VERSION "created by canmatrix"

NS_ :

BS_:

BU_: TCM iBooster HCU CIM SCM Right_Hand_Control Left_Hand_Control GPS VCM IC_2 XM GMRS Radio_CANtool Diagnostic_Tool_Digital_Wrench Information_System_Controller_1 STEERING_CONTROLLER VEHICLE_SECURITY RADIO_Hub ABS Battery_Management_Cntrl_2 Battery_Management_Cntrl_1 Auxiliary_Power_Unit_2 Auxiliary_Power_Unit_1 Electric_Propulsion_Cntrl_Unit_4 Electric_Propulsion_Cntrl_Unit_3 Electric_Propulsion_Cntrl_Unit_2 Electric_Propulsion_Cntrl_Unit_1 ECM IC

BO_ 2432656774 pOperatorSwitchStatus_134: 8 Right_Hand_Control
 SG_ pOperatorButton29 : 58|2@1+ (1,0) [0.0|3.0] "" Vector__XXX
 SG_ pOperatorButton1 : 0|2@1+ (1,0) [0.0|3.0] "" Vector__XXX
 SG_ pOperatorButton2 : 2|2@1+ (1,0) [0.0|3.0] "" Vector__XXX
 SG_ pOperatorButton3 : 4|2@1+ (1,0) [0.0|3.0] "" Vector__XXX
 SG_ pOperatorButton4 : 6|2@1+ (1,0) [0.0|3.0] "" Vector__XXX
 SG_ pOperatorButton5 : 8|2@1+ (1,0) [0.0|3.0] "" Vector__XXX
 SG_ pOperatorButton6 : 10|2@1+ (1,0) [0.0|3.0] "" Vector__XXX
 SG_ pOperatorButton7 : 12|2@1+ (1,0) [0.0|3.0] "" Vector__XXX
 SG_ pOperatorButton8 : 14|2@1+ (1,0) [0.0|3.0] "" Vector__XXX
 SG_ pOperatorButton9 : 16|2@1+ (1,0) [0.0|3.0] "" Vector__XXX
 SG_ pOperatorButton10 : 18|2@1+ (1,0) [0.0|3.0] "" Vector__XXX
 SG_ pOperatorButton11 : 20|2@1+ (1,0) [0.0|3.0] "" Vector__XXX
 SG_ pOperatorButton12 : 22|2@1+ (1,0) [0.0|3.0] "" Vector__XXX
 SG_ pOperatorButton13 : 24|2@1+ (1,0) [0.0|3.0] "" Vector__XXX
 SG_ pOperatorButton14 : 26|2@1+ (1,0) [0.0|3.0] "" Vector__XXX
 SG_ pOperatorButton15 : 28|2@1+ (1,0) [0.0|3.0] "" Vector__XXX
 SG_ pOperatorButton16 : 30|2@1+ (1,0) [0.0|3.0] "" Vector__XXX
 SG_ pOperatorButton17 : 32|2@1+ (1,0) [0.0|3.0] "" Vector__XXX
 SG_ pOperatorButton18 : 34|2@1+ (1,0) [0.0|3.0] "" Vector__XXX
 SG_ pOperatorButton19 : 36|2@1+ (1,0) [0.0|3.0] "" Vector__XXX
 SG_ pOperatorButton20 : 38|2@1+ (1,0) [0.0|3.0] "" Vector__XXX
 SG_ pOperatorButton21 : 40|2@1+ (1,0) [0.0|3.0] "" Vector__XXX
 SG_ pOperatorButton22 : 42|2@1+ (1,0) [0.0|3.0] "" Vector__XXX
 SG_ pOperatorButton23 : 44|2@1+ (1,0) [0.0|3.0] "" Vector__XXX
 SG_ pOperatorButton24 : 46|2@1+ (1,0) [0.0|3.0] "" Vector__XXX
 SG_ pOperatorButton25 : 48|2@1+ (1,0) [0.0|3.0] "" Vector__XXX
 SG_ pOperatorButton26 : 50|2@1+ (1,0) [0.0|3.0] "" Vector__XXX
 SG_ pOperatorButton27 : 52|2@1+ (1,0) [0.0|3.0] "" Vector__XXX
 SG_ pOperatorButton28 : 54|2@1+ (1,0) [0.0|3.0] "" Vector__XXX
 SG_ pSideStandStatus : 56|2@1+ (1,0) [0.0|3.0] "" Vector__XXX

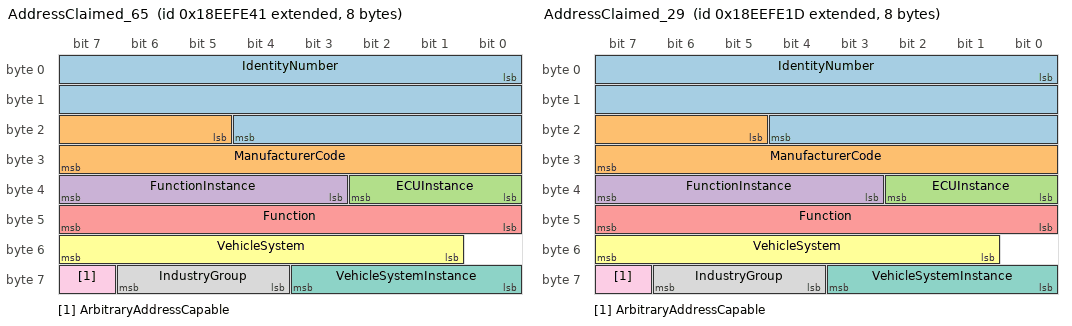
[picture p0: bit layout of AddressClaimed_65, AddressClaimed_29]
BO_ 2565799489 AddressClaimed_65: 8 Information_System_Controller_1
 SG_ IdentityNumber : 0|21@1+ (1,0) [0.0|2097151.0] "" Vector__XXX
 SG_ ManufacturerCode : 21|11@1+ (1,0) [0.0|2047.0] "" Vector__XXX
 SG_ ECUInstance : 32|3@1+ (1,0) [0.0|7.0] "" Vector__XXX
 SG_ FunctionInstance : 35|5@1+ (1,0) [0.0|31.0] "" Vector__XXX
 SG_ Function : 40|8@1+ (1,0) [0.0|255.0] "" Vector__XXX
 SG_ VehicleSystem : 49|7@1+ (1,0) [0.0|127.0] "" Vector__XXX
 SG_ VehicleSystemInstance : 56|4@1+ (1,0) [0.0|15.0] "" Vector__XXX
 SG_ IndustryGroup : 60|3@1+ (1,0) [0.0|7.0] "" Vector__XXX
 SG_ ArbitraryAddressCapable : 63|1@1+ (1,0) [0.0|0.0] "" Vector__XXX

BO_ 2565799453 AddressClaimed_29: 8 VEHICLE_SECURITY
 SG_ IdentityNumber : 0|21@1+ (1,0) [0.0|2097151.0] "" Vector__XXX
 SG_ ManufacturerCode : 21|11@1+ (1,0) [0.0|2047.0] "" Vector__XXX
 SG_ ECUInstance : 32|3@1+ (1,0) [0.0|7.0] "" Vector__XXX
 SG_ FunctionInstance : 35|5@1+ (1,0) [0.0|31.0] "" Vector__XXX
 SG_ Function : 40|8@1+ (1,0) [0.0|255.0] "" Vector__XXX
 SG_ VehicleSystem : 49|7@1+ (1,0) [0.0|127.0] "" Vector__XXX
 SG_ VehicleSystemInstance : 56|4@1+ (1,0) [0.0|15.0] "" Vector__XXX
 SG_ IndustryGroup : 60|3@1+ (1,0) [0.0|7.0] "" Vector__XXX
 SG_ ArbitraryAddressCapable : 63|1@1+ (1,0) [0.0|0.0] "" Vector__XXX

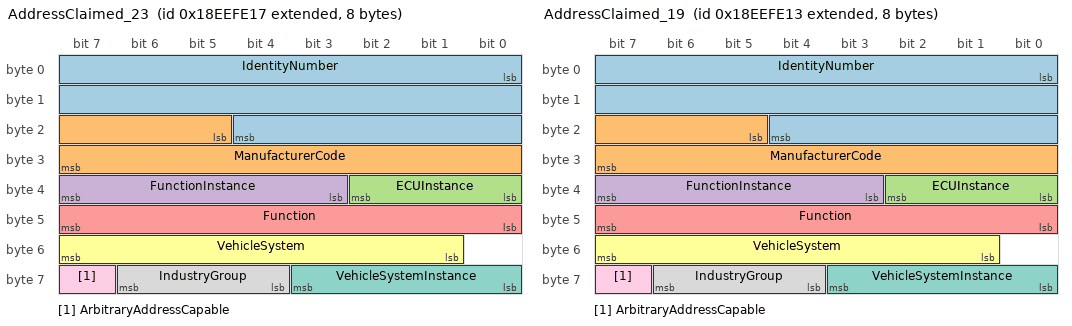
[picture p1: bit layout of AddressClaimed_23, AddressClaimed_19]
BO_ 2565799447 AddressClaimed_23: 8 IC
 SG_ IdentityNumber : 0|21@1+ (1,0) [0.0|2097151.0] "" Vector__XXX
 SG_ ManufacturerCode : 21|11@1+ (1,0) [0.0|2047.0] "" Vector__XXX
 SG_ ECUInstance : 32|3@1+ (1,0) [0.0|7.0] "" Vector__XXX
 SG_ FunctionInstance : 35|5@1+ (1,0) [0.0|31.0] "" Vector__XXX
 SG_ Function : 40|8@1+ (1,0) [0.0|255.0] "" Vector__XXX
 SG_ VehicleSystem : 49|7@1+ (1,0) [0.0|127.0] "" Vector__XXX
 SG_ VehicleSystemInstance : 56|4@1+ (1,0) [0.0|15.0] "" Vector__XXX
 SG_ IndustryGroup : 60|3@1+ (1,0) [0.0|7.0] "" Vector__XXX
 SG_ ArbitraryAddressCapable : 63|1@1+ (1,0) [0.0|0.0] "" Vector__XXX

BO_ 2565799443 AddressClaimed_19: 8 STEERING_CONTROLLER
 SG_ IdentityNumber : 0|21@1+ (1,0) [0.0|2097151.0] "" Vector__XXX
 SG_ ManufacturerCode : 21|11@1+ (1,0) [0.0|2047.0] "" Vector__XXX
 SG_ ECUInstance : 32|3@1+ (1,0) [0.0|7.0] "" Vector__XXX
 SG_ FunctionInstance : 35|5@1+ (1,0) [0.0|31.0] "" Vector__XXX
 SG_ Function : 40|8@1+ (1,0) [0.0|255.0] "" Vector__XXX
 SG_ VehicleSystem : 49|7@1+ (1,0) [0.0|127.0] "" Vector__XXX
 SG_ VehicleSystemInstance : 56|4@1+ (1,0) [0.0|15.0] "" Vector__XXX
 SG_ IndustryGroup : 60|3@1+ (1,0) [0.0|7.0] "" Vector__XXX
 SG_ ArbitraryAddressCapable : 63|1@1+ (1,0) [0.0|0.0] "" Vector__XXX

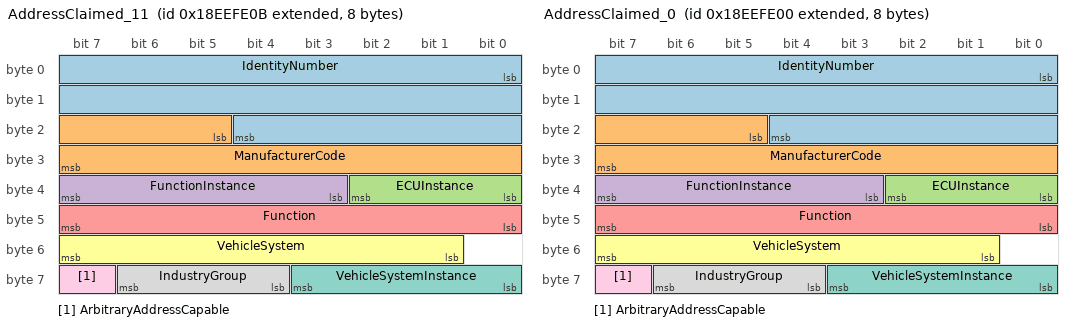
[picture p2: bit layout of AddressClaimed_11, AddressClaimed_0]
BO_ 2565799435 AddressClaimed_11: 8 ABS
 SG_ IdentityNumber : 0|21@1+ (1,0) [0.0|2097151.0] "" Auxiliary_Power_Unit_1
 SG_ ManufacturerCode : 21|11@1+ (1,0) [0.0|2047.0] "" Auxiliary_Power_Unit_1
 SG_ ECUInstance : 32|3@1+ (1,0) [0.0|7.0] "" Auxiliary_Power_Unit_1
 SG_ FunctionInstance : 35|5@1+ (1,0) [0.0|31.0] "" Auxiliary_Power_Unit_1
 SG_ Function : 40|8@1+ (1,0) [0.0|255.0] "" Auxiliary_Power_Unit_1
 SG_ VehicleSystem : 49|7@1+ (1,0) [0.0|127.0] "" Auxiliary_Power_Unit_1
 SG_ VehicleSystemInstance : 56|4@1+ (1,0) [0.0|15.0] "" Auxiliary_Power_Unit_1
 SG_ IndustryGroup : 60|3@1+ (1,0) [0.0|7.0] "" Auxiliary_Power_Unit_1
 SG_ ArbitraryAddressCapable : 63|1@1+ (1,0) [0.0|0.0] "" Auxiliary_Power_Unit_1

BO_ 2565799424 AddressClaimed_0: 8 ECM
 SG_ IdentityNumber : 0|21@1+ (1,0) [0.0|2097151.0] "" Vector__XXX
 SG_ ManufacturerCode : 21|11@1+ (1,0) [0.0|2047.0] "" Vector__XXX
 SG_ ECUInstance : 32|3@1+ (1,0) [0.0|7.0] "" Vector__XXX
 SG_ FunctionInstance : 35|5@1+ (1,0) [0.0|31.0] "" Vector__XXX
 SG_ Function : 40|8@1+ (1,0) [0.0|255.0] "" Vector__XXX
 SG_ VehicleSystem : 49|7@1+ (1,0) [0.0|127.0] "" Vector__XXX
 SG_ VehicleSystemInstance : 56|4@1+ (1,0) [0.0|15.0] "" Vector__XXX
 SG_ IndustryGroup : 60|3@1+ (1,0) [0.0|7.0] "" Vector__XXX
 SG_ ArbitraryAddressCapable : 63|1@1+ (1,0) [0.0|0.0] "" Vector__XXX

BO_ 2631794205 AntiTheftRequest_29: 8 VEHICLE_SECURITY
 SG_ EncryptionIndicatorStates : 1|2@1+ (1,0) [0.0|3.0] "" Vector__XXX
 SG_ AntiTheftDesiredExitModeStates : 3|2@1+ (1,0) [0.0|3.0] "" Vector__XXX
 SG_ AntiTheftCommandStates : 5|3@1+ (1,0) [0.0|7.0] "" Vector__XXX
 SG_ AntiTheftPasswordRepresentation : 8|56@1+ (1,0) [0.0|0.0] "" Vector__XXX

BO_ 2631794199 AntiTheftRequest_23: 8 IC
 SG_ EncryptionIndicatorStates : 1|2@1+ (1,0) [0.0|3.0] "" Vector__XXX
 SG_ AntiTheftDesiredExitModeStates : 3|2@1+ (1,0) [0.0|3.0] "" Vector__XXX
 SG_ AntiTheftCommandStates : 5|3@1+ (1,0) [0.0|7.0] "" Vector__XXX
 SG_ AntiTheftPasswordRepresentation : 8|56@1+ (1,0) [0.0|0.0] "" Vector__XXX

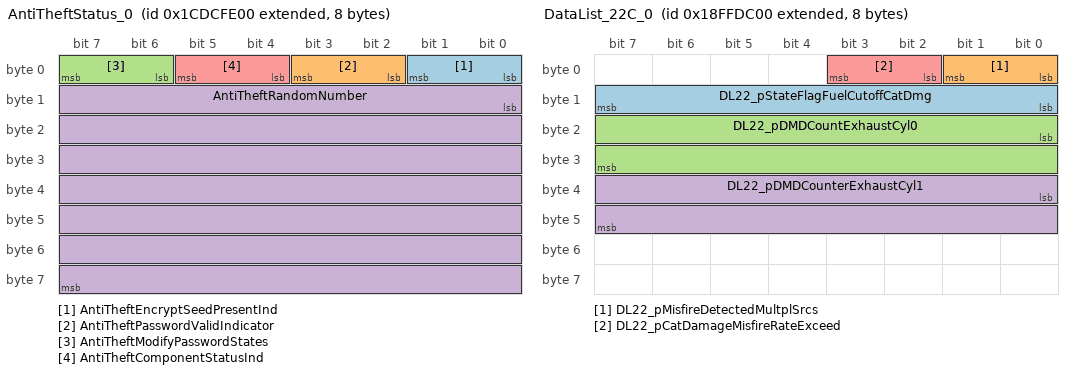
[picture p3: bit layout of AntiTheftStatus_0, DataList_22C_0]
BO_ 2631728640 AntiTheftStatus_0: 8 ECM
 SG_ AntiTheftEncryptSeedPresentInd : 0|2@1+ (1,0) [0.0|3.0] "" Vector__XXX
 SG_ AntiTheftPasswordValidIndicator : 2|2@1+ (1,0) [0.0|3.0] "" Vector__XXX
 SG_ AntiTheftModifyPasswordStates : 6|2@1+ (1,0) [0.0|3.0] "" Vector__XXX
 SG_ AntiTheftRandomNumber : 8|56@1+ (1,0) [0.0|0.0] "" Vector__XXX
 SG_ AntiTheftComponentStatusInd : 4|2@1+ (1,0) [0.0|3.0] "" Vector__XXX

BO_ 2561212031 TextDisplay_127: 8 RADIO_Hub
 SG_ TextDisplayInstructions : 0|4@1+ (1,0) [0.0|15.0] "" Vector__XXX
 SG_ TextDisplayCharacter : 24|40@1+ (1,0) [0.0|1099511627800.0] "ASCII" Vector__XXX
 SG_ TextDisplayIndex : 16|8@1+ (1,0) [0.0|250.0] "Count" Vector__XXX

BO_ 2566905088 DataList_21_00: 8 ECM
 SG_ DL21_pCyl1WeightedCatMisfireDmg : 16|16@1+ (1,0) [0.0|65535.0] "" Vector__XXX
 SG_ DL21_pCyl0WeightedCatMisfireDmg : 0|16@1+ (1,0) [0.0|65535.0] "" Vector__XXX

BO_ 2566904832 DataList_22C_0: 8 ECM
 SG_ DL22_pStateFlagFuelCutoffCatDmg : 8|8@1+ (1,0) [0.0|255.0] "Count" Vector__XXX
 SG_ DL22_pMisfireDetectedMultplSrcs : 0|2@1+ (1,0) [0.0|3.0] "" Vector__XXX
 SG_ DL22_pDMDCountExhaustCyl0 : 16|16@1+ (1,0) [0.0|65535.0] "" Vector__XXX
 SG_ DL22_pDMDCounterExhaustCyl1 : 32|16@1+ (1,0) [0.0|65535.0] "" Vector__XXX
 SG_ DL22_pCatDamageMisfireRateExceed : 2|2@1+ (1,0) [0.0|3.0] "" Vector__XXX

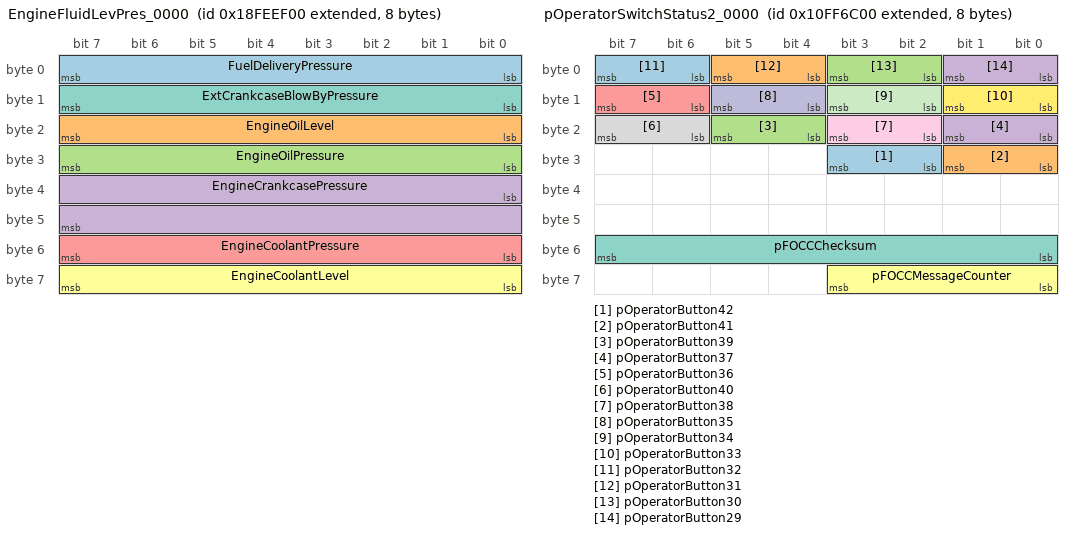
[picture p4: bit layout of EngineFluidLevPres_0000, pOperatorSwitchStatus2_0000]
BO_ 2566844160 EngineFluidLevPres_0000: 8 ECM
 SG_ FuelDeliveryPressure : 0|8@1+ (4,0) [0.0|1000.0] "kPa" Vector__XXX
 SG_ EngineOilLevel : 16|8@1+ (0.4,0) [0.0|100.0] "%" Vector__XXX
 SG_ EngineOilPressure : 24|8@1+ (4,0) [0.0|1000.0] "kPa" Vector__XXX
 SG_ EngineCrankcasePressure : 32|16@1+ (0.0078125,-250) [-250.0|251.99] "kPa" Vector__XXX
 SG_ EngineCoolantPressure : 48|8@1+ (2,0) [0.0|500.0] "kPa" Vector__XXX
 SG_ EngineCoolantLevel : 56|8@1+ (0.4,0) [0.0|100.0] "%" Vector__XXX
 SG_ ExtCrankcaseBlowByPressure : 8|8@1+ (0.05,0) [0.0|12.5] "kPa" Vector__XXX

BO_ 2432658432 pOperatorSwitchStatus2_0000: 8 ECM
 SG_ pOperatorButton42 : 26|2@1+ (1,0) [0.0|3.0] "" Vector__XXX
 SG_ pOperatorButton41 : 24|2@1+ (1,0) [0.0|3.0] "" Vector__XXX
 SG_ pOperatorButton39 : 20|2@1+ (1,0) [0.0|3.0] "" Vector__XXX
 SG_ pOperatorButton37 : 16|2@1+ (1,0) [0.0|3.0] "" Vector__XXX
 SG_ pOperatorButton36 : 14|2@1+ (1,0) [0.0|3.0] "" Vector__XXX
 SG_ pFOCCMessageCounter : 56|4@1+ (1,0) [0.0|15.0] "" Vector__XXX
 SG_ pFOCCChecksum : 48|8@1+ (1,0) [0.0|255.0] "" Vector__XXX
 SG_ pOperatorButton40 : 22|2@1+ (1,0) [0.0|3.0] "" Vector__XXX
 SG_ pOperatorButton38 : 18|2@1+ (1,0) [0.0|3.0] "" Vector__XXX
 SG_ pOperatorButton35 : 12|2@1+ (1,0) [0.0|3.0] "" Vector__XXX
 SG_ pOperatorButton34 : 10|2@1+ (1,0) [0.0|3.0] "" Vector__XXX
 SG_ pOperatorButton33 : 8|2@1+ (1,0) [0.0|3.0] "" Vector__XXX
 SG_ pOperatorButton32 : 6|2@1+ (1,0) [0.0|3.0] "" Vector__XXX
 SG_ pOperatorButton31 : 4|2@1+ (1,0) [0.0|3.0] "" Vector__XXX
 SG_ pOperatorButton30 : 2|2@1+ (1,0) [0.0|3.0] "" Vector__XXX
 SG_ pOperatorButton29 : 0|2@1+ (1,0) [0.0|3.0] "" Vector__XXX

BO_ 2633984512 pDriveSystemStatus_0: 8 ECM
 SG_ pHeatedGripEnable : 48|2@1+ (1,0) [0.0|3.0] "" Vector__XXX
 SG_ pSideStandStatus : 36|2@1+ (1,0) [0.0|3.0] "" Vector__XXX
 SG_ pTetherSwitchStatus : 46|2@1+ (1,0) [0.0|3.0] "" Vector__XXX
 SG_ pLowFuelIndicatorStatus : 10|2@1+ (1,0) [0.0|3.0] "" Vector__XXX
 SG_ pOperatorNotInOperatingStation : 38|2@1+ (1,0) [0.0|3.0] "" Vector__XXX
 SG_ pParkBrakeIndicatorStatus : 40|3@1+ (1,0) [0.0|7.0] "" Vector__XXX
 SG_ pADCRequested : 34|2@1+ (1,0) [0.0|3.0] "" Vector__XXX
 SG_ pAWDModeRequested : 32|2@1+ (1,0) [0.0|3.0] "" Vector__XXX
 SG_ pRWDModeRequested : 30|2@1+ (1,0) [0.0|3.0] "" Vector__XXX
 SG_ pTurfModeRequested : 28|2@1+ (1,0) [0.0|3.0] "" Vector__XXX
 SG_ pADCStatus : 0|2@1+ (1,0) [0.0|3.0] "" Vector__XXX
 SG_ pTreadleNeutralStatus : 2|2@1+ (1,0) [0.0|3.0] "" Vector__XXX
 SG_ pTreadleReverseStatus : 4|2@1+ (1,0) [0.0|3.0] "" Vector__XXX
 SG_ pSecurityLightStatus : 6|2@1+ (1,0) [0.0|3.0] "" Vector__XXX
 SG_ pHighBeamIndicatorStatus : 8|2@1+ (1,0) [0.0|3.0] "" Vector__XXX
 SG_ pHeatedGripsPercentage : 16|8@1+ (0.4,0) [0.0|100.0] "%" Vector__XXX
 SG_ pCruiseControlSetStatus : 24|2@1+ (1,0) [0.0|3.0] "" Vector__XXX
 SG_ pSeatBeltIndicatorStatus : 12|3@1+ (1,0) [0.0|7.0] "" Vector__XXX

BO_ 2566847511 DashDisplay_23: 8 IC
 SG_ WasherFluidLevel : 0|8@1+ (0.4,0) [0.0|100.0] "%" Vector__XXX
 SG_ FuelLevel : 8|8@1+ (0.4,0) [0.0|100.0] "%" Vector__XXX
 SG_ FuelFilterDiffPressure : 16|8@1+ (2,0) [0.0|500.0] "kPa" Vector__XXX
 SG_ EngineOilFilterDiffPressure : 24|8@1+ (0.5,0) [0.0|125.0] "kPa" Vector__XXX
 SG_ CargoAmbientTemperature : 32|16@1+ (0.03125,-273) [-273.0|1735.0] "°C" Vector__XXX

BO_ 2566845719 AmbientConditions_23: 8 IC
 SG_ DL_BarometricPressure : 0|16@1+ (0.007813,0) [0.0|511.99] "kPa" Vector__XXX
 SG_ CabInteriorTemperature : 8|16@1+ (0.03125,-273) [-273.0|1735.0] "°C" Vector__XXX
 SG_ AmbientAirTemperature : 24|16@1+ (0.03125,-273) [-273.0|1735.0] "°C" Vector__XXX
 SG_ EngineAirInletTemperature : 40|8@1+ (1,-40) [-40.0|210.0] "°C" Vector__XXX
 SG_ RoadSurfaceTemperature : 48|16@1+ (0.03125,-273) [-273.0|1734.96875] "°C" Vector__XXX

BO_ 2566847488 DashDisplay_0: 8 ECM
 SG_ WasherFluidLevel : 0|8@1+ (0.4,0) [0.0|100.0] "%" Vector__XXX
 SG_ FuelLevel : 8|8@1+ (0.4,0) [0.0|100.0] "%" Vector__XXX
 SG_ FuelFilterDiffPressure : 16|8@1+ (2,0) [0.0|500.0] "kPa" Vector__XXX
 SG_ EngineOilFilterDiffPressure : 24|8@1+ (0.5,0) [0.0|125.0] "kPa" Vector__XXX
 SG_ CargoAmbientTemperature : 32|16@1+ (0.03125,-273) [-273.0|1735.0] "°C" Vector__XXX

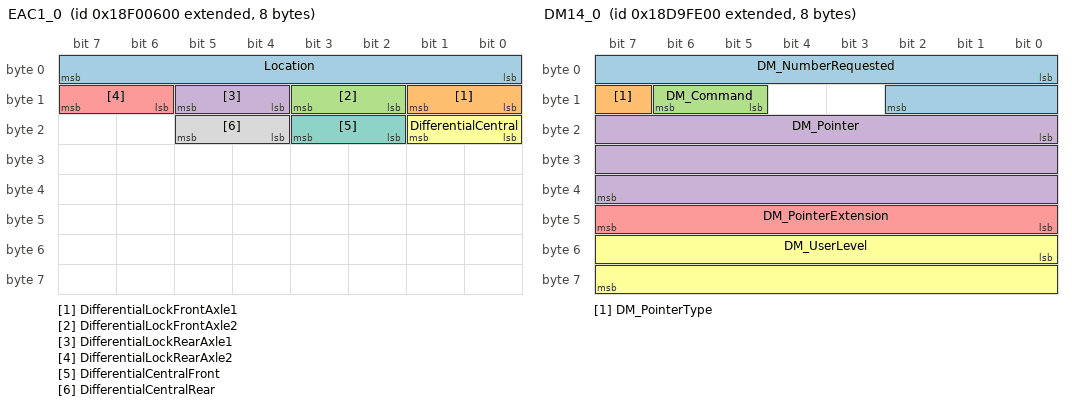
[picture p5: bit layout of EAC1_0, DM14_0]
BO_ 2565867008 EAC1_0: 8 ECM
 SG_ Location : 0|8@1+ (1,0) [0.0|255.0] "" Vector__XXX
 SG_ DifferentialLockFrontAxle1 : 8|2@1+ (1,0) [0.0|3.0] "" Vector__XXX
 SG_ DifferentialLockFrontAxle2 : 10|2@1+ (1,0) [0.0|3.0] "" Vector__XXX
 SG_ DifferentialLockRearAxle1 : 12|2@1+ (1,0) [0.0|3.0] "" Vector__XXX
 SG_ DifferentialLockRearAxle2 : 14|2@1+ (1,0) [0.0|3.0] "" Vector__XXX
 SG_ DifferentialCentral : 16|2@1+ (1,0) [0.0|3.0] "" Vector__XXX
 SG_ DifferentialCentralFront : 18|2@1+ (1,0) [0.0|3.0] "" Vector__XXX
 SG_ DifferentialCentralRear : 20|2@1+ (1,0) [0.0|3.0] "" Vector__XXX

BO_ 2566841600 EngineHoursRevolutions_0: 8 ECM
 SG_ EngTotalHoursOfOper : 0|32@1+ (0.05,0) [0.0|210554060.75] "h" Vector__XXX
 SG_ TotalEngineRevolutions : 32|32@1+ (1000,0) [0.0|4211081215000.0] "r" Vector__XXX

BO_ 2566832407 HiResVehicleDist_23: 8 IC
 SG_ HighResolTotalVehicleDistance : 0|32@1+ (0.005,0) [0.0|21055406.0] "km" Vector__XXX
 SG_ HighResolTripDistance : 32|32@1+ (0.005,0) [0.0|21055406.0] "km" Vector__XXX

BO_ 2566834688 DM1_0: 22 ECM
 SG_ DM_ProtectLampStatus : 0|2@1+ (1,0) [0.0|3.0] "" Vector__XXX
 SG_ DM_RedStopLampState : 4|2@1+ (1,0) [0.0|3.0] "" Vector__XXX
 SG_ DM_AmberWrningLmpStatus : 2|2@1+ (1,0) [0.0|3.0] "" Vector__XXX
 SG_ DM_MalfuncnIndicatorLampStatus : 6|2@1+ (1,0) [0.0|3.0] "" Vector__XXX
 SG_ DM_FlashRedStopLamp : 12|2@1+ (1,0) [0.0|3.0] "" Vector__XXX
 SG_ DM_FlashMalfuncIndicatorLamp : 14|2@1+ (1,0) [0.0|3.0] "" Vector__XXX
 SG_ DTC5 : 144|32@1+ (1,0) [0.0|4294967295.0] "" Vector__XXX
 SG_ DTC4 : 112|32@1+ (1,0) [0.0|4294967295.0] "" Vector__XXX
 SG_ DTC3 : 80|32@1+ (1,0) [0.0|4294967295.0] "" Vector__XXX
 SG_ DTC2 : 48|32@1+ (1,0) [0.0|4294967295.0] "" Vector__XXX
 SG_ DTC1 : 16|32@1+ (1,0) [0.0|4294967295.0] "" Vector__XXX
 SG_ DM_FlashProtectLamp : 8|2@1+ (1,0) [0.0|3.0] "" Vector__XXX
 SG_ DM_FlashAmberWarningLamp : 10|2@1+ (1,0) [0.0|3.0] "" Vector__XXX

BO_ 2564423168 DM14_0: 8 ECM
 SG_ DM_NumberRequested : 0|11@1+ (1,0) [0.0|2047.0] "" Vector__XXX
 SG_ DM_PointerType : 15|1@1+ (1,0) [0.0|1.0] "" Vector__XXX
 SG_ DM_Command : 13|2@1+ (1,0) [0.0|3.0] "" Vector__XXX
 SG_ DM_Pointer : 16|24@1+ (1,0) [0.0|16777215.0] "" Vector__XXX
 SG_ DM_PointerExtension : 40|8@1+ (1,0) [0.0|255.0] "" Vector__XXX
 SG_ DM_UserLevel : 48|16@1+ (1,0) [0.0|65535.0] "" Vector__XXX

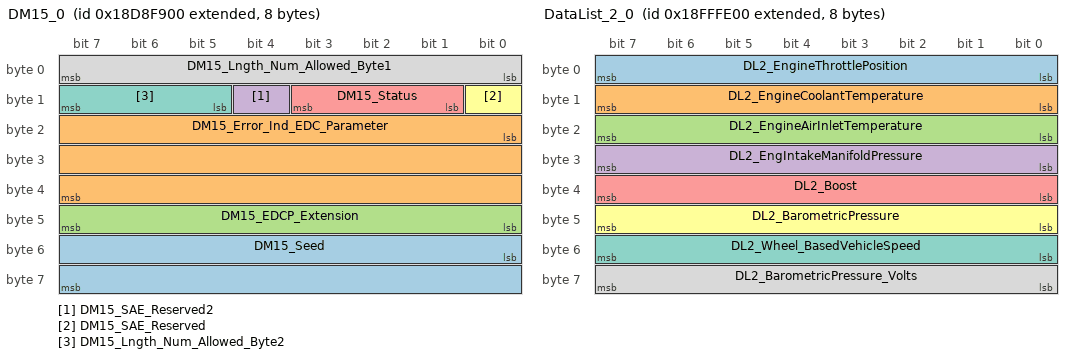
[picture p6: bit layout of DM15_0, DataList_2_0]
BO_ 2564356352 DM15_0: 8 ECM
 SG_ DM15_Seed : 48|16@1+ (1,0) [0.0|65535.0] "" Vector__XXX
 SG_ DM15_Error_Ind_EDC_Parameter : 16|24@1+ (1,0) [0.0|16777215.0] "" Vector__XXX
 SG_ DM15_EDCP_Extension : 40|8@1+ (1,0) [0.0|255.0] "" Vector__XXX
 SG_ DM15_SAE_Reserved2 : 12|1@1+ (1,0) [1.0|1.0] "" Vector__XXX
 SG_ DM15_Status : 9|3@1+ (1,0) [0.0|7.0] "" Vector__XXX
 SG_ DM15_SAE_Reserved : 8|1@1+ (1,0) [1.0|1.0] "" Vector__XXX
 SG_ DM15_Lngth_Num_Allowed_Byte2 : 13|3@1+ (1,0) [0.0|7.0] "" Vector__XXX
 SG_ DM15_Lngth_Num_Allowed_Byte1 : 0|8@1+ (1,0) [0.0|255.0] "" Vector__XXX

BO_ 2633883392 FrontWheelDriveStatus_0: 8 ECM
 SG_ FrtWheelDriveActuatorStatus : 0|2@1+ (1,0) [0.0|3.0] "" Vector__XXX

BO_ 2432656640 pOperatorSwitchStatus_0: 8 ECM
 SG_ pOperatorButton29 : 58|2@1+ (1,0) [0.0|3.0] "" Vector__XXX
 SG_ pOperatorButton1 : 0|2@1+ (1,0) [0.0|3.0] "" Vector__XXX
 SG_ pOperatorButton2 : 2|2@1+ (1,0) [0.0|3.0] "" Vector__XXX
 SG_ pOperatorButton3 : 4|2@1+ (1,0) [0.0|3.0] "" Vector__XXX
 SG_ pOperatorButton4 : 6|2@1+ (1,0) [0.0|3.0] "" Vector__XXX
 SG_ pOperatorButton5 : 8|2@1+ (1,0) [0.0|3.0] "" Vector__XXX
 SG_ pOperatorButton6 : 10|2@1+ (1,0) [0.0|3.0] "" Vector__XXX
 SG_ pOperatorButton7 : 12|2@1+ (1,0) [0.0|3.0] "" Vector__XXX
 SG_ pOperatorButton8 : 14|2@1+ (1,0) [0.0|3.0] "" Vector__XXX
 SG_ pOperatorButton9 : 16|2@1+ (1,0) [0.0|3.0] "" Vector__XXX
 SG_ pOperatorButton10 : 18|2@1+ (1,0) [0.0|3.0] "" Vector__XXX
 SG_ pOperatorButton11 : 20|2@1+ (1,0) [0.0|3.0] "" Vector__XXX
 SG_ pOperatorButton12 : 22|2@1+ (1,0) [0.0|3.0] "" Vector__XXX
 SG_ pOperatorButton13 : 24|2@1+ (1,0) [0.0|3.0] "" Vector__XXX
 SG_ pOperatorButton14 : 26|2@1+ (1,0) [0.0|3.0] "" Vector__XXX
 SG_ pOperatorButton15 : 28|2@1+ (1,0) [0.0|3.0] "" Vector__XXX
 SG_ pOperatorButton16 : 30|2@1+ (1,0) [0.0|3.0] "" Vector__XXX
 SG_ pOperatorButton17 : 32|2@1+ (1,0) [0.0|3.0] "" Vector__XXX
 SG_ pOperatorButton18 : 34|2@1+ (1,0) [0.0|3.0] "" Vector__XXX
 SG_ pOperatorButton19 : 36|2@1+ (1,0) [0.0|3.0] "" Vector__XXX
 SG_ pOperatorButton20 : 38|2@1+ (1,0) [0.0|3.0] "" Vector__XXX
 SG_ pOperatorButton21 : 40|2@1+ (1,0) [0.0|3.0] "" Vector__XXX
 SG_ pOperatorButton22 : 42|2@1+ (1,0) [0.0|3.0] "" Vector__XXX
 SG_ pOperatorButton23 : 44|2@1+ (1,0) [0.0|3.0] "" Vector__XXX
 SG_ pOperatorButton24 : 46|2@1+ (1,0) [0.0|3.0] "" Vector__XXX
 SG_ pOperatorButton25 : 48|2@1+ (1,0) [0.0|3.0] "" Vector__XXX
 SG_ pOperatorButton26 : 50|2@1+ (1,0) [0.0|3.0] "" Vector__XXX
 SG_ pOperatorButton27 : 52|2@1+ (1,0) [0.0|3.0] "" Vector__XXX
 SG_ pOperatorButton28 : 54|2@1+ (1,0) [0.0|3.0] "" Vector__XXX
 SG_ pSideStandStatus : 56|2@1+ (1,0) [0.0|3.0] "" Vector__XXX

BO_ 2365548032 pEngICS_0: 8 ECM
 SG_ pHighIdleState : 18|2@1+ (1,0) [0.0|3.0] "" Vector__XXX
 SG_ pEngineSpeed : 0|16@1+ (1,0) [0.0|64255.0] "rpm" Vector__XXX
 SG_ pStuckThrottle : 16|2@1+ (1,0) [0.0|3.0] "" Vector__XXX
 SG_ pFuelRange : 24|16@1+ (1,0) [0.0|64255.0] "km" Vector__XXX

BO_ 2566913792 DataList_1_0: 8 ECM
 SG_ DL1_EngineThrottlePosition : 0|16@1+ (0.01,0) [0.0|655.35] "V" Vector__XXX
 SG_ DL1_EngineSpeed : 16|16@1+ (1,0) [0.0|65535.0] "rpm" Vector__XXX
 SG_ DL1_EngineCoolantTemperature : 32|8@1+ (0.025,0) [0.0|6.375] "V" Vector__XXX
 SG_ DL1_EngIntakeManifoldPressure : 40|8@1+ (0.025,0) [0.0|6.375] "V" Vector__XXX
 SG_ DL1_EngineAirInletTemperature : 48|8@1+ (0.025,0) [0.0|6.375] "V" Vector__XXX
 SG_ DL1_BatteryPotential : 56|8@1+ (0.1,0) [0.0|25.5] "V" Vector__XXX

BO_ 2566913536 DataList_2_0: 8 ECM
 SG_ DL2_EngineThrottlePosition : 0|8@1+ (0.4,0) [0.0|100.0] "%" Vector__XXX
 SG_ DL2_EngineCoolantTemperature : 8|8@1+ (1,-40) [-40.0|210.0] "°C" Vector__XXX
 SG_ DL2_EngineAirInletTemperature : 16|8@1+ (1,-40) [-40.0|210.0] "°C" Vector__XXX
 SG_ DL2_EngIntakeManifoldPressure : 24|8@1+ (2,0) [0.0|500.0] "kPa" Vector__XXX
 SG_ DL2_Boost : 32|8@1+ (2,0) [0.0|500.0] "kPa" Vector__XXX
 SG_ DL2_BarometricPressure : 40|8@1+ (0.5,0) [0.0|125.0] "kPa" Vector__XXX
 SG_ DL2_Wheel_BasedVehicleSpeed : 48|8@1+ (1,0) [0.0|255.0] "km/h" Vector__XXX
 SG_ DL2_BarometricPressure_Volts : 56|8@1+ (0.025,0) [0.0|6.375] "V" Vector__XXX

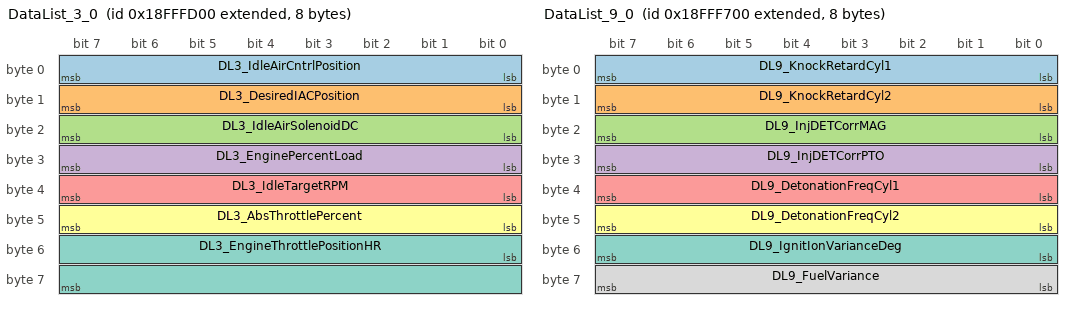
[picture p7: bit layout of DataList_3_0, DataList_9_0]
BO_ 2566913280 DataList_3_0: 8 ECM
 SG_ DL3_IdleAirCntrlPosition : 0|8@1+ (1,0) [0.0|255.0] "Step" Vector__XXX
 SG_ DL3_DesiredIACPosition : 8|8@1+ (1,0) [0.0|255.0] "Step" Vector__XXX
 SG_ DL3_IdleAirSolenoidDC : 16|8@1+ (0.4,0) [0.0|102.0] "%" Vector__XXX
 SG_ DL3_EnginePercentLoad : 24|8@1+ (0.4,0) [0.0|102.0] "%" Vector__XXX
 SG_ DL3_IdleTargetRPM : 32|8@1+ (10,0) [0.0|2550.0] "RPM" Vector__XXX
 SG_ DL3_AbsThrottlePercent : 40|8@1+ (0.4,0) [0.0|102.0] "%" Vector__XXX
 SG_ DL3_EngineThrottlePositionHR : 48|16@1+ (0.001,0) [0.0|65.535] "V" Vector__XXX

BO_ 2566911744 DataList_9_0: 8 ECM
 SG_ DL9_KnockRetardCyl1 : 0|8@1+ (1,0) [0.0|255.0] "Deg" Vector__XXX
 SG_ DL9_KnockRetardCyl2 : 8|8@1+ (1,0) [0.0|255.0] "Deg" Vector__XXX
 SG_ DL9_InjDETCorrMAG : 16|8@1+ (0.1,100) [100.0|125.5] "%" Vector__XXX
 SG_ DL9_InjDETCorrPTO : 24|8@1+ (0.1,100) [100.0|125.5] "%" Vector__XXX
 SG_ DL9_DetonationFreqCyl1 : 32|8@1+ (0.4,0) [0.0|102.0] "%" Vector__XXX
 SG_ DL9_DetonationFreqCyl2 : 40|8@1+ (0.4,0) [0.0|102.0] "%" Vector__XXX
 SG_ DL9_IgnitIonVarianceDeg : 48|8@1+ (0.2,-10) [-10.0|41.0] "Deg" Vector__XXX
 SG_ DL9_FuelVariance : 56|8@1+ (1,0) [0.0|255.0] "%" Vector__XXX

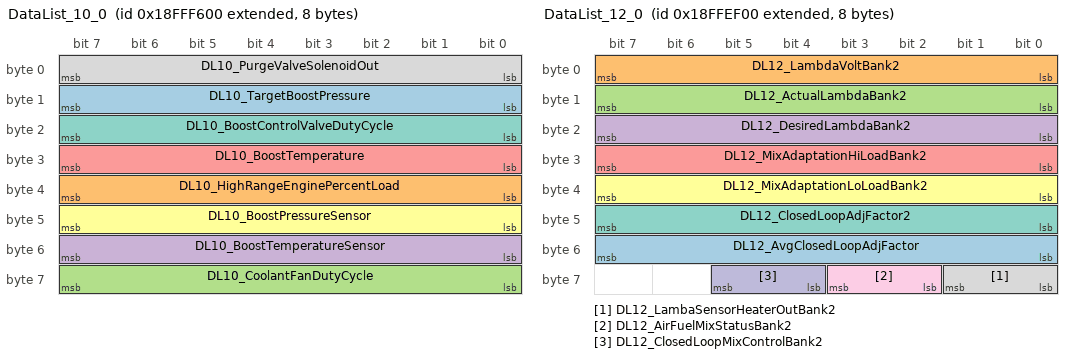
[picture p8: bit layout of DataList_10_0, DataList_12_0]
BO_ 2566911488 DataList_10_0: 8 ECM
 SG_ DL10_TargetBoostPressure : 8|8@1+ (2,0) [0.0|510.0] "kPa" Vector__XXX
 SG_ DL10_HighRangeEnginePercentLoad : 32|8@1+ (2,0) [0.0|510.0] "%" Vector__XXX
 SG_ DL10_CoolantFanDutyCycle : 56|8@1+ (0.4,0) [0.0|102.0] "%" Vector__XXX
 SG_ DL10_BoostTemperatureSensor : 48|8@1+ (0.025,0) [0.0|6.375] "Volts" Vector__XXX
 SG_ DL10_BoostTemperature : 24|8@1+ (1,-40) [-40.0|215.0] "degC" Vector__XXX
 SG_ DL10_BoostPressureSensor : 40|8@1+ (0.025,0) [0.0|6.375] "Volts" Vector__XXX
 SG_ DL10_BoostControlValveDutyCycle : 16|8@1+ (0.4,0) [0.0|102.0] "%" Vector__XXX
 SG_ DL10_PurgeValveSolenoidOut : 0|8@1+ (0.4,0) [0.0|102.0] "%" Vector__XXX

BO_ 2566909952 DataList_11_0: 8 ECM
 SG_ DL11_InterFanDriver1DutyCycle : 48|8@1+ (0.4,0) [0.0|102.0] "%" Vector__XXX
 SG_ DL11_EngineOilPressureSensor : 40|8@1+ (0.025,0) [0.0|6.375] "Volts" Vector__XXX
 SG_ DL11_EngineOilPressure : 32|8@1+ (4,0) [0.0|1020.0] "kPa" Vector__XXX
 SG_ DL11_EngRunTime : 0|16@1+ (2,0) [0.0|131070.0] "Min" Vector__XXX
 SG_ DL11_EngRunTimeKeyOn : 16|16@1+ (2,0) [0.0|131070.0] "Min" Vector__XXX

BO_ 2566909696 DataList_12_0: 8 ECM
 SG_ DL12_AvgClosedLoopAdjFactor : 48|8@1+ (0.0078125,0) [0.0|1.9921875] "" Vector__XXX
 SG_ DL12_LambdaVoltBank2 : 0|8@1+ (0.02,0) [0.0|5.0] "V" Vector__XXX
 SG_ DL12_ActualLambdaBank2 : 8|8@1+ (0.0078125,0) [0.0|1.95] "Ratio" Vector__XXX
 SG_ DL12_DesiredLambdaBank2 : 16|8@1+ (0.0078125,0) [0.0|1.9921875] "Ratio" Vector__XXX
 SG_ DL12_MixAdaptationHiLoadBank2 : 24|8@1+ (0.0078125,0) [0.0|1.9921875] "" Vector__XXX
 SG_ DL12_MixAdaptationLoLoadBank2 : 32|8@1+ (1,0) [0.0|0.0] "" Vector__XXX
 SG_ DL12_ClosedLoopAdjFactor2 : 40|8@1+ (0.0078125,0) [0.0|1.9921875] "Ratio" Vector__XXX
 SG_ DL12_LambaSensorHeaterOutBank2 : 56|2@1+ (1,0) [0.0|3.0] "" Vector__XXX
 SG_ DL12_AirFuelMixStatusBank2 : 58|2@1+ (1,0) [0.0|3.0] "" Vector__XXX
 SG_ DL12_ClosedLoopMixControlBank2 : 60|2@1+ (1,0) [0.0|3.0] "" Vector__XXX

BO_ 2566909440 DataList_13_0: 8 ECM
 SG_ DL13_PortInjector1Time : 0|16@1+ (1,0) [0.0|65535.0] "us" Vector__XXX
 SG_ DL13_CaseInjector1Time : 16|16@1+ (1,0) [0.0|65535.0] "us" Vector__XXX
 SG_ DL13_Cyl1IgnTiming : 32|8@1+ (1,-125) [-125.0|130.0] "Deg-BTDC" Vector__XXX
 SG_ DL13_Cyl1BaseIgnTiming : 40|8@1+ (1,-125) [-125.0|130.0] "Deg-BTDC" Vector__XXX
 SG_ DL13_Cyl1IgnCoilDwell : 48|16@1+ (1,0) [0.0|65535.0] "us" Vector__XXX

BO_ 2566909184 DataList_14_0: 8 ECM
 SG_ DL14_PortInjector2Time : 0|16@1+ (1,0) [0.0|65535.0] "us" Vector__XXX
 SG_ DL14_CaseInjector2Time : 16|16@1+ (1,0) [0.0|65535.0] "us" Vector__XXX
 SG_ DL14_Cyl2IgnTiming : 32|8@1+ (1,-125) [-125.0|130.0] "Deg-BTDC" Vector__XXX
 SG_ DL14_Cyl2BaseIgnTiming : 40|8@1+ (1,-125) [-125.0|130.0] "Deg-BTDC" Vector__XXX
 SG_ DL14_Cyl2IgnCoilDwell : 48|16@1+ (1,0) [0.0|65535.0] "us" Vector__XXX

BO_ 2566908928 DataList_15_0: 8 ECM
 SG_ DL15_ExhaustValveSetPWM : 32|8@1+ (0.4,0) [0.0|102.0] "%" Vector__XXX
 SG_ DL15_ExhaustTemperature : 0|16@1+ (1,0) [0.0|65535.0] "°C" Vector__XXX
 SG_ DL15_InjectorIgnitionSupplyVolt : 16|8@1+ (0.1,0) [0.0|25.5] "V" Vector__XXX
 SG_ DL15_ElecStartOptBattVolt : 24|8@1+ (0.1,0) [0.0|25.5] "V" Vector__XXX

BO_ 2566908672 DataList_16_0: 8 ECM
 SG_ DL16_PedalPosSensor1 : 0|16@1+ (0.01,0) [0.0|655.35] "V" Vector__XXX
 SG_ DL16_PedalPosSensor2 : 16|16@1+ (0.01,0) [0.0|655.35] "V" Vector__XXX

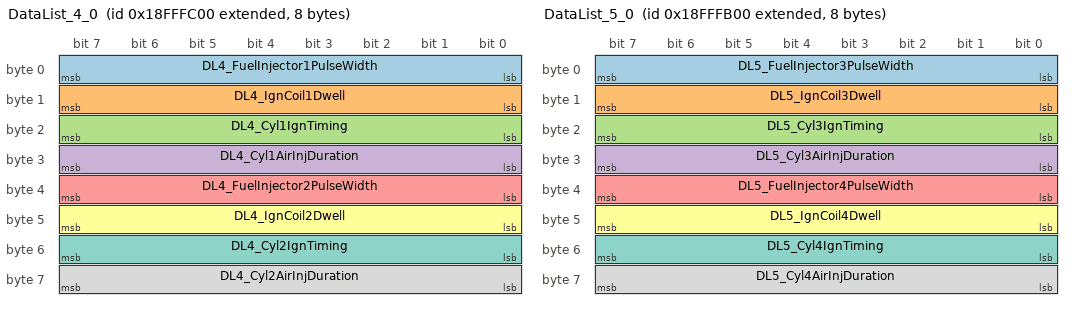
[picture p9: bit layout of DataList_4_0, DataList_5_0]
BO_ 2566913024 DataList_4_0: 8 ECM
 SG_ DL4_FuelInjector1PulseWidth : 0|8@1+ (1,0) [0.0|255.0] "ms" Vector__XXX
 SG_ DL4_IgnCoil1Dwell : 8|8@1+ (0.1,0) [0.0|25.5] "ms" Vector__XXX
 SG_ DL4_Cyl1IgnTiming : 16|8@1+ (1,-128) [-128.0|127.0] "Deg" Vector__XXX
 SG_ DL4_Cyl1AirInjDuration : 24|8@1+ (1,0) [0.0|255.0] "ms" Vector__XXX
 SG_ DL4_FuelInjector2PulseWidth : 32|8@1+ (1,0) [0.0|255.0] "ms" Vector__XXX
 SG_ DL4_IgnCoil2Dwell : 40|8@1+ (0.1,0) [0.0|25.5] "ms" Vector__XXX
 SG_ DL4_Cyl2IgnTiming : 48|8@1+ (1,-128) [-128.0|127.0] "Deg" Vector__XXX
 SG_ DL4_Cyl2AirInjDuration : 56|8@1+ (1,0) [0.0|255.0] "ms" Vector__XXX

BO_ 2566912768 DataList_5_0: 8 ECM
 SG_ DL5_FuelInjector3PulseWidth : 0|8@1+ (1,0) [0.0|255.0] "ms" Vector__XXX
 SG_ DL5_IgnCoil3Dwell : 8|8@1+ (0.1,0) [0.0|25.5] "ms" Vector__XXX
 SG_ DL5_Cyl3IgnTiming : 16|8@1+ (1,-128) [-128.0|127.0] "Deg" Vector__XXX
 SG_ DL5_Cyl3AirInjDuration : 24|8@1+ (1,0) [0.0|255.0] "ms" Vector__XXX
 SG_ DL5_FuelInjector4PulseWidth : 32|8@1+ (1,0) [0.0|255.0] "ms" Vector__XXX
 SG_ DL5_IgnCoil4Dwell : 40|8@1+ (0.1,0) [0.0|25.5] "ms" Vector__XXX
 SG_ DL5_Cyl4IgnTiming : 48|8@1+ (1,-128) [-128.0|127.0] "Deg" Vector__XXX
 SG_ DL5_Cyl4AirInjDuration : 56|8@1+ (1,0) [0.0|255.0] "ms" Vector__XXX

BO_ 2566912512 DataList_6_0: 8 ECM
 SG_ DL6_TwoSpdShftCoilDutyCycle : 48|8@1+ (0.4,0) [0.0|100.0] "%" Vector__XXX
 SG_ DL6_PTOSpeed : 32|16@1+ (1,0) [0.0|65535.0] "RPM" Vector__XXX
 SG_ DL6_GearVolts : 0|8@1+ (0.1,0) [0.0|25.5] "V" Vector__XXX
 SG_ DL6_RolloverVolts : 8|8@1+ (0.025,0) [0.0|6.375] "V" Vector__XXX
 SG_ DL6_ThrottleReleaseInputVolts : 16|8@1+ (0.1,0) [0.0|25.5] "V" Vector__XXX
 SG_ DL6_FuelTypeSensorVolts : 24|8@1+ (0.1,0) [0.0|25.5] "V" Vector__XXX

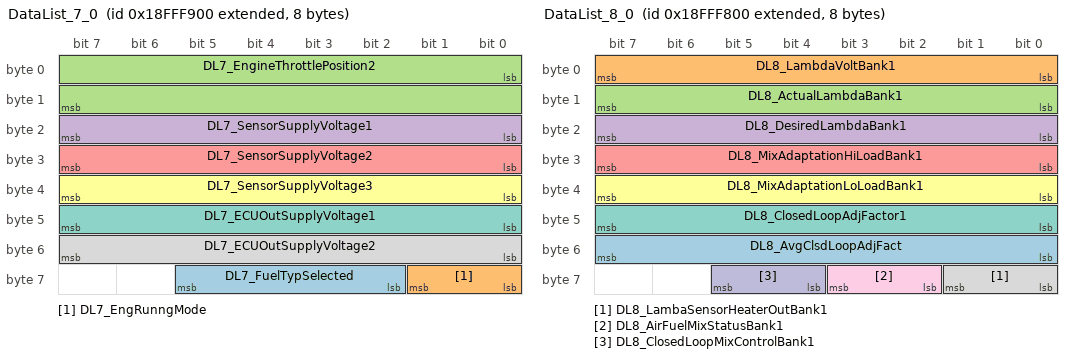
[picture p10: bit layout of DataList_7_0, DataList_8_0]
BO_ 2566912256 DataList_7_0: 8 ECM
 SG_ DL7_FuelTypSelected : 58|4@1+ (1,0) [0.0|15.0] "" Vector__XXX
 SG_ DL7_EngRunngMode : 56|2@1- (1,0) [0.0|3.0] "" Vector__XXX
 SG_ DL7_EngineThrottlePosition2 : 0|16@1+ (0.01,0) [0.0|655.35] "V" Vector__XXX
 SG_ DL7_SensorSupplyVoltage1 : 16|8@1+ (0.05,0) [0.0|12.75] "V" Vector__XXX
 SG_ DL7_SensorSupplyVoltage2 : 24|8@1+ (0.05,0) [0.0|12.75] "V" Vector__XXX
 SG_ DL7_SensorSupplyVoltage3 : 32|8@1+ (0.05,0) [0.0|12.75] "V" Vector__XXX
 SG_ DL7_ECUOutSupplyVoltage1 : 40|8@1+ (0.05,0) [0.0|12.75] "V" Vector__XXX
 SG_ DL7_ECUOutSupplyVoltage2 : 48|8@1+ (0.05,0) [0.0|12.75] "V" Vector__XXX

BO_ 2566912000 DataList_8_0: 8 ECM
 SG_ DL8_AvgClsdLoopAdjFact : 48|8@1+ (0.0078125,0) [0.0|1.9921875] "Ratio" Vector__XXX
 SG_ DL8_LambdaVoltBank1 : 0|8@1+ (0.02,0) [0.0|5.1] "" Vector__XXX
 SG_ DL8_ActualLambdaBank1 : 8|8@1+ (0.0078125,0) [0.0|1.9921875] "Ratio" Vector__XXX
 SG_ DL8_DesiredLambdaBank1 : 16|8@1+ (0.0078125,0) [0.0|1.9921875] "Ratio" Vector__XXX
 SG_ DL8_MixAdaptationHiLoadBank1 : 24|8@1+ (0.0078125,0) [0.0|1.9921875] "" Vector__XXX
 SG_ DL8_MixAdaptationLoLoadBank1 : 32|8@1+ (0.0078125,0) [0.0|1.9921875] "" Vector__XXX
 SG_ DL8_ClosedLoopAdjFactor1 : 40|8@1+ (0.0078125,0) [0.0|1.9921875] "Ratio" Vector__XXX
 SG_ DL8_LambaSensorHeaterOutBank1 : 56|2@1+ (1,0) [0.0|3.0] "" Vector__XXX
 SG_ DL8_AirFuelMixStatusBank1 : 58|2@1+ (1,0) [0.0|3.0] "" Vector__XXX
 SG_ DL8_ClosedLoopMixControlBank1 : 60|2@1+ (1,0) [0.0|3.0] "" Vector__XXX

BO_ 2566911232 FlagItems_1_0: 8 ECM
 SG_ FI1_IntercoolerPumpDriverCircuit : 46|2@1+ (1,0) [0.0|3.0] "" Vector__XXX
 SG_ FI1_FuelPullSolenoidStatus : 60|2@1+ (1,0) [0.0|3.0] "" Vector__XXX
 SG_ FI1_ClutchSwitchInput2 : 62|2@1+ (1,0) [0.0|3.0] "" Vector__XXX
 SG_ FI1_FuelPumpDriverCkt : 0|2@1+ (1,0) [0.0|3.0] "" Vector__XXX
 SG_ FI1_RolloverSwitch : 2|2@1+ (1,0) [0.0|3.0] "" Vector__XXX
 SG_ FI1_CrankSensorSignal : 4|2@1+ (1,0) [0.0|3.0] "" Vector__XXX
 SG_ FI1_CamSensorSignal : 6|2@1+ (1,0) [0.0|3.0] "" Vector__XXX
 SG_ FI1_RPMLimitActive : 8|2@1+ (1,0) [0.0|3.0] "" Vector__XXX
 SG_ FI1_IdleSwitch : 10|2@1+ (1,0) [0.0|3.0] "" Vector__XXX
 SG_ FI1_CycleSynchro : 12|2@1+ (1,0) [0.0|3.0] "" Vector__XXX
 SG_ FI1_IdleSpeedControlStatus : 14|2@1+ (1,0) [0.0|3.0] "" Vector__XXX
 SG_ FI1_IgnitionSwitchInput : 16|2@1+ (1,0) [0.0|3.0] "" Vector__XXX
 SG_ FI1_RunStopSwitchInput : 18|2@1+ (1,0) [0.0|3.0] "" Vector__XXX
 SG_ FI1_StartSwitchInput : 20|2@1+ (1,0) [0.0|3.0] "" Vector__XXX
 SG_ FI1_ThrottleSafetySwInput : 22|2@1+ (1,0) [0.0|3.0] "" Vector__XXX
 SG_ FI1_FanRelayOutput : 24|2@1+ (1,0) [0.0|3.0] "" Vector__XXX
 SG_ FI1_IntercoolerFanOutput : 26|2@1+ (1,0) [0.0|3.0] "" Vector__XXX
 SG_ FI1_ReverseAlarmOutput : 28|2@1+ (1,0) [0.0|3.0] "" Vector__XXX
 SG_ FI1_MainRelayOutput : 30|2@1+ (1,0) [0.0|3.0] "" Vector__XXX
 SG_ FI1_StartSolenoidOutput : 32|2@1+ (1,0) [0.0|3.0] "" Vector__XXX
 SG_ FI1_IgnitionRelayOutput : 34|2@1+ (1,0) [0.0|3.0] "" Vector__XXX
 SG_ FI1_ChassisRelayOutput : 36|2@1+ (1,0) [0.0|3.0] "" Vector__XXX
 SG_ FI1_StarterEnableOutput : 38|2@1+ (1,0) [0.0|3.0] "" Vector__XXX
 SG_ FI1_ExhaustValveOutput : 40|2@1+ (1,0) [0.0|3.0] "" Vector__XXX
 SG_ FI1_BatteryChargeRelayOutput : 42|2@1+ (1,0) [0.0|3.0] "" Vector__XXX
 SG_ FI1_HeaterAccRelay : 44|2@1+ (1,0) [0.0|3.0] "" Vector__XXX
 SG_ FI1_ClutchSwitchInput : 56|2@1+ (1,0) [0.0|3.0] "" Vector__XXX
 SG_ FI1_MILLampOutput : 48|2@1+ (1,0) [0.0|3.0] "" Vector__XXX
 SG_ FI1_OverTempLampOutput : 50|2@1+ (1,0) [0.0|3.0] "" Vector__XXX
 SG_ FI1_KnockDetLampOutput : 52|2@1+ (1,0) [0.0|3.0] "" Vector__XXX
 SG_ FI1_ElecOilPumpDrvrCirc : 58|2@1+ (1,0) [0.0|3.0] "" Vector__XXX

BO_ 2566910976 FlagItems_2_0: 8 ECM
 SG_ FI2_ThrttlBdyInitLrnValSave : 52|2@1+ (1,0) [0.0|3.0] "" Vector__XXX
 SG_ FI2_ThrttlBdyInitLearnSuccess : 54|2@1+ (1,0) [0.0|3.0] "" Vector__XXX
 SG_ FI2_ThrottleLimpHomeOpCondition : 46|2@1+ (1,0) [0.0|3.0] "" Vector__XXX
 SG_ FI2_SystemOnInput : 42|2@1+ (1,0) [0.0|3.0] "" Vector__XXX
 SG_ FI2_SftyFuelCutoffCndn : 56|2@1+ (1,0) [0.0|3.0] "" Vector__XXX
 SG_ FI2_RvrsblInjCutoffCndn : 58|2@1+ (1,0) [0.0|3.0] "" Vector__XXX
 SG_ FI2_PTOEngagementStatus : 38|2@1+ (1,0) [0.0|3.0] "" Vector__XXX
 SG_ FI2_ParkBrakeSwitchIn : 36|2@1+ (1,0) [0.0|3.0] "" Vector__XXX
 SG_ FI2_NeutralSwitchIn : 44|2@1+ (1,0) [0.0|3.0] "" Vector__XXX
 SG_ FI2_IrrvrsblInjCutoffCndn : 60|2@1+ (1,0) [0.0|3.0] "" Vector__XXX
 SG_ FI2_ETCFncnMonitor : 62|2@1+ (1,0) [0.0|3.0] "" Vector__XXX
 SG_ FI2_ADCOutput : 0|2@1+ (1,0) [0.0|3.0] "" Vector__XXX
 SG_ FI2_RearDiffLockOutput : 2|2@1+ (1,0) [0.0|3.0] "" Vector__XXX
 SG_ FI2_AWDOutput : 4|2@1+ (1,0) [0.0|3.0] "" Vector__XXX
 SG_ FI2_BrakeSwitchInput : 8|2@1+ (1,0) [0.0|3.0] "" Vector__XXX
 SG_ FI2_ADCSwitchInput : 10|2@1+ (1,0) [0.0|3.0] "" Vector__XXX
 SG_ FI2_TurfModeInput : 12|2@1+ (1,0) [0.0|3.0] "" Vector__XXX
 SG_ FI2_AWDSwitchInput : 14|2@1+ (1,0) [0.0|3.0] "" Vector__XXX
 SG_ FI2_ReverseSwitchInput : 16|2@1+ (1,0) [0.0|3.0] "" Vector__XXX
 SG_ FI2_ReverseLimitSwitchInput : 18|2@1+ (1,0) [0.0|3.0] "" Vector__XXX
 SG_ FI2_ForwardLimitSwitchInput : 20|2@1+ (1,0) [0.0|3.0] "" Vector__XXX
 SG_ FI2_EngineDirection : 22|2@1+ (1,0) [0.0|3.0] "" Vector__XXX
 SG_ FI2_RevSpeedLimitOverrideInput : 24|2@1+ (1,0) [0.0|3.0] "" Vector__XXX
 SG_ FI2_ReverseOverspeedSignal : 26|2@1+ (1,0) [0.0|3.0] "" Vector__XXX
 SG_ FI2_RightTurnSignalInput : 32|2@1+ (1,0) [0.0|3.0] "" Vector__XXX
 SG_ FI2_LeftTurnSignalInput : 34|2@1+ (1,0) [0.0|3.0] "" Vector__XXX
 SG_ FI2_KickstandSwitchInput : 40|2@1+ (1,0) [0.0|3.0] "" Vector__XXX
 SG_ FI2_ReflashEnableInputSignal : 48|2@1+ (1,0) [0.0|3.0] "" Vector__XXX
 SG_ FI2_TPSLearnInputSignal : 50|2@1+ (1,0) [0.0|3.0] "" Vector__XXX
 SG_ FI2_LowRangeSwitchInput : 30|2@1+ (1,0) [0.0|3.0] "" Vector__XXX
 SG_ FI2_ReverseMotorDriveInput : 28|2@1+ (1,0) [0.0|3.0] "" Vector__XXX

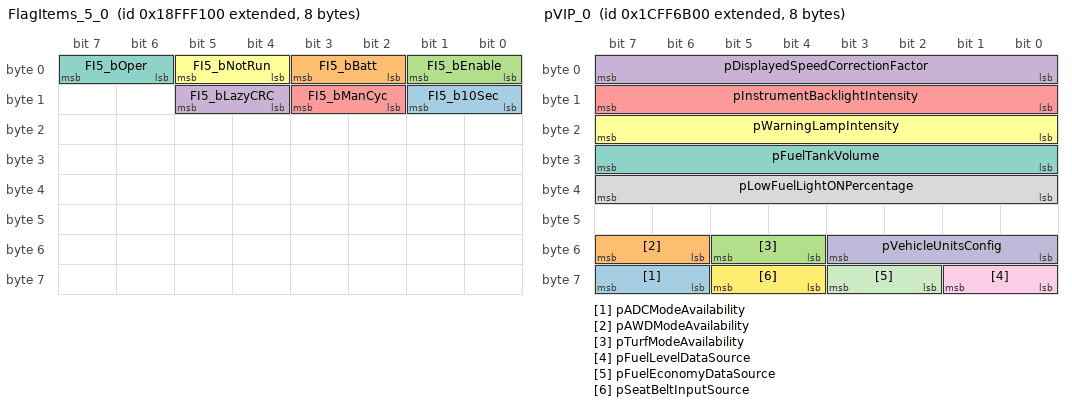
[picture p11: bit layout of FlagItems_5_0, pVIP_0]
BO_ 2566910208 FlagItems_5_0: 8 ECM
 SG_ FI5_b10Sec : 8|2@1+ (1,0) [0.0|3.0] "Binary" Vector__XXX
 SG_ FI5_bBatt : 2|2@1+ (1,0) [0.0|3.0] "Binary" Vector__XXX
 SG_ FI5_bEnable : 0|2@1+ (1,0) [0.0|3.0] "Binary" Vector__XXX
 SG_ FI5_bLazyCRC : 12|2@1+ (1,0) [0.0|3.0] "Binary" Vector__XXX
 SG_ FI5_bManCyc : 10|2@1+ (1,0) [0.0|3.0] "Binary" Vector__XXX
 SG_ FI5_bNotRun : 4|2@1+ (1,0) [0.0|3.0] "Binary" Vector__XXX
 SG_ FI5_bOper : 6|2@1+ (1,0) [0.0|3.0] "Binary" Vector__XXX

BO_ 2566908160 DataList_18_0: 8 ECM
 SG_ DL18_ThrottleBodyLearningStep : 48|8@1+ (1,0) [0.0|11.0] "Steps" Vector__XXX
 SG_ DL18_DesiredTorqueChg : 0|16@1+ (0.0030518,-100) [-100.0|99.999713] "%" Vector__XXX
 SG_ DL18_ThrottleAngleCorrFactor : 16|16@1+ (6.1036e-05,0) [0.0|3.99999426] "" Vector__XXX
 SG_ DL18_DragTorqueAdapt : 32|16@1+ (0.0030518,-100) [-100.0|99.999713] "%" Vector__XXX

BO_ 2633984768 pVIP_0: 8 ECM
 SG_ pADCModeAvailability : 62|2@1+ (1,0) [0.0|3.0] "" Vector__XXX
 SG_ pAWDModeAvailability : 54|2@1+ (1,0) [0.0|3.0] "" Vector__XXX
 SG_ pTurfModeAvailability : 52|2@1+ (1,0) [0.0|3.0] "" Vector__XXX
 SG_ pDisplayedSpeedCorrectionFactor : 0|8@1+ (0.8,-100) [-100.0|100.0] "%" Vector__XXX
 SG_ pInstrumentBacklightIntensity : 8|8@1+ (0.4,0) [0.0|100.0] "%" Vector__XXX
 SG_ pWarningLampIntensity : 16|8@1+ (0.4,0) [0.0|100.0] "%" Vector__XXX
 SG_ pFuelTankVolume : 24|8@1+ (0.5,0) [0.0|125.0] "Liters" Vector__XXX
 SG_ pLowFuelLightONPercentage : 32|8@1+ (0.4,0) [0.0|100.0] "Percent" Vector__XXX
 SG_ pFuelLevelDataSource : 56|2@1+ (1,0) [0.0|3.0] "" Vector__XXX
 SG_ pVehicleUnitsConfig : 48|4@1+ (1,0) [0.0|15.0] "" Vector__XXX
 SG_ pFuelEconomyDataSource : 58|2@1+ (1,0) [0.0|3.0] "" Vector__XXX
 SG_ pSeatBeltInputSource : 60|2@1+ (1,0) [0.0|3.0] "" Vector__XXX

BO_ 2566902272 DL_FuelData_0: 8 ECM
 SG_ DL_InjectorBankAPulseWidth : 0|16@1+ (0.007813,0) [0.0|511.99] "ms" Vector__XXX
 SG_ DL_InjectorBankBPulseWidth : 16|16@1+ (0.007813,0) [0.0|511.99] "ms" Vector__XXX
 SG_ DL_FuelConsumptionRate : 32|16@1+ (0.0039,0) [0.0|255.5865] "GPH" Vector__XXX
 SG_ DL_FuelSelectInput : 48|8@1+ (0.01953,0) [0.0|4.98015] "V" Vector__XXX

BO_ 2566910720 FlagItems_3_0: 8 ECM
 SG_ FI3_OilPressSwIn : 62|2@1+ (1,0) [0.0|3.0] "" Vector__XXX
 SG_ FI3_BrkSw2In : 60|2@1+ (1,0) [0.0|3.0] "" Vector__XXX
 SG_ FI3_CruiseCtrlResumeOut : 54|2@1+ (1,0) [0.0|3.0] "" Vector__XXX
 SG_ FI3_CruiseCtrlResumeIn : 56|2@1+ (1,0) [0.0|3.0] "" Vector__XXX
 SG_ FI3_CruiseCtrlCancelIn : 58|2@1+ (1,0) [0.0|3.0] "" Vector__XXX
 SG_ FI3_TetherSwStatus : 38|2@1+ (1,0) [0.0|3.0] "" Vector__XXX
 SG_ FI3_DriveMode1Input : 0|2@1+ (1,0) [0.0|3.0] "" Vector__XXX
 SG_ FI3_DriveMode2Input : 2|2@1+ (1,0) [0.0|3.0] "" Vector__XXX
 SG_ FI3_DriveMode3Input : 4|2@1+ (1,0) [0.0|3.0] "" Vector__XXX
 SG_ FI3_DriverMode4Input : 6|2@1+ (1,0) [0.0|3.0] "" Vector__XXX
 SG_ FI3_DriverMode1Output : 8|2@1+ (1,0) [0.0|3.0] "" Vector__XXX
 SG_ FI3_DriverMode2Output : 10|2@1+ (1,0) [0.0|3.0] "" Vector__XXX
 SG_ FI3_DriverMode3Output : 12|2@1+ (1,0) [0.0|3.0] "" Vector__XXX
 SG_ FI3_DriverMode4Ouput : 14|2@1+ (1,0) [0.0|3.0] "" Vector__XXX
 SG_ FI3_PTOModeInput : 16|2@1+ (1,0) [0.0|3.0] "" Vector__XXX
 SG_ FI3_PTOModeOutput : 18|2@1+ (1,0) [0.0|3.0] "" Vector__XXX
 SG_ FI3_DriversNetEngagement : 20|2@1+ (1,0) [0.0|3.0] "" Vector__XXX
 SG_ FI3_DriversSeatbeltEngagement : 22|2@1+ (1,0) [0.0|3.0] "" Vector__XXX
 SG_ FI3_TiltLockInput : 24|2@1+ (1,0) [0.0|3.0] "" Vector__XXX
 SG_ FI3_WorkGroupLockInput : 26|2@1+ (1,0) [0.0|3.0] "" Vector__XXX
 SG_ FI3_OperatorPresenceInput : 28|2@1+ (1,0) [0.0|3.0] "" Vector__XXX
 SG_ FI3_WorkGroupLockOutput : 34|2@1+ (1,0) [0.0|3.0] "" Vector__XXX
 SG_ FI3_OperatorPresenceOutput : 36|2@1+ (1,0) [0.0|3.0] "" Vector__XXX
 SG_ FI3_FootOnCruiseInput : 40|2@1+ (1,0) [0.0|3.0] "" Vector__XXX
 SG_ FI3_CruiseInput : 42|2@1+ (1,0) [0.0|3.0] "" Vector__XXX
 SG_ FI3_TredalInput : 44|2@1+ (1,0) [0.0|3.0] "" Vector__XXX
 SG_ FI3_CruiseSpeedInput : 46|2@1+ (1,0) [0.0|3.0] "" Vector__XXX
 SG_ FI3_FootOnCruiseOutput : 48|2@1+ (1,0) [0.0|3.0] "" Vector__XXX
 SG_ FI3_CruiseOutput : 50|2@1+ (1,0) [0.0|3.0] "" Vector__XXX
 SG_ FI3_CruiseControltoSetSpeed : 52|2@1+ (1,0) [0.0|0.0] "" Vector__XXX
 SG_ FI3_WorkModeInput : 30|2@1+ (1,0) [0.0|3.0] "" Vector__XXX
 SG_ FI3_TiltLockOutput : 32|2@1+ (1,0) [0.0|3.0] "" Vector__XXX

BO_ 2566910464 FlagItems_4_0: 8 ECM
 SG_ FI4_SeatbeltSw : 60|2@1+ (1,0) [0.0|3.0] "" Vector__XXX
 SG_ FI4_pSideStandSw : 52|2@1+ (1,0) [0.0|3.0] "" Vector__XXX
 SG_ FI4_DrvlnMomentaryRight : 58|2@1+ (1,0) [0.0|3.0] "" Vector__XXX
 SG_ FI4_DrvlnMomentaryLeft : 56|2@1+ (1,0) [0.0|3.0] "" Vector__XXX
 SG_ FI4_BrakeLightOutput : 30|2@1+ (1,0) [0.0|3.0] "" Vector__XXX
 SG_ FI4_FogLightInput : 4|2@1+ (1,0) [0.0|3.0] "" Vector__XXX
 SG_ FI4_HazardLightOutput : 26|2@1+ (1,0) [0.0|3.0] "" Vector__XXX
 SG_ FI4_HazardSWInput : 0|2@1+ (1,0) [0.0|3.0] "" Vector__XXX
 SG_ FI4_HeatGripDecSW : 46|2@1+ (1,0) [0.0|3.0] "" Vector__XXX
 SG_ FI4_HeatGripIncSW : 44|2@1+ (1,0) [0.0|3.0] "" Vector__XXX
 SG_ FI4_HighBeamOutput : 8|2@1+ (1,0) [0.0|3.0] "" Vector__XXX
 SG_ FI4_HornInput : 6|2@1+ (1,0) [0.0|3.0] "" Vector__XXX
 SG_ FI4_HornOutput : 24|2@1+ (1,0) [0.0|3.0] "" Vector__XXX
 SG_ FI4_LeftFogLightOutput : 12|2@1+ (1,0) [0.0|3.0] "" Vector__XXX
 SG_ FI4_LFTurnSignalOutput : 32|2@1+ (1,0) [0.0|3.0] "" Vector__XXX
 SG_ FI4_LockInput : 18|2@1+ (1,0) [0.0|3.0] "" Vector__XXX
 SG_ FI4_LowBeamOutput : 10|2@1+ (1,0) [0.0|3.0] "" Vector__XXX
 SG_ FI4_LowHighBeamInput : 2|2@1+ (1,0) [0.0|3.0] "" Vector__XXX
 SG_ FI4_LRTurnSignalOutput : 36|2@1+ (1,0) [0.0|3.0] "" Vector__XXX
 SG_ FI4_pOperatorButton1 : 48|2@1+ (1,0) [0.0|3.0] "" Vector__XXX
 SG_ FI4_RFTurnSignalOutput : 34|2@1+ (1,0) [0.0|3.0] "" Vector__XXX
 SG_ FI4_RightFogLightOutput : 14|2@1+ (1,0) [0.0|3.0] "" Vector__XXX
 SG_ FI4_RRTurnSignalOutput : 38|2@1+ (1,0) [0.0|3.0] "" Vector__XXX
 SG_ FI4_SecondaryAirValveCmd : 42|2@1+ (1,0) [0.0|3.0] "" Vector__XXX
 SG_ FI4_SecondaryAirValveOut : 40|2@1+ (1,0) [0.0|3.0] "" Vector__XXX
 SG_ FI4_TailLightOutput : 28|2@1+ (1,0) [0.0|3.0] "" Vector__XXX
 SG_ FI4_UnlockInput : 16|2@1+ (1,0) [0.0|3.0] "" Vector__XXX
 SG_ FI4_WindshieldSWDownInput : 22|2@1+ (1,0) [0.0|3.0] "" Vector__XXX
 SG_ FI4_WindshieldSWUpInput : 20|2@1+ (1,0) [0.0|3.0] "" Vector__XXX
 SG_ FI4_pOperatorButton2 : 50|2@1+ (1,0) [0.0|3.0] "" Vector__XXX

BO_ 2566907904 DataList_19_0: 8 ECM
 SG_ DL19_TirePressure_Rear_Left_Only : 16|8@1+ (4,0) [0.0|1020.0] "kPa" Vector__XXX
 SG_ DL19_TirePressureFront_Left_Only : 0|8@1+ (4,0) [0.0|1020.0] "kPa" Vector__XXX
 SG_ DL19_TirePressureFrontRight : 8|8@1+ (4,0) [0.0|1020.0] "kPa" Vector__XXX
 SG_ DL19_TirePressureRearRight : 24|8@1+ (4,0) [0.0|1020.0] "kPa" Vector__XXX

BO_ 2566907648 DataList_20_0: 8 ECM
 SG_ DL20_KeyFobBatteryVoltage : 0|8@1+ (0.1,0) [0.0|25.5] "Volts" Vector__XXX
 SG_ DL20_LeanAngle : 8|8@1+ (1,-125) [-125.0|130.0] "Degrees" Vector__XXX

BO_ 2566847578 DashDisplay_90: 8 HCU
 SG_ WasherFluidLevel : 0|8@1+ (0.4,0) [0.0|100.0] "%" Vector__XXX
 SG_ FuelLevel : 8|8@1+ (0.4,0) [0.0|100.0] "%" Vector__XXX
 SG_ FuelFilterDiffPressure : 16|8@1+ (2,0) [0.0|500.0] "kPa" Vector__XXX
 SG_ EngineOilFilterDiffPressure : 24|8@1+ (0.5,0) [0.0|125.0] "kPa" Vector__XXX
 SG_ CargoAmbientTemperature : 32|16@1+ (0.03125,-273) [-273.0|1735.0] "°C" Vector__XXX

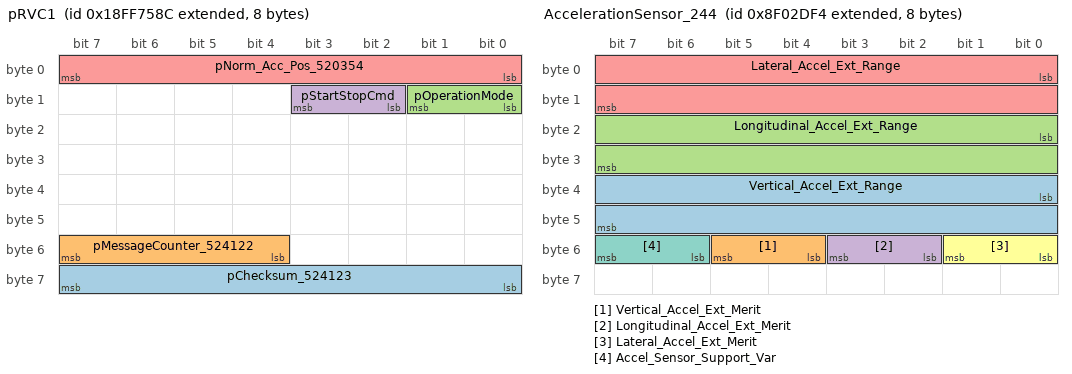
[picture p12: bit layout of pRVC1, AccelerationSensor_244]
BO_ 2566878604 pRVC1: 8 CIM
 SG_ pChecksum_524123 : 56|8@1+ (1,0) [0.0|255.0] "" Vector__XXX
 SG_ pMessageCounter_524122 : 52|4@1+ (1,0) [0.0|15.0] "" Vector__XXX
 SG_ pOperationMode : 8|2@1+ (1,0) [0.0|0.0] "" Vector__XXX
 SG_ pStartStopCmd : 10|2@1+ (1,0) [0.0|3.0] "" Vector__XXX
 SG_ pNorm_Acc_Pos_520354 : 0|8@1+ (0.4,0) [0.0|102.0] "Percent" Vector__XXX

BO_ 2566878464 pEngineControlRequests: 8 ECM
 SG_ pStartStopCmd : 10|2@1+ (1,0) [0.0|3.0] "" Vector__XXX
 SG_ pPedalPositionCommand : 0|8@1+ (0.4,0) [0.0|102.0] "%" Vector__XXX
 SG_ pOperationMode : 8|2@1+ (1,0) [0.0|0.0] "" Vector__XXX

BO_ 2566876928 pEngineRequests1: 8 ECM
 SG_ pSecondaryAirValveControl : 0|2@1+ (1,0) [0.0|3.0] "" Vector__XXX

BO_ 2566853886 pWattMessage: 8 HCU
 SG_ pRangeToEmptyEV : 16|16@1+ (0.1,0) [0.0|6425.5] "km" Vector__XXX
 SG_ pEfficiencyEV : 0|16@1+ (0.1,0) [0.0|6425.5] "Wh/km" Vector__XXX

BO_ 2566876416 pDriveModeETC: 8 ECM
 SG_ pDriveModeCommanded : 16|8@1+ (1,0) [0.0|255.0] "" Vector__XXX
 SG_ pFootOnCruiseControlEnabled : 8|2@1+ (1,0) [0.0|3.0] "" Vector__XXX
 SG_ pDriveModeRequested : 0|8@1+ (1,0) [0.0|255.0] "" Vector__XXX

BO_ 2566825472 IntakeManifoldInformation1: 8 ECM
 SG_ EngineTurbo1BoostPressure : 0|16@1+ (0.125,0) [0.0|8031.875] "kPa" Vector__XXX

BO_ 2566804212 VehicleElectricalPower3_244: 8 Battery_Management_Cntrl_2
 SG_ NetBattCurrentHiRange : 16|16@1+ (0.05,0) [0.0|3276.75] "A" Vector__XXX

BO_ 2566804211 VehicleElectricalPower3_243: 8 Battery_Management_Cntrl_1
 SG_ NetBattCurrentHiRange : 16|16@1+ (0.05,0) [0.0|3276.75] "A" Vector__XXX

BO_ 2297441780 AccelerationSensor_244: 8 Battery_Management_Cntrl_2
 SG_ Vertical_Accel_Ext_Range : 32|16@1+ (0.01,-320) [-320.0|322.55] "m/s2" Vector__XXX
 SG_ Vertical_Accel_Ext_Merit : 52|2@1+ (1,0) [0.0|3.0] "" Vector__XXX
 SG_ Longitudinal_Accel_Ext_Range : 16|16@1+ (0.01,-320) [-320.0|322.55] "m/s2" Vector__XXX
 SG_ Longitudinal_Accel_Ext_Merit : 50|2@1+ (1,0) [0.0|3.0] "" Vector__XXX
 SG_ Lateral_Accel_Ext_Range : 0|16@1+ (0.01,-320) [-320.0|322.55] "m/s2" Vector__XXX
 SG_ Lateral_Accel_Ext_Merit : 48|2@1+ (1,0) [0.0|3.0] "" Vector__XXX
 SG_ Accel_Sensor_Support_Var : 54|2@1+ (1,0) [0.0|3.0] "" Vector__XXX

BO_ 2566846452 WATT_Veh_Electrical_Pwr_244: 8 Battery_Management_Cntrl_2
 SG_ Net_Battery_Current : 0|8@1+ (1,-125) [-125.0|125.0] "A" Vector__XXX
 SG_ BatteryPotential : 16|16@1+ (0.05,0) [0.0|3212.75] "V" Vector__XXX

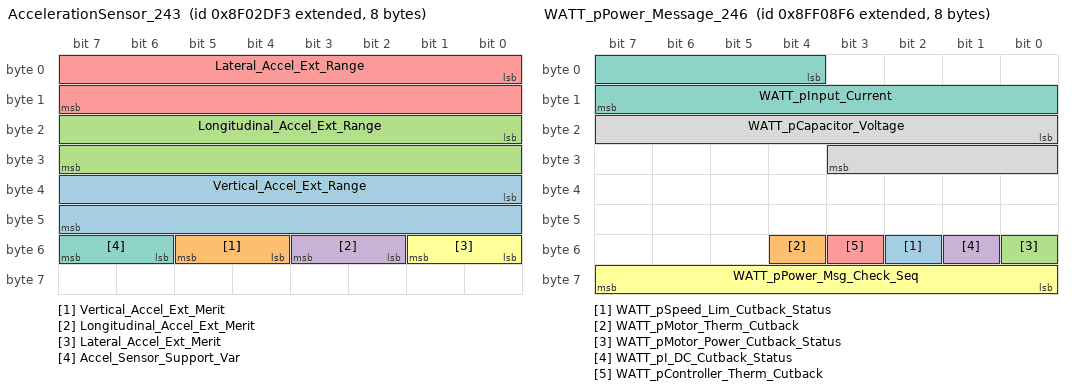
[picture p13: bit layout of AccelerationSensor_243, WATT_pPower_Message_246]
BO_ 2297441779 AccelerationSensor_243: 8 Battery_Management_Cntrl_1
 SG_ Vertical_Accel_Ext_Range : 32|16@1+ (0.01,-320) [-320.0|322.55] "m/s2" Vector__XXX
 SG_ Vertical_Accel_Ext_Merit : 52|2@1+ (1,0) [0.0|3.0] "" Vector__XXX
 SG_ Longitudinal_Accel_Ext_Range : 16|16@1+ (0.01,-320) [-320.0|322.55] "m/s2" Vector__XXX
 SG_ Longitudinal_Accel_Ext_Merit : 50|2@1+ (1,0) [0.0|3.0] "" Vector__XXX
 SG_ Lateral_Accel_Ext_Range : 0|16@1+ (0.01,-320) [-320.0|322.55] "m/s2" Vector__XXX
 SG_ Lateral_Accel_Ext_Merit : 48|2@1+ (1,0) [0.0|3.0] "" Vector__XXX
 SG_ Accel_Sensor_Support_Var : 54|2@1+ (1,0) [0.0|3.0] "" Vector__XXX

BO_ 2566846451 WATT_Veh_Electrical_Pwr_243: 8 Battery_Management_Cntrl_1
 SG_ Net_Battery_Current : 0|8@1+ (1,-125) [-125.0|125.0] "A" Vector__XXX
 SG_ BatteryPotential : 16|16@1+ (0.05,0) [0.0|3212.75] "V" Vector__XXX

BO_ 2365525748 WATT_pBMC_Power_Message_244: 8 Battery_Management_Cntrl_2
 SG_ WATT_pPack_Voltage : 16|16@1+ (0.05,0) [0.0|3212.75] "V" Vector__XXX
 SG_ WATT_pPack_Current : 0|16@1+ (0.05,-1600) [-1600.0|1612.75] "A" Vector__XXX
 SG_ WATT_pDischarge_Limit : 32|12@1+ (0.5,0) [0.0|2007.5] "A" Vector__XXX
 SG_ WATT_pCharge_Limit : 44|12@1+ (0.5,0) [0.0|2007.5] "A" Vector__XXX
 SG_ WATT_pBMC_Pwr_Msg_Check_Seq : 56|8@1+ (1,0) [0.0|255.0] "" Vector__XXX

BO_ 2365525747 WATT_pBMC_Power_Message_243: 8 Battery_Management_Cntrl_1
 SG_ WATT_pPack_Voltage : 16|16@1+ (0.05,0) [0.0|3212.75] "V" Vector__XXX
 SG_ WATT_pPack_Current : 0|16@1+ (0.05,-1600) [-1600.0|1612.75] "A" Vector__XXX
 SG_ WATT_pDischarge_Limit : 32|12@1+ (0.5,0) [0.0|2007.5] "A" Vector__XXX
 SG_ WATT_pCharge_Limit : 44|12@1+ (0.5,0) [0.0|2007.5] "A" Vector__XXX
 SG_ WATT_pBMC_Pwr_Msg_Check_Seq : 56|8@1+ (1,0) [0.0|255.0] "" Vector__XXX

BO_ 2298415350 WATT_pPower_Message_246: 8 Auxiliary_Power_Unit_2
 SG_ WATT_pSpeed_Lim_Cutback_Status : 50|1@1+ (1,0) [0.0|1.0] "" Vector__XXX
 SG_ WATT_pMotor_Therm_Cutback : 52|1@1+ (1,0) [0.0|1.0] "" Vector__XXX
 SG_ WATT_pMotor_Power_Cutback_Status : 48|1@1+ (1,0) [0.0|1.0] "" Vector__XXX
 SG_ WATT_pI_DC_Cutback_Status : 49|1@1+ (1,0) [0.0|1.0] "" Vector__XXX
 SG_ WATT_pController_Therm_Cutback : 51|1@1+ (1,0) [0.0|1.0] "" Vector__XXX
 SG_ WATT_pPower_Msg_Check_Seq : 56|8@1+ (1,0) [0.0|255.0] "" Vector__XXX
 SG_ WATT_pInput_Current : 4|12@1+ (1,0) [0.0|4095.0] "" Vector__XXX
 SG_ WATT_pCapacitor_Voltage : 16|12@1+ (1,0) [0.0|4095.0] "" Vector__XXX

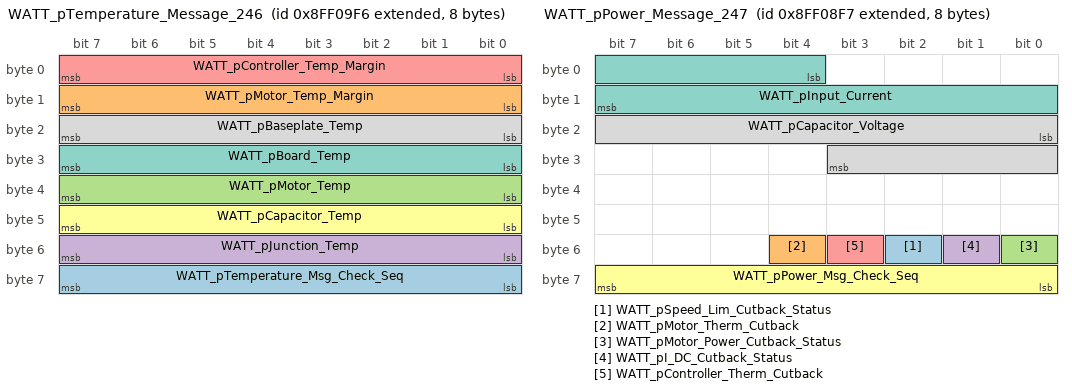
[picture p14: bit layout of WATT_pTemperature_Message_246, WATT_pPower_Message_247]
BO_ 2298415606 WATT_pTemperature_Message_246: 8 Auxiliary_Power_Unit_2
 SG_ WATT_pTemperature_Msg_Check_Seq : 56|8@1+ (1,0) [0.0|255.0] "" Vector__XXX
 SG_ WATT_pMotor_Temp_Margin : 8|8@1+ (1,0) [0.0|250.0] "C" Vector__XXX
 SG_ WATT_pMotor_Temp : 32|8@1+ (1,-40) [-40.0|210.0] "C" Vector__XXX
 SG_ WATT_pJunction_Temp : 48|8@1+ (1,-40) [-40.0|210.0] "C" Vector__XXX
 SG_ WATT_pController_Temp_Margin : 0|8@1+ (1,0) [0.0|250.0] "C" Vector__XXX
 SG_ WATT_pCapacitor_Temp : 40|8@1+ (1,-40) [-40.0|210.0] "C" Vector__XXX
 SG_ WATT_pBoard_Temp : 24|8@1+ (1,-40) [-40.0|210.0] "C" Vector__XXX
 SG_ WATT_pBaseplate_Temp : 16|8@1+ (1,-40) [-40.0|210.0] "C" Vector__XXX

BO_ 2298415351 WATT_pPower_Message_247: 8 Auxiliary_Power_Unit_1
 SG_ WATT_pSpeed_Lim_Cutback_Status : 50|1@1+ (1,0) [0.0|1.0] "" Vector__XXX
 SG_ WATT_pMotor_Therm_Cutback : 52|1@1+ (1,0) [0.0|1.0] "" Vector__XXX
 SG_ WATT_pMotor_Power_Cutback_Status : 48|1@1+ (1,0) [0.0|1.0] "" Vector__XXX
 SG_ WATT_pI_DC_Cutback_Status : 49|1@1+ (1,0) [0.0|1.0] "" Vector__XXX
 SG_ WATT_pController_Therm_Cutback : 51|1@1+ (1,0) [0.0|1.0] "" Vector__XXX
 SG_ WATT_pPower_Msg_Check_Seq : 56|8@1+ (1,0) [0.0|255.0] "" Vector__XXX
 SG_ WATT_pInput_Current : 4|12@1+ (1,0) [0.0|4095.0] "" Vector__XXX
 SG_ WATT_pCapacitor_Voltage : 16|12@1+ (1,0) [0.0|4095.0] "" Vector__XXX

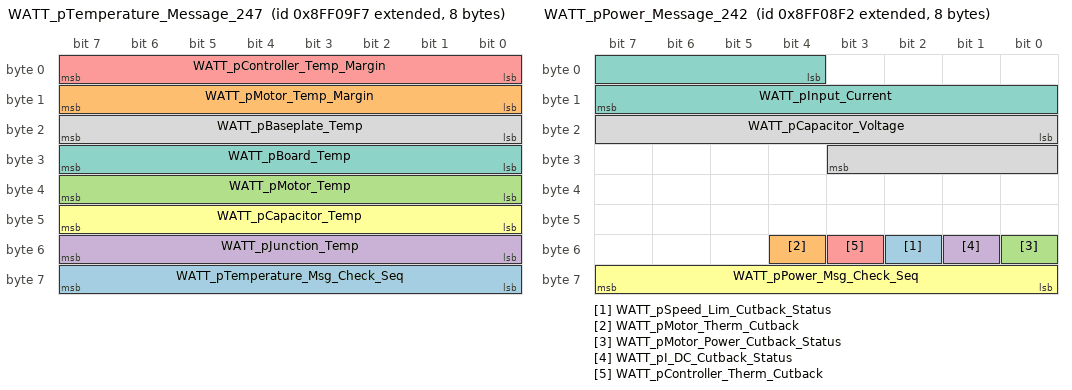
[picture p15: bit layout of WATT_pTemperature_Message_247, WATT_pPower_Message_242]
BO_ 2298415607 WATT_pTemperature_Message_247: 8 Auxiliary_Power_Unit_1
 SG_ WATT_pTemperature_Msg_Check_Seq : 56|8@1+ (1,0) [0.0|255.0] "" Vector__XXX
 SG_ WATT_pMotor_Temp_Margin : 8|8@1+ (1,0) [0.0|250.0] "C" Vector__XXX
 SG_ WATT_pMotor_Temp : 32|8@1+ (1,-40) [-40.0|210.0] "C" Vector__XXX
 SG_ WATT_pJunction_Temp : 48|8@1+ (1,-40) [-40.0|210.0] "C" Vector__XXX
 SG_ WATT_pController_Temp_Margin : 0|8@1+ (1,0) [0.0|250.0] "C" Vector__XXX
 SG_ WATT_pCapacitor_Temp : 40|8@1+ (1,-40) [-40.0|210.0] "C" Vector__XXX
 SG_ WATT_pBoard_Temp : 24|8@1+ (1,-40) [-40.0|210.0] "C" Vector__XXX
 SG_ WATT_pBaseplate_Temp : 16|8@1+ (1,-40) [-40.0|210.0] "C" Vector__XXX

BO_ 2365523456 pModCtlMsg: 8 ECM
 SG_ pModCtlMsg_Checksum : 60|4@1+ (1,0) [0.0|0.0] "" Vector__XXX
 SG_ pModCtlAppliedState : 24|4@1+ (1,0) [0.0|0.0] "" Vector__XXX
 SG_ pModCtlCmdDestAdd : 8|16@1+ (1,0) [0.0|65535.0] "Address" Vector__XXX
 SG_ pModCtlCmdState : 0|4@1+ (1,0) [0.0|15.0] "" Vector__XXX

BO_ 2298415346 WATT_pPower_Message_242: 8 Electric_Propulsion_Cntrl_Unit_4
 SG_ WATT_pSpeed_Lim_Cutback_Status : 50|1@1+ (1,0) [0.0|1.0] "" Vector__XXX
 SG_ WATT_pMotor_Therm_Cutback : 52|1@1+ (1,0) [0.0|1.0] "" Vector__XXX
 SG_ WATT_pMotor_Power_Cutback_Status : 48|1@1+ (1,0) [0.0|1.0] "" Vector__XXX
 SG_ WATT_pI_DC_Cutback_Status : 49|1@1+ (1,0) [0.0|1.0] "" Vector__XXX
 SG_ WATT_pController_Therm_Cutback : 51|1@1+ (1,0) [0.0|1.0] "" Vector__XXX
 SG_ WATT_pPower_Msg_Check_Seq : 56|8@1+ (1,0) [0.0|255.0] "" Vector__XXX
 SG_ WATT_pInput_Current : 4|12@1+ (1,0) [0.0|4095.0] "" Vector__XXX
 SG_ WATT_pCapacitor_Voltage : 16|12@1+ (1,0) [0.0|4095.0] "" Vector__XXX

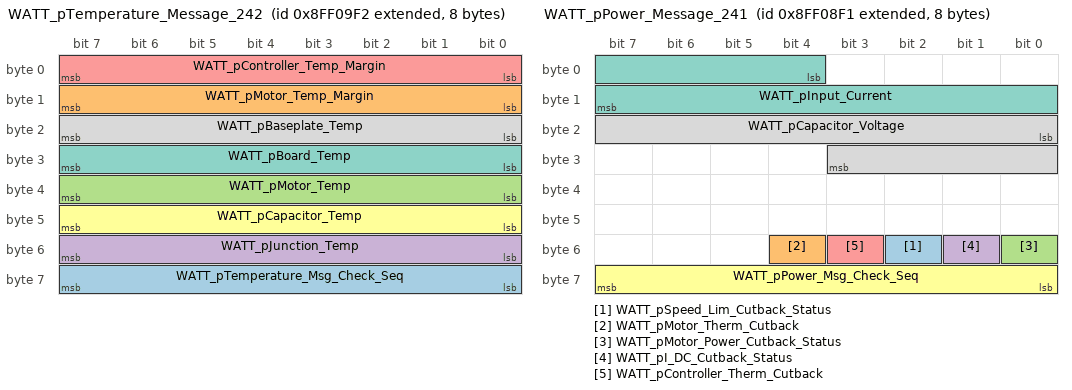
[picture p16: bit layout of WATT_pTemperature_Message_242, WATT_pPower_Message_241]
BO_ 2298415602 WATT_pTemperature_Message_242: 8 Electric_Propulsion_Cntrl_Unit_4
 SG_ WATT_pTemperature_Msg_Check_Seq : 56|8@1+ (1,0) [0.0|255.0] "" Vector__XXX
 SG_ WATT_pMotor_Temp_Margin : 8|8@1+ (1,0) [0.0|250.0] "C" Vector__XXX
 SG_ WATT_pMotor_Temp : 32|8@1+ (1,-40) [-40.0|210.0] "C" Vector__XXX
 SG_ WATT_pJunction_Temp : 48|8@1+ (1,-40) [-40.0|210.0] "C" Vector__XXX
 SG_ WATT_pController_Temp_Margin : 0|8@1+ (1,0) [0.0|250.0] "C" Vector__XXX
 SG_ WATT_pCapacitor_Temp : 40|8@1+ (1,-40) [-40.0|210.0] "C" Vector__XXX
 SG_ WATT_pBoard_Temp : 24|8@1+ (1,-40) [-40.0|210.0] "C" Vector__XXX
 SG_ WATT_pBaseplate_Temp : 16|8@1+ (1,-40) [-40.0|210.0] "C" Vector__XXX

BO_ 2298415345 WATT_pPower_Message_241: 8 Electric_Propulsion_Cntrl_Unit_3
 SG_ WATT_pSpeed_Lim_Cutback_Status : 50|1@1+ (1,0) [0.0|1.0] "" Vector__XXX
 SG_ WATT_pMotor_Therm_Cutback : 52|1@1+ (1,0) [0.0|1.0] "" Vector__XXX
 SG_ WATT_pMotor_Power_Cutback_Status : 48|1@1+ (1,0) [0.0|1.0] "" Vector__XXX
 SG_ WATT_pI_DC_Cutback_Status : 49|1@1+ (1,0) [0.0|1.0] "" Vector__XXX
 SG_ WATT_pController_Therm_Cutback : 51|1@1+ (1,0) [0.0|1.0] "" Vector__XXX
 SG_ WATT_pPower_Msg_Check_Seq : 56|8@1+ (1,0) [0.0|255.0] "" Vector__XXX
 SG_ WATT_pInput_Current : 4|12@1+ (1,0) [0.0|4095.0] "" Vector__XXX
 SG_ WATT_pCapacitor_Voltage : 16|12@1+ (1,0) [0.0|4095.0] "" Vector__XXX

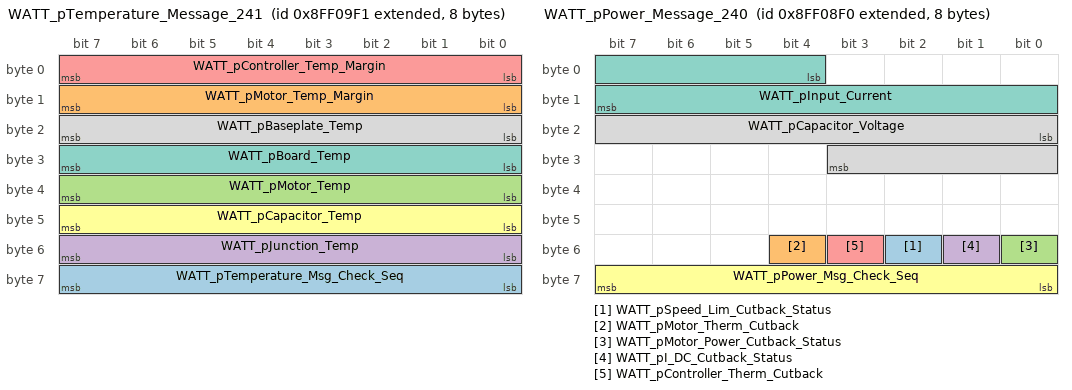
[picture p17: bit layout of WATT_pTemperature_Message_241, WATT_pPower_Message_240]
BO_ 2298415601 WATT_pTemperature_Message_241: 8 Electric_Propulsion_Cntrl_Unit_3
 SG_ WATT_pTemperature_Msg_Check_Seq : 56|8@1+ (1,0) [0.0|255.0] "" Vector__XXX
 SG_ WATT_pMotor_Temp_Margin : 8|8@1+ (1,0) [0.0|250.0] "C" Vector__XXX
 SG_ WATT_pMotor_Temp : 32|8@1+ (1,-40) [-40.0|210.0] "C" Vector__XXX
 SG_ WATT_pJunction_Temp : 48|8@1+ (1,-40) [-40.0|210.0] "C" Vector__XXX
 SG_ WATT_pController_Temp_Margin : 0|8@1+ (1,0) [0.0|250.0] "C" Vector__XXX
 SG_ WATT_pCapacitor_Temp : 40|8@1+ (1,-40) [-40.0|210.0] "C" Vector__XXX
 SG_ WATT_pBoard_Temp : 24|8@1+ (1,-40) [-40.0|210.0] "C" Vector__XXX
 SG_ WATT_pBaseplate_Temp : 16|8@1+ (1,-40) [-40.0|210.0] "C" Vector__XXX

BO_ 2298415344 WATT_pPower_Message_240: 8 Electric_Propulsion_Cntrl_Unit_2
 SG_ WATT_pSpeed_Lim_Cutback_Status : 50|1@1+ (1,0) [0.0|1.0] "" Vector__XXX
 SG_ WATT_pMotor_Therm_Cutback : 52|1@1+ (1,0) [0.0|1.0] "" Vector__XXX
 SG_ WATT_pMotor_Power_Cutback_Status : 48|1@1+ (1,0) [0.0|1.0] "" Vector__XXX
 SG_ WATT_pI_DC_Cutback_Status : 49|1@1+ (1,0) [0.0|1.0] "" Vector__XXX
 SG_ WATT_pController_Therm_Cutback : 51|1@1+ (1,0) [0.0|1.0] "" Vector__XXX
 SG_ WATT_pPower_Msg_Check_Seq : 56|8@1+ (1,0) [0.0|255.0] "" Vector__XXX
 SG_ WATT_pInput_Current : 4|12@1+ (1,0) [0.0|4095.0] "" Vector__XXX
 SG_ WATT_pCapacitor_Voltage : 16|12@1+ (1,0) [0.0|4095.0] "" Vector__XXX

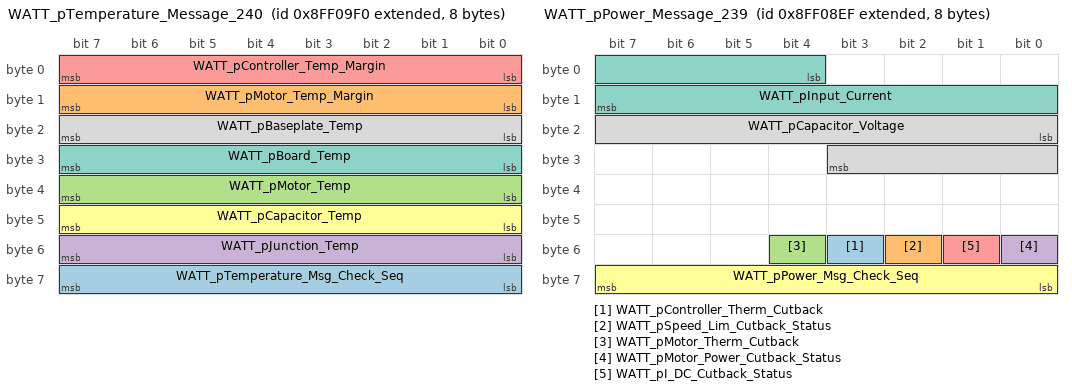
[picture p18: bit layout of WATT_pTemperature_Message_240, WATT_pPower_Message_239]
BO_ 2298415600 WATT_pTemperature_Message_240: 8 Electric_Propulsion_Cntrl_Unit_2
 SG_ WATT_pTemperature_Msg_Check_Seq : 56|8@1+ (1,0) [0.0|255.0] "" Vector__XXX
 SG_ WATT_pMotor_Temp_Margin : 8|8@1+ (1,0) [0.0|250.0] "C" Vector__XXX
 SG_ WATT_pMotor_Temp : 32|8@1+ (1,-40) [-40.0|210.0] "C" Vector__XXX
 SG_ WATT_pJunction_Temp : 48|8@1+ (1,-40) [-40.0|210.0] "C" Vector__XXX
 SG_ WATT_pController_Temp_Margin : 0|8@1+ (1,0) [0.0|250.0] "C" Vector__XXX
 SG_ WATT_pCapacitor_Temp : 40|8@1+ (1,-40) [-40.0|210.0] "C" Vector__XXX
 SG_ WATT_pBoard_Temp : 24|8@1+ (1,-40) [-40.0|210.0] "C" Vector__XXX
 SG_ WATT_pBaseplate_Temp : 16|8@1+ (1,-40) [-40.0|210.0] "C" Vector__XXX

BO_ 2298415343 WATT_pPower_Message_239: 8 Electric_Propulsion_Cntrl_Unit_1
 SG_ WATT_pController_Therm_Cutback : 51|1@1+ (1,0) [0.0|1.0] "" Vector__XXX
 SG_ WATT_pSpeed_Lim_Cutback_Status : 50|1@1+ (1,0) [0.0|1.0] "" Vector__XXX
 SG_ WATT_pMotor_Therm_Cutback : 52|1@1+ (1,0) [0.0|1.0] "" Vector__XXX
 SG_ WATT_pMotor_Power_Cutback_Status : 48|1@1+ (1,0) [0.0|1.0] "" Vector__XXX
 SG_ WATT_pI_DC_Cutback_Status : 49|1@1+ (1,0) [0.0|1.0] "" Vector__XXX
 SG_ WATT_pPower_Msg_Check_Seq : 56|8@1+ (1,0) [0.0|255.0] "" Vector__XXX
 SG_ WATT_pInput_Current : 4|12@1+ (1,0) [0.0|4095.0] "" Vector__XXX
 SG_ WATT_pCapacitor_Voltage : 16|12@1+ (1,0) [0.0|4095.0] "" Vector__XXX

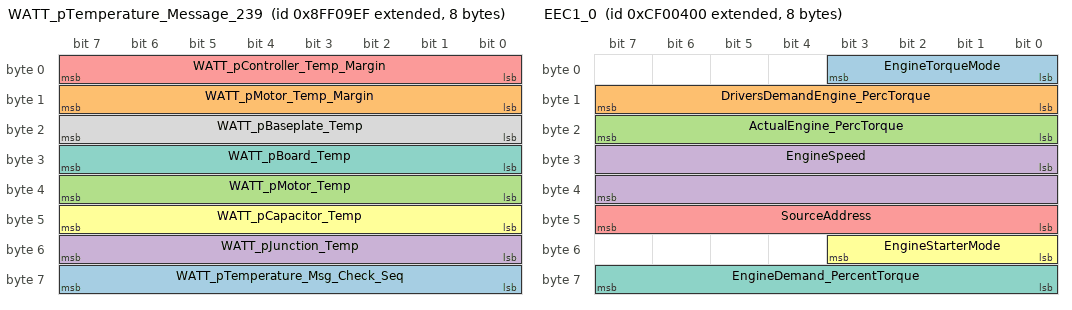
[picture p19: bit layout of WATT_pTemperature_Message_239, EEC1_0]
BO_ 2298415599 WATT_pTemperature_Message_239: 8 Electric_Propulsion_Cntrl_Unit_1
 SG_ WATT_pTemperature_Msg_Check_Seq : 56|8@1+ (1,0) [0.0|255.0] "" Vector__XXX
 SG_ WATT_pMotor_Temp_Margin : 8|8@1+ (1,0) [0.0|250.0] "C" Vector__XXX
 SG_ WATT_pMotor_Temp : 32|8@1+ (1,-40) [-40.0|210.0] "C" Vector__XXX
 SG_ WATT_pJunction_Temp : 48|8@1+ (1,-40) [-40.0|210.0] "C" Vector__XXX
 SG_ WATT_pController_Temp_Margin : 0|8@1+ (1,0) [0.0|250.0] "C" Vector__XXX
 SG_ WATT_pCapacitor_Temp : 40|8@1+ (1,-40) [-40.0|210.0] "C" Vector__XXX
 SG_ WATT_pBoard_Temp : 24|8@1+ (1,-40) [-40.0|210.0] "C" Vector__XXX
 SG_ WATT_pBaseplate_Temp : 16|8@1+ (1,-40) [-40.0|210.0] "C" Vector__XXX

BO_ 2566845696 AmbientConditions_0: 8 ECM
 SG_ DL_BarometricPressure : 0|16@1+ (0.007813,0) [0.0|511.99] "kPa" IC
 SG_ CabInteriorTemperature : 8|16@1+ (0.03125,-273) [-273.0|1735.0] "°C" IC
 SG_ AmbientAirTemperature : 24|16@1+ (0.03125,-273) [-273.0|1735.0] "°C" IC
 SG_ EngineAirInletTemperature : 40|8@1+ (1,-40) [-40.0|210.0] "°C" IC
 SG_ RoadSurfaceTemperature : 48|16@1+ (0.03125,-273) [-273.0|1734.96875] "°C" IC

BO_ 2566844672 CruiseControlVehSpeed_0: 8 ECM
 SG_ TwoSpeedAxleSwitch : 0|2@1+ (1,0) [0.0|3.0] "" IC
 SG_ ParkingBrakeSwitch : 2|2@1+ (1,0) [0.0|3.0] "" IC
 SG_ Wheel_BasedVehicleSpeed : 8|16@1+ (0.00390625,0) [0.0|251.0] "km/h" IC
 SG_ CruiseCtrlActive : 24|2@1+ (1,0) [0.0|3.0] "" IC
 SG_ CruiseCtrlEnableSwitch : 26|2@1+ (1,0) [0.0|3.0] "" IC
 SG_ BrakeSwitch : 28|2@1+ (1,0) [0.0|3.0] "" IC
 SG_ ClutchSwitch : 30|2@1+ (1,0) [0.0|3.0] "" IC
 SG_ CruiseCtrlSetSwitch : 32|2@1+ (1,0) [0.0|3.0] "" IC
 SG_ CruiseCtrlCoastSwitch : 34|2@1+ (1,0) [0.0|3.0] "" IC
 SG_ CruiseCtrlResumeSwitch : 36|2@1+ (1,0) [0.0|3.0] "" IC
 SG_ CruiseCtrlAccelerateSwitch : 38|2@1+ (1,0) [0.0|3.0] "" IC
 SG_ CruiseCtrlSetSpeed : 40|8@1+ (1,0) [0.0|250.0] "km/h" IC
 SG_ pOdometerDriveBit : 6|2@1+ (1,0) [0.0|3.0] "" IC
 SG_ CruiseCtrlPauseSw : 4|2@1+ (1,0) [0.0|3.0] "" IC
 SG_ pCCMessageCounter : 52|4@1+ (1,0) [0.0|15.0] "" IC
 SG_ pCCChecksum : 56|8@1+ (1,0) [0.0|255.0] "" IC
 SG_ pCruiseEnableStatus : 48|4@1+ (1,0) [0.0|15.0] "" IC

BO_ 2364539904 EEC1_0: 8 ECM
 SG_ EngineTorqueMode : 0|4@1+ (1,0) [0.0|13.0] "" IC
 SG_ DriversDemandEngine_PercTorque : 8|8@1+ (1,-125) [-125.0|125.0] "%" IC
 SG_ ActualEngine_PercTorque : 16|8@1+ (1,-125) [-125.0|125.0] "%" IC
 SG_ EngineSpeed : 24|16@1+ (0.125,0) [0.0|8031.88] "rpm" IC
 SG_ SourceAddress : 40|8@1+ (1,0) [0.0|253.0] "" IC
 SG_ EngineStarterMode : 48|4@1+ (1,0) [0.0|15.0] "" IC
 SG_ EngineDemand_PercentTorque : 56|8@1+ (1,-125) [-125.0|130.0] "%" IC

CM_ BO_ 2432656774  "Indicates the status of multiple operator controlled switches.";
CM_ BO_ 2565799489  "Used to claim an address by a module.";
CM_ BO_ 2565799453  "Used to claim an address by a module.";
CM_ BO_ 2565799447  "Used to claim an address by a module.";
CM_ BO_ 2565799443  "Used to claim an address by a module.";
CM_ BO_ 2565799435  "Used to claim an address by a module.";
CM_ BO_ 2565799424  "Used to claim an address by a module.";
CM_ BO_ 2631794205  "Used by the interface device to lock or unlock the lockabe/unlockable device.";
CM_ BO_ 2631794199  "Used by the interface device to lock or unlock the lockabe/unlockable device.";
CM_ BO_ 2631728640  "Used by the device to be locked/unlocked to communicate status and lock/unlock the device.";
CM_ BO_ 2561212031  "Text Display";
CM_ BO_ 2566844160  "Engine Fluid Pressures and Levels";
CM_ BO_ 2432658432  "Indicates the status of multiple operator controlled switches.";
CM_ BO_ 2633984512  "Status of Drive System Information";
CM_ BO_ 2565867008  "Electronic Axle Controller 1";
CM_ BO_ 2566834688  "Active diagnostic trouble codes";
CM_ BO_ 2564423168  "Memory Access Request";
CM_ BO_ 2564356352  "Memory Access Response / Output State Control";
CM_ BO_ 2633883392  "Front wheel drive ECU information.";
CM_ BO_ 2432656640  "Indicates the status of multiple operator controlled switches.";
CM_ BO_ 2365548032  "Engine Instrument Cluster Fast Update";
CM_ BO_ 2566913792  "ECU Data List 1";
CM_ BO_ 2566913536  "ECU Data List 2";
CM_ BO_ 2566913280  "ECU Data List 3";
CM_ BO_ 2566911744  "ECU Data List 9";
CM_ BO_ 2566911488  "ECU Data List 10";
CM_ BO_ 2566909952  "ECU Data List 11";
CM_ BO_ 2566909696  "ECU Data List 12";
CM_ BO_ 2566909440  "ECU Data List 13";
CM_ BO_ 2566909184  "ECU Data List 14";
CM_ BO_ 2566908928  "ECU Data List 15";
CM_ BO_ 2566908672  "ECU Data List 16";
CM_ BO_ 2566913024  "ECU Data List 4";
CM_ BO_ 2566912768  "ECU Data List 2";
CM_ BO_ 2566912512  "ECU Data List 6";
CM_ BO_ 2566912256  "ECU Data List 7";
CM_ BO_ 2566912000  "ECU Data List 8";
CM_ BO_ 2566908160  "ECU Data List 18";
CM_ BO_ 2633984768  "Requested message which contains calibratible parameters specific to a vehicle.";
CM_ BO_ 2566876928  "Information Requested from Engine";
CM_ BO_ 2566853886  "Contains information used on the Watt platform for electrical characteristics of the vehicle.";
CM_ BO_ 2566876416  "Drive Mode Information";
CM_ BO_ 2566825472  "Intake Manifold Information";
CM_ BO_ 2566804212  "This contains high resolution/range parameters reported from the alternator or power generation components.";
CM_ BO_ 2566804211  "This contains high resolution/range parameters reported from the alternator or power generation components.";
CM_ BO_ 2297441780  "The acceleration sensor message shall provide a measurement of the vehicle’s acceleration in the lateral, longitudinal, and vertical axes.";
CM_ BO_ 2566846452  "Vehicle Electrical Power Information";
CM_ BO_ 2297441779  "The acceleration sensor message shall provide a measurement of the vehicle’s acceleration in the lateral, longitudinal, and vertical axes.";
CM_ BO_ 2566846451  "Vehicle Electrical Power Information";
CM_ BO_ 2365525748  "BMC Power Information";
CM_ BO_ 2365525747  "BMC Power Information";
CM_ BO_ 2298415350  "Power Information for the Vehicle Motor";
CM_ BO_ 2298415606  "Temperature Information of Electrical System Components";
CM_ BO_ 2298415351  "Power Information for the Vehicle Motor";
CM_ BO_ 2298415607  "Temperature Information of Electrical System Components";
CM_ BO_ 2298415346  "Power Information for the Vehicle Motor";
CM_ BO_ 2298415602  "Temperature Information of Electrical System Components";
CM_ BO_ 2298415345  "Power Information for the Vehicle Motor";
CM_ BO_ 2298415601  "Temperature Information of Electrical System Components";
CM_ BO_ 2298415344  "Power Information for the Vehicle Motor";
CM_ BO_ 2298415600  "Temperature Information of Electrical System Components";
CM_ BO_ 2298415343  "Power Information for the Vehicle Motor";
CM_ BO_ 2298415599  "Temperature Information of Electrical System Components";
CM_ BO_ 2566845696  "Ambient Conditions Outside the vehicle";
CM_ BO_ 2566844672  "Cruise Control Status and Vehicle Speed Information";
CM_ BO_ 2364539904  "Electronic engine controller #1";
CM_ SG_ 2432656774 pOperatorButton29 "Drive Mode - 1()";
CM_ SG_ 2432656774 pOperatorButton1 "Instrument Cluster Control - 1";
CM_ SG_ 2432656774 pOperatorButton2 "Instrument Cluster Control  - 2";
CM_ SG_ 2432656774 pOperatorButton3 "Headlamp - 1 (Low)";
CM_ SG_ 2432656774 pOperatorButton4 "Headlamp - 2 (High)";
CM_ SG_ 2432656774 pOperatorButton5 "Headlamp - 3 (Driving)";
CM_ SG_ 2432656774 pOperatorButton6 "Turn - 1 (Left)";
CM_ SG_ 2432656774 pOperatorButton7 "Turn - 2 (Right)";
CM_ SG_ 2432656774 pOperatorButton8 "Turn - 3 (Cancel)";
CM_ SG_ 2432656774 pOperatorButton9 "Hazard";
CM_ SG_ 2432656774 pOperatorButton10 "Cruise - 1 (On)";
CM_ SG_ 2432656774 pOperatorButton11 "Cruise - 2 (Set)";
CM_ SG_ 2432656774 pOperatorButton12 "Cruise - 3 (Accel)";
CM_ SG_ 2432656774 pOperatorButton13 "Horn";
CM_ SG_ 2432656774 pOperatorButton14 "Start";
CM_ SG_ 2432656774 pOperatorButton15 "Warmer - 1";
CM_ SG_ 2432656774 pOperatorButton16 "Warmer - 2";
CM_ SG_ 2432656774 pOperatorButton17 "Warmer - 3";
CM_ SG_ 2432656774 pOperatorButton18 "Warmer - 4";
CM_ SG_ 2432656774 pOperatorButton19 "Windshield Wiper";
CM_ SG_ 2432656774 pOperatorButton20 "Engine On";
CM_ SG_ 2432656774 pOperatorButton21 "Reverse";
CM_ SG_ 2432656774 pOperatorButton22 "Homelink 1";
CM_ SG_ 2432656774 pOperatorButton23 "Homelink 2";
CM_ SG_ 2432656774 pOperatorButton24 "Throttle Safety Switch - 1";
CM_ SG_ 2432656774 pOperatorButton25 "Windshield - 1 (Up)";
CM_ SG_ 2432656774 pOperatorButton26 "Windshield - 2 (Down)";
CM_ SG_ 2432656774 pOperatorButton27 "Hand Brake Switch";
CM_ SG_ 2432656774 pOperatorButton28 "Clutch Switch";
CM_ SG_ 2432656774 pSideStandStatus "Status of the side stand switch of a motorcycle";
CM_ SG_ 2631794205 EncryptionIndicatorStates "This parameter is used to indicate if a random number of seed is being requested, or if an encrypted password is being provided
to the component.";
CM_ SG_ 2631794205 AntiTheftDesiredExitModeStates "This parameter is used to specify the desired triggers that are to be used by the component  in deciding when
to transition to the locked states.";
CM_ SG_ 2631794205 AntiTheftCommandStates "This parameter is used to identify the specific requests being sent to the component.";
CM_ SG_ 2631794205 AntiTheftPasswordRepresentation "This parameter is the 7-byte numeric code that is generated based on the encryption algorithm,
the password supplied by the end user, and the random number seed giben by the component.
";
CM_ SG_ 2631794199 EncryptionIndicatorStates "This parameter is used to indicate if a random number of seed is being requested, or if an encrypted password is being provided
to the component.";
CM_ SG_ 2631794199 AntiTheftDesiredExitModeStates "This parameter is used to specify the desired triggers that are to be used by the component  in deciding when
to transition to the locked states.";
CM_ SG_ 2631794199 AntiTheftCommandStates "This parameter is used to identify the specific requests being sent to the component.";
CM_ SG_ 2631794199 AntiTheftPasswordRepresentation "This parameter is the 7-byte numeric code that is generated based on the encryption algorithm,
the password supplied by the end user, and the random number seed giben by the component.
";
CM_ SG_ 2631728640 AntiTheftEncryptSeedPresentInd "Indicates the presence of the encryption seed random number.";
CM_ SG_ 2631728640 AntiTheftPasswordValidIndicator "Indicates the presence of a validated password.";
CM_ SG_ 2631728640 AntiTheftModifyPasswordStates "This parameter is used to indicate whether a password request was successfully performed, or if the
request could not be perform due to system constraints or if the request was not a valid request.";
CM_ SG_ 2631728640 AntiTheftRandomNumber "A 7-byte random numeric code provieded by the component in response to an anti-theft request.";
CM_ SG_ 2631728640 AntiTheftComponentStatusInd "Indicates wheter or not the component can be started.";
CM_ SG_ 2561212031 TextDisplayInstructions "This parameter describes the status for the display how to show the information.";
CM_ SG_ 2561212031 TextDisplayCharacter "From 1 up to 200 characters to be presented on a display. Up to 4 characters can be displayed without using Transport
Protocol.";
CM_ SG_ 2561212031 TextDisplayIndex "Used for overwriting consecutive bytes of a displayed string when byte 1 Text Display Instructions state is set for
overwrite substring mode.";
CM_ SG_ 2566844160 FuelDeliveryPressure "Not approved for use at Polaris at this time.";
CM_ SG_ 2566844160 EngineOilLevel "Ratio of current volume of engine sump oil to maximum required volume.";
CM_ SG_ 2566844160 EngineOilPressure "Gauge pressure of the oil in the engine lubrication system as provided by the oil pump.";
CM_ SG_ 2566844160 EngineCrankcasePressure "Gauge pressure inside engine crankcase.";
CM_ SG_ 2566844160 EngineCoolantPressure "Gauge pressure of liquid found in engine cooling system.";
CM_ SG_ 2566844160 EngineCoolantLevel "Ratio of volume of liquid found in engine cooling system to total cooling system volume. Typical monitoring locatin is in the coolant expansion tank.";
CM_ SG_ 2566844160 ExtCrankcaseBlowByPressure "Not approved for use at Polaris at this time.
(Differential crankcase blow-by pressure as measured through a tube with a venturi.)";
CM_ SG_ 2432658432 pOperatorButton42 "Momentary Driveline Right Press";
CM_ SG_ 2432658432 pOperatorButton41 "Momentary Driveline Left Press";
CM_ SG_ 2432658432 pOperatorButton39 "Work Mode Switch Status";
CM_ SG_ 2432658432 pOperatorButton37 "Work Group Switch Status";
CM_ SG_ 2432658432 pOperatorButton36 "Tilt Lock Switch Status";
CM_ SG_ 2432658432 pFOCCMessageCounter "Rolling Counter (ensures updated message is used).";
CM_ SG_ 2432658432 pFOCCChecksum "XOR of bytes 0-6 (ensures data is valid before use). ";
CM_ SG_ 2432658432 pOperatorButton40 "Foot On Cruise Control Switch";
CM_ SG_ 2432658432 pOperatorButton38 "Operator Present Switch";
CM_ SG_ 2432658432 pOperatorButton35 "Driver's Net Engagement";
CM_ SG_ 2432658432 pOperatorButton34 "Driver's Seatbelt Engagement";
CM_ SG_ 2432658432 pOperatorButton33 "PTO Mode Switch (RPM control)";
CM_ SG_ 2432658432 pOperatorButton32 "Drive Mode - 4()";
CM_ SG_ 2432658432 pOperatorButton31 "Drive Mode - 3()";
CM_ SG_ 2432658432 pOperatorButton30 "Drive Mode - 2()";
CM_ SG_ 2432658432 pOperatorButton29 "Drive Mode - 1()";
CM_ SG_ 2633984512 pHeatedGripEnable "Indicates if the controller broadcasting this SPN is calibrated to support vehicle speed limit 3";
CM_ SG_ 2633984512 pSideStandStatus "Status of the side stand switch of a motorcycle";
CM_ SG_ 2633984512 pTetherSwitchStatus "Status of the Tether Switch";
CM_ SG_ 2633984512 pLowFuelIndicatorStatus "Broadcasting the status of the fuel level for user indication.";
CM_ SG_ 2633984512 pOperatorNotInOperatingStation "Status of Operator presence in a vehicle";
CM_ SG_ 2633984512 pParkBrakeIndicatorStatus "Broadcasting the status of the park brake for user indication";
CM_ SG_ 2633984512 pADCRequested "Broadcasting the status of the users request for ADC mode";
CM_ SG_ 2633984512 pAWDModeRequested "Broadcasting the status of the users request for AWD mode";
CM_ SG_ 2633984512 pRWDModeRequested "Broadcasting the status of the users request for RWD mode";
CM_ SG_ 2633984512 pTurfModeRequested "Broadcasting the status of the users request for TURF mode";
CM_ SG_ 2633984512 pADCStatus "Broadcasting the status of the ADC (active indicates the solenoid is powered)";
CM_ SG_ 2633984512 pTreadleNeutralStatus "Broadcasting the status of the switch indicating the treadle is/is not in the Neutral position";
CM_ SG_ 2633984512 pTreadleReverseStatus "Broadcasting the status of the switch indicating the treadle is/is not in the Reverse position";
CM_ SG_ 2633984512 pSecurityLightStatus "Broadcasting the status of the security system for user indication";
CM_ SG_ 2633984512 pHighBeamIndicatorStatus "Broadcasting the status of the high beam headlight for user indication";
CM_ SG_ 2633984512 pHeatedGripsPercentage "Heated Grips Percent On, 0% is Off and 100% is the maximum heat";
CM_ SG_ 2633984512 pCruiseControlSetStatus "Broadcasting the status of the Cruise Control Set Status for user indication";
CM_ SG_ 2633984512 pSeatBeltIndicatorStatus "Broadcasting the status of the seat belt for user indication";
CM_ SG_ 2566847511 WasherFluidLevel "Not approved for use at Polaris at this time.";
CM_ SG_ 2566847511 FuelLevel "Ratio of volume of fuel to the total volume of fuel storage container.";
CM_ SG_ 2566847511 FuelFilterDiffPressure "Not approved for use at Polaris at this time.";
CM_ SG_ 2566847511 EngineOilFilterDiffPressure "Not approved for use at Polaris at this time.";
CM_ SG_ 2566847511 CargoAmbientTemperature "Not approved for use at Polaris at this time.";
CM_ SG_ 2566845719 CabInteriorTemperature "Not approved for use at Polaris at this time.";
CM_ SG_ 2566845719 AmbientAirTemperature "Temperature of air surrounding vehicle.";
CM_ SG_ 2566845719 EngineAirInletTemperature "Temperature of air entering vehicle air induction system.";
CM_ SG_ 2566845719 RoadSurfaceTemperature "Indicated temperature of road surface over which the vehicle is operating.";
CM_ SG_ 2566847488 WasherFluidLevel "Not approved for use at Polaris at this time.";
CM_ SG_ 2566847488 FuelLevel "Ratio of volume of fuel to the total volume of fuel storage container.";
CM_ SG_ 2566847488 FuelFilterDiffPressure "Not approved for use at Polaris at this time.";
CM_ SG_ 2566847488 EngineOilFilterDiffPressure "Not approved for use at Polaris at this time.";
CM_ SG_ 2566847488 CargoAmbientTemperature "Not approved for use at Polaris at this time.";
CM_ SG_ 2565867008 Location "To identify to which of several similar devices the information applies";
CM_ SG_ 2565867008 DifferentialLockFrontAxle1 "State used which indicates the condition of the front axle 1 differential lock. The differential locks are located as defined in firuge SPN564_A.";
CM_ SG_ 2565867008 DifferentialLockFrontAxle2 "Not approved for use at Polaris at this time.";
CM_ SG_ 2565867008 DifferentialLockRearAxle1 "Sate used which indicates the condition of the rear axle 1 differential lock. The differential locks are located as defined in figure SPN 564_A.";
CM_ SG_ 2565867008 DifferentialLockRearAxle2 "Not approved for use at Polaris at this time.";
CM_ SG_ 2565867008 DifferentialCentral "State used which indicates the condition of the central differential lock. The differential locks are located as defined in attached figure SPN564_A.";
CM_ SG_ 2565867008 DifferentialCentralFront "Not approved for use at Polaris at this time.";
CM_ SG_ 2565867008 DifferentialCentralRear "Not approved for use at Polaris at this time.";
CM_ SG_ 2566841600 EngTotalHoursOfOper "Accumulated time of operation of engine";
CM_ SG_ 2566841600 TotalEngineRevolutions "(Accumulated number of revolutions of engine crankshaft during its operation)";
CM_ SG_ 2566832407 HighResolTotalVehicleDistance "Accumulated distance traveled by the vehicle during its operation";
CM_ SG_ 2566832407 HighResolTripDistance "Distance traveled during all or part of a journey";
CM_ SG_ 2566834688 DM_ProtectLampStatus "This lamp is used to relay trouble code informatio that is reporting a problem with a vehicle system that is most
probably not electronic subsystem related.";
CM_ SG_ 2566834688 DM_RedStopLampState "This lamp is uesed to relay trouble code information that is of a severe enought condition that it warrants stopping the vehicle.";
CM_ SG_ 2566834688 DM_AmberWrningLmpStatus "This lamp is used to relay trouble code information that is reporting a problem with the vehicle system but the vehicle need
not be immediately stopped.";
CM_ SG_ 2566834688 DM_MalfuncnIndicatorLampStatus "A lamp used to relay only emissions-related trouble code information.";
CM_ SG_ 2566834688 DM_FlashRedStopLamp "Flash status of the Red Stop Lamp";
CM_ SG_ 2566834688 DM_FlashMalfuncIndicatorLamp "Flash status of the Malfunction Indicator Lamp";
CM_ SG_ 2566834688 DTC5 "Diagnostic Trouble Code";
CM_ SG_ 2566834688 DTC4 "Diagnostic Trouble Code";
CM_ SG_ 2566834688 DTC3 "Diagnostic Trouble Code";
CM_ SG_ 2566834688 DTC2 "Diagnostic Trouble Code";
CM_ SG_ 2566834688 DTC1 "Diagnostic Trouble Code";
CM_ SG_ 2566834688 DM_FlashProtectLamp "Flash status of the Stop Protect Lamp";
CM_ SG_ 2566834688 DM_FlashAmberWarningLamp "Flash status of the Amber Warning Lamp";
CM_ SG_ 2564423168 DM_NumberRequested "Length/Number Requested";
CM_ SG_ 2564423168 DM_UserLevel "Key/User Level";
CM_ SG_ 2633883392 FrtWheelDriveActuatorStatus "Feedback on the front wheel drive actuator.";
CM_ SG_ 2432656640 pOperatorButton29 "Drive Mode - 1()";
CM_ SG_ 2432656640 pOperatorButton1 "Instrument Cluster Control - 1";
CM_ SG_ 2432656640 pOperatorButton2 "Instrument Cluster Control  - 2";
CM_ SG_ 2432656640 pOperatorButton3 "Headlamp - 1 (Low)";
CM_ SG_ 2432656640 pOperatorButton4 "Headlamp - 2 (High)";
CM_ SG_ 2432656640 pOperatorButton5 "Headlamp - 3 (Driving)";
CM_ SG_ 2432656640 pOperatorButton6 "Turn - 1 (Left)";
CM_ SG_ 2432656640 pOperatorButton7 "Turn - 2 (Right)";
CM_ SG_ 2432656640 pOperatorButton8 "Turn - 3 (Cancel)";
CM_ SG_ 2432656640 pOperatorButton9 "Hazard";
CM_ SG_ 2432656640 pOperatorButton10 "Cruise - 1 (On)";
CM_ SG_ 2432656640 pOperatorButton11 "Cruise - 2 (Set)";
CM_ SG_ 2432656640 pOperatorButton12 "Cruise - 3 (Accel)";
CM_ SG_ 2432656640 pOperatorButton13 "Horn";
CM_ SG_ 2432656640 pOperatorButton14 "Start";
CM_ SG_ 2432656640 pOperatorButton15 "Warmer - 1";
CM_ SG_ 2432656640 pOperatorButton16 "Warmer - 2";
CM_ SG_ 2432656640 pOperatorButton17 "Warmer - 3";
CM_ SG_ 2432656640 pOperatorButton18 "Warmer - 4";
CM_ SG_ 2432656640 pOperatorButton19 "Windshield Wiper";
CM_ SG_ 2432656640 pOperatorButton20 "Engine On";
CM_ SG_ 2432656640 pOperatorButton21 "Reverse";
CM_ SG_ 2432656640 pOperatorButton22 "Homelink 1";
CM_ SG_ 2432656640 pOperatorButton23 "Homelink 2";
CM_ SG_ 2432656640 pOperatorButton24 "Throttle Safety Switch - 1";
CM_ SG_ 2432656640 pOperatorButton25 "Windshield - 1 (Up)";
CM_ SG_ 2432656640 pOperatorButton26 "Windshield - 2 (Down)";
CM_ SG_ 2432656640 pOperatorButton27 "Hand Brake Switch";
CM_ SG_ 2432656640 pOperatorButton28 "Clutch Switch";
CM_ SG_ 2432656640 pSideStandStatus "Status of the side stand switch of a motorcycle";
CM_ SG_ 2365548032 pHighIdleState "Indicates whether or not the engine control module has deliberately increased the idle RPM in order to boost system voltage.";
CM_ SG_ 2365548032 pEngineSpeed "Engine speed which includes RPM > 8000 rpm.";
CM_ SG_ 2365548032 pStuckThrottle "Signal which indicates whether or not the throttle is stuck open.";
CM_ SG_ 2365548032 pFuelRange "Distance vehicle can travel on fuel remaining in fuel tank";
CM_ SG_ 2566913792 DL1_EngineThrottlePosition "The position of the valve used to regulate the supply of a fluid, usually air or fuel/air mixture, to an engine.";
CM_ SG_ 2566913792 DL1_EngineSpeed "Actual engine speed which is calculated over a minimum crankshaft angle of 720 degrees divided by
the number of cylinders";
CM_ SG_ 2566913792 DL1_EngineCoolantTemperature "Temperature of liquid found in engine coolant system.";
CM_ SG_ 2566913792 DL1_EngIntakeManifoldPressure "Pressure of pre-combustion air found in intake manifold of engine air supply system.";
CM_ SG_ 2566913792 DL1_EngineAirInletTemperature "Temperature of air entering vehicle air induction system.";
CM_ SG_ 2566913792 DL1_BatteryPotential "This parameter measures the first souce of battery potential as measured at the input of the ECM/actuator etc. coming from one or more batteries, irrespective of the distance between the component
and the battery.";
CM_ SG_ 2566913536 DL2_EngineThrottlePosition "The position of the valve used to regulatethe supply of a fluid, usually air or fuel/air mixture, to an engine.";
CM_ SG_ 2566913536 DL2_EngineCoolantTemperature "Temperature of liquid found in engine coolant system.";
CM_ SG_ 2566913536 DL2_EngineAirInletTemperature "Temperature of air entering vehicle air induction system.";
CM_ SG_ 2566913536 DL2_EngIntakeManifoldPressure "Pressure of pre-combustion air found in intake manifold of engine air supply system.";
CM_ SG_ 2566913536 DL2_Boost "Gage pressure of air measured downstream on the compressor discharge side of the turbocharger.";
CM_ SG_ 2566913536 DL2_BarometricPressure "Absolute air pressure of the atmosphere.";
CM_ SG_ 2566913536 DL2_Wheel_BasedVehicleSpeed "Speed of the vehicle as calculated from wheel or tailshaft speed.";
CM_ SG_ 2566913536 DL2_BarometricPressure_Volts "Absolute air pressure of the atmosphere.";
CM_ SG_ 2566913280 DL3_IdleAirCntrlPosition "Current position of the idle air control stepper motor.";
CM_ SG_ 2566913280 DL3_DesiredIACPosition "Desired position of the idle air control stepper motor (IAC).";
CM_ SG_ 2566913280 DL3_EnginePercentLoad "Engine percent load.";
CM_ SG_ 2566913280 DL3_IdleTargetRPM "Target RPM for idle.";
CM_ SG_ 2566913280 DL3_EngineThrottlePositionHR "The position of the valve used to regulate the supply of a fluid, usually air or fuel/air mixture, to an engine.";
CM_ SG_ 2566909952 DL11_EngRunTime "Engine lifetime run time accumulator.";
CM_ SG_ 2566909952 DL11_EngRunTimeKeyOn "Engine run time since last key on.";
CM_ SG_ 2566912256 DL7_FuelTypSelected "Fuel Type Selected";
CM_ SG_ 2566912256 DL7_EngRunngMode "Data List - Engine Running Mode";
CM_ SG_ 2566912256 DL7_EngineThrottlePosition2 "The position of the valve used to regulate the supply of a fluid, usually air or fuel/air mixture, to an engine.";
CM_ SG_ 2566912256 DL7_SensorSupplyVoltage1 "Snow: DC-SDI includes TPS & TMAP PWR; DI is TPS1";
CM_ SG_ 2566912256 DL7_SensorSupplyVoltage2 "Snow: DC-SDI is Ground Speed Sensor PWR; DI includes TPS2, BAP & TMAP PWR";
CM_ SG_ 2566912256 DL7_SensorSupplyVoltage3 "Snow: DI Ground Speed Sensor Power";
CM_ SG_ 2566912256 DL7_ECUOutSupplyVoltage1 "Snow: DI Ignition Supply PWR";
CM_ SG_ 2566912256 DL7_ECUOutSupplyVoltage2 "Snow: DC-SDI Injection Supply PWR";
CM_ SG_ 2566910976 FI2_ReverseMotorDriveInput "Status of the reverse motor switch input; input is high (open circuit) when the selector lever is in the reverse position and low (closed to ground) when the lever is in the forward position.";
CM_ SG_ 2566908160 DL18_DesiredTorqueChg "The position of the valve used to regulatethe supply of a fluid, usually air or fuel/air mixture, to an engine.";
CM_ SG_ 2566908160 DL18_ThrottleAngleCorrFactor "The position of the valve used to regulatethe supply of a fluid, usually air or fuel/air mixture, to an engine.";
CM_ SG_ 2566908160 DL18_DragTorqueAdapt "The position of the valve used to regulatethe supply of a fluid, usually air or fuel/air mixture, to an engine.";
CM_ SG_ 2633984768 pADCModeAvailability "Used to let devices know if the vehicle is equipped with ADC";
CM_ SG_ 2633984768 pAWDModeAvailability "Used to let devices know if the vehicle is equipped with AWD";
CM_ SG_ 2633984768 pTurfModeAvailability "Used to let devices know if the vehicle is equipped with Turf Mode";
CM_ SG_ 2633984768 pDisplayedSpeedCorrectionFactor "Amount of adjustment to be applied by the speedometer to actual vehicle speed transmitted on the bus when displaying vehicle speed to the operator in order to correct for system variation.";
CM_ SG_ 2633984768 pInstrumentBacklightIntensity "Intensity (brightness) of instrumentation backlighting, 0% is no backlight and 100% is the maximum brightness the gauge is capable of.";
CM_ SG_ 2633984768 pWarningLampIntensity "Intensity (brightness) of warning lamp(s) which have the ability to be adjusted, 0% is warning lamp disabled and 100% is the maximum brightness the  warning lamp(s) are capable of.";
CM_ SG_ 2633984768 pFuelTankVolume "Total volume of fuel tank installed in vehicle";
CM_ SG_ 2633984768 pLowFuelLightONPercentage "Fuel percentage at which to turn the Low Fuel Light ON";
CM_ SG_ 2633984768 pFuelLevelDataSource "Fuel consumption data determination. Determines where the fuel sender resistive input is read";
CM_ SG_ 2633984768 pVehicleUnitsConfig "US12: MPH, Fahrenheit, US Gallon, 12-Hour Clock, PSI
INT12: km/h, Celsius, Liter, 12-hour Clock, kPa
UK12: MPH, Celsius, Imperial Gallon, 12-Hour Clock, PSI
*24-24-Hour Clock";
CM_ SG_ 2633984768 pFuelEconomyDataSource "Fuel Economy data determination. Determines where fuel economy (Range, Instantaneous and Average fuel economy) is calculated";
CM_ SG_ 2633984768 pSeatBeltInputSource "Determines what component reads the seat belt switch input.";
CM_ SG_ 2566847578 WasherFluidLevel "Not approved for use at Polaris at this time.";
CM_ SG_ 2566847578 FuelLevel "Ratio of volume of fuel to the total volume of fuel storage container.";
CM_ SG_ 2566847578 FuelFilterDiffPressure "Not approved for use at Polaris at this time.";
CM_ SG_ 2566847578 EngineOilFilterDiffPressure "Not approved for use at Polaris at this time.";
CM_ SG_ 2566847578 CargoAmbientTemperature "Not approved for use at Polaris at this time.";
CM_ SG_ 2566878604 pChecksum_524123 "Used to verify the signal path from the transmitting device to the receiving device. The message checksum is calculated using the first 7 data bytes, the message counter and the bytes of the message identifier.";
CM_ SG_ 2566878604 pMessageCounter_524122 "The message counter is used to detect situations where the transmitting ECU malfunction repeats the same frame all the time";
CM_ SG_ 2566878604 pOperationMode "Status of Manned or Remote Vehicle Operation Mode";
CM_ SG_ 2566878604 pStartStopCmd "Commanded Status of the Start Button";
CM_ SG_ 2566878604 pNorm_Acc_Pos_520354 "Indication of the current accelerator pedal position normalized to 0 to 100 %.  Commanded accelerator position as a percent of maximum accelerator position. ";
CM_ SG_ 2566878464 pStartStopCmd "Commanded Status of the Start Button";
CM_ SG_ 2566878464 pPedalPositionCommand "Pedal Position Requested in Percent of Pedal Travel Available";
CM_ SG_ 2566878464 pOperationMode "Status of Manned or Remote Vehicle Operation Mode";
CM_ SG_ 2566876928 pSecondaryAirValveControl "Secondary Air Valve Control Request Status";
CM_ SG_ 2566853886 pRangeToEmptyEV "Calculated range on remaining electrical power";
CM_ SG_ 2566853886 pEfficiencyEV "Calculated efficiency of an electric powertrain vehicle.";
CM_ SG_ 2566876416 pDriveModeCommanded "ASCII Representation of Drive Mode Commanded.";
CM_ SG_ 2566876416 pFootOnCruiseControlEnabled "Indicates whether or not the Foot on Cruise has been enabled.";
CM_ SG_ 2566876416 pDriveModeRequested "ASCII Representation of Drive Mode Requested.";
CM_ SG_ 2566825472 EngineTurbo1BoostPressure "Gage pressure of air measured downstream of the compressor discharge side of the turbocharger.";
CM_ SG_ 2566804212 NetBattCurrentHiRange "Net flow of electrical current into/out-of the battery or batteries.";
CM_ SG_ 2566804211 NetBattCurrentHiRange "Net flow of electrical current into/out-of the battery or batteries.";
CM_ SG_ 2566846452 Net_Battery_Current "Net flow of electrical current into/out of the battery or batteries";
CM_ SG_ 2566846452 BatteryPotential "This parameter measures the first souce of battery potential as measured at the input of the ECM/actuator etc. coming from one or more batteries, irrespective of the distance between the component
and the battery.";
CM_ SG_ 2566846451 Net_Battery_Current "Net flow of electrical current into/out of the battery or batteries";
CM_ SG_ 2566846451 BatteryPotential "This parameter measures the first souce of battery potential as measured at the input of the ECM/actuator etc. coming from one or more batteries, irrespective of the distance between the component
and the battery.";
CM_ SG_ 2365525748 WATT_pPack_Voltage "The voltage of the battery pack monitored by the Battery Management Controller (BMC).";
CM_ SG_ 2365525748 WATT_pPack_Current "The current of the battery pack monitored by the Battery Management Controller (BMC).";
CM_ SG_ 2365525748 WATT_pDischarge_Limit "The discharge limit of the battery pack monitored by the Battery Management Controller (BMC).";
CM_ SG_ 2365525748 WATT_pCharge_Limit "The Charge limit of the battery pack monitored by the Battery Management Controller (BMC).";
CM_ SG_ 2365525748 WATT_pBMC_Pwr_Msg_Check_Seq "Checksum ensures data is valid before use.";
CM_ SG_ 2365525747 WATT_pPack_Voltage "The voltage of the battery pack monitored by the Battery Management Controller (BMC).";
CM_ SG_ 2365525747 WATT_pPack_Current "The current of the battery pack monitored by the Battery Management Controller (BMC).";
CM_ SG_ 2365525747 WATT_pDischarge_Limit "The discharge limit of the battery pack monitored by the Battery Management Controller (BMC).";
CM_ SG_ 2365525747 WATT_pCharge_Limit "The Charge limit of the battery pack monitored by the Battery Management Controller (BMC).";
CM_ SG_ 2365525747 WATT_pBMC_Pwr_Msg_Check_Seq "Checksum ensures data is valid before use.";
CM_ SG_ 2298415350 WATT_pSpeed_Lim_Cutback_Status "Status bit indicating the ramp down of motor control output and subsequent vehicle performance due to the motor speed exceeding the limits set for the motor.";
CM_ SG_ 2298415350 WATT_pMotor_Therm_Cutback "Status bit indicating the ramp down of motor control output and subsequent vehicle performance due to the temperature of the motor exceeding a predefined value.";
CM_ SG_ 2298415350 WATT_pMotor_Power_Cutback_Status "Status bit indicating the ramp down of motor control output and subsequent vehicle performance due to low power availability.";
CM_ SG_ 2298415350 WATT_pI_DC_Cutback_Status "Status bit indicating the ramp down of motor control output and subsequent vehicle performance due to low Input Current.";
CM_ SG_ 2298415350 WATT_pController_Therm_Cutback "Status bit indicating the ramp down of motor control output and subsequent vehicle performance due to the temperature of the motor controller exceeding a predefined value.";
CM_ SG_ 2298415350 WATT_pPower_Msg_Check_Seq "Checksum ensures data is valid before use.";
CM_ SG_ 2298415350 WATT_pInput_Current "Input DC Current of the Electric Propulsion Control Unit or Auxiliary Power Control Unit from which the message is sent.";
CM_ SG_ 2298415350 WATT_pCapacitor_Voltage "Capacitor Voltage of the Electric Propulsion Control Unit or Auxiliary Power Control Unit from which the message is sent.";
CM_ SG_ 2298415606 WATT_pTemperature_Msg_Check_Seq "Checksum ensures data is valid before use.";
CM_ SG_ 2298415606 WATT_pMotor_Temp_Margin "The smallest difference between an internal motor component and its thermal limit for the Electric Propulsion Control Unit or Auxiliary Power Control Unit from which the message is sent";
CM_ SG_ 2298415606 WATT_pMotor_Temp "Actual motor temperature of the Electric Propulsion Unit or Auxiliary Power Unit from which the message is sent";
CM_ SG_ 2298415606 WATT_pJunction_Temp "Actual junction temperature of the Electric Propulsion Control Unit or Auxiliary Power Unit from which the message is sent";
CM_ SG_ 2298415606 WATT_pController_Temp_Margin "The smallest difference between an internal component and its thermal limit for the Electric Propulsion Control Unit or Auxiliary Power Control Unit from which the message is sent";
CM_ SG_ 2298415606 WATT_pCapacitor_Temp "Actual capacitor temperature of the Electric Propulsion Control Unit or Auxiliary Power Unit from which the message is sent";
CM_ SG_ 2298415606 WATT_pBoard_Temp "Board temperature of the Electric Propulsion Control Unit or Auxiliary Power Unit from which the message is sent";
CM_ SG_ 2298415606 WATT_pBaseplate_Temp "Actual baseplate temperature of the Electric Propulsion Control Unit or Auxiliary Power Unit from which the message is sent";
CM_ SG_ 2298415351 WATT_pSpeed_Lim_Cutback_Status "Status bit indicating the ramp down of motor control output and subsequent vehicle performance due to the motor speed exceeding the limits set for the motor.";
CM_ SG_ 2298415351 WATT_pMotor_Therm_Cutback "Status bit indicating the ramp down of motor control output and subsequent vehicle performance due to the temperature of the motor exceeding a predefined value.";
CM_ SG_ 2298415351 WATT_pMotor_Power_Cutback_Status "Status bit indicating the ramp down of motor control output and subsequent vehicle performance due to low power availability.";
CM_ SG_ 2298415351 WATT_pI_DC_Cutback_Status "Status bit indicating the ramp down of motor control output and subsequent vehicle performance due to low Input Current.";
CM_ SG_ 2298415351 WATT_pController_Therm_Cutback "Status bit indicating the ramp down of motor control output and subsequent vehicle performance due to the temperature of the motor controller exceeding a predefined value.";
CM_ SG_ 2298415351 WATT_pPower_Msg_Check_Seq "Checksum ensures data is valid before use.";
CM_ SG_ 2298415351 WATT_pInput_Current "Input DC Current of the Electric Propulsion Control Unit or Auxiliary Power Control Unit from which the message is sent.";
CM_ SG_ 2298415351 WATT_pCapacitor_Voltage "Capacitor Voltage of the Electric Propulsion Control Unit or Auxiliary Power Control Unit from which the message is sent.";
CM_ SG_ 2298415607 WATT_pTemperature_Msg_Check_Seq "Checksum ensures data is valid before use.";
CM_ SG_ 2298415607 WATT_pMotor_Temp_Margin "The smallest difference between an internal motor component and its thermal limit for the Electric Propulsion Control Unit or Auxiliary Power Control Unit from which the message is sent";
CM_ SG_ 2298415607 WATT_pMotor_Temp "Actual motor temperature of the Electric Propulsion Unit or Auxiliary Power Unit from which the message is sent";
CM_ SG_ 2298415607 WATT_pJunction_Temp "Actual junction temperature of the Electric Propulsion Control Unit or Auxiliary Power Unit from which the message is sent";
CM_ SG_ 2298415607 WATT_pController_Temp_Margin "The smallest difference between an internal component and its thermal limit for the Electric Propulsion Control Unit or Auxiliary Power Control Unit from which the message is sent";
CM_ SG_ 2298415607 WATT_pCapacitor_Temp "Actual capacitor temperature of the Electric Propulsion Control Unit or Auxiliary Power Unit from which the message is sent";
CM_ SG_ 2298415607 WATT_pBoard_Temp "Board temperature of the Electric Propulsion Control Unit or Auxiliary Power Unit from which the message is sent";
CM_ SG_ 2298415607 WATT_pBaseplate_Temp "Actual baseplate temperature of the Electric Propulsion Control Unit or Auxiliary Power Unit from which the message is sent";
CM_ SG_ 2365523456 pModCtlCmdState "The commanded control mode that the EPS unit will operate in";
CM_ SG_ 2298415346 WATT_pSpeed_Lim_Cutback_Status "Status bit indicating the ramp down of motor control output and subsequent vehicle performance due to the motor speed exceeding the limits set for the motor.";
CM_ SG_ 2298415346 WATT_pMotor_Therm_Cutback "Status bit indicating the ramp down of motor control output and subsequent vehicle performance due to the temperature of the motor exceeding a predefined value.";
CM_ SG_ 2298415346 WATT_pMotor_Power_Cutback_Status "Status bit indicating the ramp down of motor control output and subsequent vehicle performance due to low power availability.";
CM_ SG_ 2298415346 WATT_pI_DC_Cutback_Status "Status bit indicating the ramp down of motor control output and subsequent vehicle performance due to low Input Current.";
CM_ SG_ 2298415346 WATT_pController_Therm_Cutback "Status bit indicating the ramp down of motor control output and subsequent vehicle performance due to the temperature of the motor controller exceeding a predefined value.";
CM_ SG_ 2298415346 WATT_pPower_Msg_Check_Seq "Checksum ensures data is valid before use.";
CM_ SG_ 2298415346 WATT_pInput_Current "Input DC Current of the Electric Propulsion Control Unit or Auxiliary Power Control Unit from which the message is sent.";
CM_ SG_ 2298415346 WATT_pCapacitor_Voltage "Capacitor Voltage of the Electric Propulsion Control Unit or Auxiliary Power Control Unit from which the message is sent.";
CM_ SG_ 2298415602 WATT_pTemperature_Msg_Check_Seq "Checksum ensures data is valid before use.";
CM_ SG_ 2298415602 WATT_pMotor_Temp_Margin "The smallest difference between an internal motor component and its thermal limit for the Electric Propulsion Control Unit or Auxiliary Power Control Unit from which the message is sent";
CM_ SG_ 2298415602 WATT_pMotor_Temp "Actual motor temperature of the Electric Propulsion Unit or Auxiliary Power Unit from which the message is sent";
CM_ SG_ 2298415602 WATT_pJunction_Temp "Actual junction temperature of the Electric Propulsion Control Unit or Auxiliary Power Unit from which the message is sent";
CM_ SG_ 2298415602 WATT_pController_Temp_Margin "The smallest difference between an internal component and its thermal limit for the Electric Propulsion Control Unit or Auxiliary Power Control Unit from which the message is sent";
CM_ SG_ 2298415602 WATT_pCapacitor_Temp "Actual capacitor temperature of the Electric Propulsion Control Unit or Auxiliary Power Unit from which the message is sent";
CM_ SG_ 2298415602 WATT_pBoard_Temp "Board temperature of the Electric Propulsion Control Unit or Auxiliary Power Unit from which the message is sent";
CM_ SG_ 2298415602 WATT_pBaseplate_Temp "Actual baseplate temperature of the Electric Propulsion Control Unit or Auxiliary Power Unit from which the message is sent";
CM_ SG_ 2298415345 WATT_pSpeed_Lim_Cutback_Status "Status bit indicating the ramp down of motor control output and subsequent vehicle performance due to the motor speed exceeding the limits set for the motor.";
CM_ SG_ 2298415345 WATT_pMotor_Therm_Cutback "Status bit indicating the ramp down of motor control output and subsequent vehicle performance due to the temperature of the motor exceeding a predefined value.";
CM_ SG_ 2298415345 WATT_pMotor_Power_Cutback_Status "Status bit indicating the ramp down of motor control output and subsequent vehicle performance due to low power availability.";
CM_ SG_ 2298415345 WATT_pI_DC_Cutback_Status "Status bit indicating the ramp down of motor control output and subsequent vehicle performance due to low Input Current.";
CM_ SG_ 2298415345 WATT_pController_Therm_Cutback "Status bit indicating the ramp down of motor control output and subsequent vehicle performance due to the temperature of the motor controller exceeding a predefined value.";
CM_ SG_ 2298415345 WATT_pPower_Msg_Check_Seq "Checksum ensures data is valid before use.";
CM_ SG_ 2298415345 WATT_pInput_Current "Input DC Current of the Electric Propulsion Control Unit or Auxiliary Power Control Unit from which the message is sent.";
CM_ SG_ 2298415345 WATT_pCapacitor_Voltage "Capacitor Voltage of the Electric Propulsion Control Unit or Auxiliary Power Control Unit from which the message is sent.";
CM_ SG_ 2298415601 WATT_pTemperature_Msg_Check_Seq "Checksum ensures data is valid before use.";
CM_ SG_ 2298415601 WATT_pMotor_Temp_Margin "The smallest difference between an internal motor component and its thermal limit for the Electric Propulsion Control Unit or Auxiliary Power Control Unit from which the message is sent";
CM_ SG_ 2298415601 WATT_pMotor_Temp "Actual motor temperature of the Electric Propulsion Unit or Auxiliary Power Unit from which the message is sent";
CM_ SG_ 2298415601 WATT_pJunction_Temp "Actual junction temperature of the Electric Propulsion Control Unit or Auxiliary Power Unit from which the message is sent";
CM_ SG_ 2298415601 WATT_pController_Temp_Margin "The smallest difference between an internal component and its thermal limit for the Electric Propulsion Control Unit or Auxiliary Power Control Unit from which the message is sent";
CM_ SG_ 2298415601 WATT_pCapacitor_Temp "Actual capacitor temperature of the Electric Propulsion Control Unit or Auxiliary Power Unit from which the message is sent";
CM_ SG_ 2298415601 WATT_pBoard_Temp "Board temperature of the Electric Propulsion Control Unit or Auxiliary Power Unit from which the message is sent";
CM_ SG_ 2298415601 WATT_pBaseplate_Temp "Actual baseplate temperature of the Electric Propulsion Control Unit or Auxiliary Power Unit from which the message is sent";
CM_ SG_ 2298415344 WATT_pSpeed_Lim_Cutback_Status "Status bit indicating the ramp down of motor control output and subsequent vehicle performance due to the motor speed exceeding the limits set for the motor.";
CM_ SG_ 2298415344 WATT_pMotor_Therm_Cutback "Status bit indicating the ramp down of motor control output and subsequent vehicle performance due to the temperature of the motor exceeding a predefined value.";
CM_ SG_ 2298415344 WATT_pMotor_Power_Cutback_Status "Status bit indicating the ramp down of motor control output and subsequent vehicle performance due to low power availability.";
CM_ SG_ 2298415344 WATT_pI_DC_Cutback_Status "Status bit indicating the ramp down of motor control output and subsequent vehicle performance due to low Input Current.";
CM_ SG_ 2298415344 WATT_pController_Therm_Cutback "Status bit indicating the ramp down of motor control output and subsequent vehicle performance due to the temperature of the motor controller exceeding a predefined value.";
CM_ SG_ 2298415344 WATT_pPower_Msg_Check_Seq "Checksum ensures data is valid before use.";
CM_ SG_ 2298415344 WATT_pInput_Current "Input DC Current of the Electric Propulsion Control Unit or Auxiliary Power Control Unit from which the message is sent.";
CM_ SG_ 2298415344 WATT_pCapacitor_Voltage "Capacitor Voltage of the Electric Propulsion Control Unit or Auxiliary Power Control Unit from which the message is sent.";
CM_ SG_ 2298415600 WATT_pTemperature_Msg_Check_Seq "Checksum ensures data is valid before use.";
CM_ SG_ 2298415600 WATT_pMotor_Temp_Margin "The smallest difference between an internal motor component and its thermal limit for the Electric Propulsion Control Unit or Auxiliary Power Control Unit from which the message is sent";
CM_ SG_ 2298415600 WATT_pMotor_Temp "Actual motor temperature of the Electric Propulsion Unit or Auxiliary Power Unit from which the message is sent";
CM_ SG_ 2298415600 WATT_pJunction_Temp "Actual junction temperature of the Electric Propulsion Control Unit or Auxiliary Power Unit from which the message is sent";
CM_ SG_ 2298415600 WATT_pController_Temp_Margin "The smallest difference between an internal component and its thermal limit for the Electric Propulsion Control Unit or Auxiliary Power Control Unit from which the message is sent";
CM_ SG_ 2298415600 WATT_pCapacitor_Temp "Actual capacitor temperature of the Electric Propulsion Control Unit or Auxiliary Power Unit from which the message is sent";
CM_ SG_ 2298415600 WATT_pBoard_Temp "Board temperature of the Electric Propulsion Control Unit or Auxiliary Power Unit from which the message is sent";
CM_ SG_ 2298415600 WATT_pBaseplate_Temp "Actual baseplate temperature of the Electric Propulsion Control Unit or Auxiliary Power Unit from which the message is sent";
CM_ SG_ 2298415343 WATT_pController_Therm_Cutback "Status bit indicating the ramp down of motor control output and subsequent vehicle performance due to the temperature of the motor controller exceeding a predefined value.";
CM_ SG_ 2298415343 WATT_pSpeed_Lim_Cutback_Status "Status bit indicating the ramp down of motor control output and subsequent vehicle performance due to the motor speed exceeding the limits set for the motor.";
CM_ SG_ 2298415343 WATT_pMotor_Therm_Cutback "Status bit indicating the ramp down of motor control output and subsequent vehicle performance due to the temperature of the motor exceeding a predefined value.";
CM_ SG_ 2298415343 WATT_pMotor_Power_Cutback_Status "Status bit indicating the ramp down of motor control output and subsequent vehicle performance due to low power availability.";
CM_ SG_ 2298415343 WATT_pI_DC_Cutback_Status "Status bit indicating the ramp down of motor control output and subsequent vehicle performance due to low Input Current.";
CM_ SG_ 2298415343 WATT_pPower_Msg_Check_Seq "Checksum ensures data is valid before use.";
CM_ SG_ 2298415343 WATT_pInput_Current "Input DC Current of the Electric Propulsion Control Unit or Auxiliary Power Control Unit from which the message is sent.";
CM_ SG_ 2298415343 WATT_pCapacitor_Voltage "Capacitor Voltage of the Electric Propulsion Control Unit or Auxiliary Power Control Unit from which the message is sent.";
CM_ SG_ 2298415599 WATT_pTemperature_Msg_Check_Seq "Checksum ensures data is valid before use.";
CM_ SG_ 2298415599 WATT_pMotor_Temp_Margin "The smallest difference between an internal motor component and its thermal limit for the Electric Propulsion Control Unit or Auxiliary Power Control Unit from which the message is sent";
CM_ SG_ 2298415599 WATT_pMotor_Temp "Actual motor temperature of the Electric Propulsion Unit or Auxiliary Power Unit from which the message is sent";
CM_ SG_ 2298415599 WATT_pJunction_Temp "Actual junction temperature of the Electric Propulsion Control Unit or Auxiliary Power Unit from which the message is sent";
CM_ SG_ 2298415599 WATT_pController_Temp_Margin "The smallest difference between an internal component and its thermal limit for the Electric Propulsion Control Unit or Auxiliary Power Control Unit from which the message is sent";
CM_ SG_ 2298415599 WATT_pCapacitor_Temp "Actual capacitor temperature of the Electric Propulsion Control Unit or Auxiliary Power Unit from which the message is sent";
CM_ SG_ 2298415599 WATT_pBoard_Temp "Board temperature of the Electric Propulsion Control Unit or Auxiliary Power Unit from which the message is sent";
CM_ SG_ 2298415599 WATT_pBaseplate_Temp "Actual baseplate temperature of the Electric Propulsion Control Unit or Auxiliary Power Unit from which the message is sent";
CM_ SG_ 2566845696 CabInteriorTemperature "Not approved for use at Polaris at this time.";
CM_ SG_ 2566845696 AmbientAirTemperature "Temperature of air surrounding vehicle.";
CM_ SG_ 2566845696 EngineAirInletTemperature "Temperature of air entering vehicle air induction system.";
CM_ SG_ 2566845696 RoadSurfaceTemperature "Indicated temperature of road surface over which the vehicle is operating.";
CM_ SG_ 2566844672 TwoSpeedAxleSwitch "Switch signal which indicates the current axle range.";
CM_ SG_ 2566844672 ParkingBrakeSwitch "Switch signal which indicates when the parking brake is set. In general the switch actuated by the operator's park brake control,
whether a pedal, lever, or other control mechanism.";
CM_ SG_ 2566844672 Wheel_BasedVehicleSpeed "Speed of the vehicle as calculated from wheel or tailshaft speed.";
CM_ SG_ 2566844672 CruiseCtrlActive "Cruise control is switched on.  It is not ensured that the engine is controlled by cruise control, as in the case of a large driver's demand the engine is controlled by the driver while
cruise control is active.";
CM_ SG_ 2566844672 CruiseCtrlEnableSwitch "Switch signal which indicates that it is possible to manage the cruise control function";
CM_ SG_ 2566844672 BrakeSwitch "Switch signal which indicates that the driver operated brake foot pedal is being pressed";
CM_ SG_ 2566844672 ClutchSwitch "Switch signal which indicates that the clutch pedal is being pressed.  It is necessary for a safe drivetrain behavior that the clutch switch is set before the clutch is opened (cruise control function).";
CM_ SG_ 2566844672 CruiseCtrlSetSwitch "Switch signal of the cruise control activator which indicates that the activator is in the position 'set'.";
CM_ SG_ 2566844672 CruiseCtrlCoastSwitch "Switch signal of the cruise control activator which indicates that the activator is in the position 'coast'";
CM_ SG_ 2566844672 CruiseCtrlResumeSwitch "Switch signal of the cruise control activator which indicates that the activator is in the position 'resume'";
CM_ SG_ 2566844672 CruiseCtrlAccelerateSwitch "Switch signal of the cruise control activator which indicates that the activator is in the position 'accelerate'";
CM_ SG_ 2566844672 CruiseCtrlSetSpeed "Value of set (chosen) velocity of velocity control system.";
CM_ SG_ 2566844672 pOdometerDriveBit "Alternate state (A->B, B->A) each time the vehicle has moved a defined distance (currently 40m).";
CM_ SG_ 2566844672 CruiseCtrlPauseSw "Switch signal which indicates the positon of the Cruise Control Pause Switch used on Remote Cruise Control applications. The Cruise Control Pause Switch signal temporarily
disables the Cruise Control function.";
CM_ SG_ 2566844672 pCCMessageCounter "Rolling Counter (ensures updated message is used)";
CM_ SG_ 2566844672 pCCChecksum "XOR of bytes 0-6 (ensures data is valid before use)";
CM_ SG_ 2566844672 pCruiseEnableStatus "The Cruise Control System has been enabled by the operator.  (Amber Light)";
CM_ SG_ 2364539904 EngineTorqueMode "Signal which indicates which engine torque mode is currently generating, limiting or controlling the torque.";
CM_ SG_ 2364539904 DriversDemandEngine_PercTorque "The requested torque output of the engine by the driver.";
CM_ SG_ 2364539904 ActualEngine_PercTorque "The calculated output torque of the engine";
CM_ SG_ 2364539904 EngineSpeed "Actual engine speed.";
CM_ SG_ 2364539904 SourceAddress "Source address of controlling device for brake control.";
CM_ SG_ 2364539904 EngineStarterMode "There are several phases in a starting action and different reasons why a start cannot take place.";
CM_ SG_ 2364539904 EngineDemand_PercentTorque "The requested torque output of the engine by all dynamic internal inputs, including smoke control, noise control and low and high speed governing.";

BA_DEF_ BO_ "GenMsgCycleTime" INT 0 3600000;
BA_DEF_ BO_ "GenMsgCycleTimeFast" INT 0 3600000;
BA_DEF_ BO_ "GenMsgDelayTime" INT 0 1000;
BA_DEF_ BO_ "GenMsgILSupport" ENUM  "No","Yes";
BA_DEF_ BO_ "GenMsgRequestable" INT 0 1;
BA_DEF_ BO_ "GenMsgSendType" ENUM  "cyclic","spontaneous","cyclicIfActive","spontaneousWithDelay","cyclicAndSpontaneous","cyclicAndSpontaneousWithDelay","spontaneousWithRepetition","cyclicIfActiveAndSpontaneousWD";
BA_DEF_ BO_ "GenMsgStartDelayTime" INT 0 100000;
BA_DEF_ BO_ "J1939PGNameSecSrc0Dest3" STRING;
BA_DEF_ BO_ "J1939PGPrio" INT 0 7;
BA_DEF_ BO_ "J1939PGPrioSrc0Dest3" INT 0 7;
BA_DEF_ BO_ "J1939PGRelationDest3Src0" INT 0 254;
BA_DEF_ BO_ "J1939PGRelationSrc0Dest3" INT 0 254;
BA_DEF_ BO_ "J1939PGRepCycleSrc0Dest3" INT -1 65535;
BA_DEF_ BO_ "J1939PGRepTypeSrc0Dest3" INT 0 4;
BA_DEF_ BO_ "J1939PGRepetitionCycle" INT 0 65535;
BA_DEF_ BO_ "J1939PGRepetitionType" ENUM  "always","when active","on request";
BA_DEF_ BO_ "J1939PGtoECUSrc0Dest3" INT 0 254;
BA_DEF_ BO_ "J1939PGtoWSMSrc0Dest3" INT 0 254;
BA_DEF_ BO_ "TpJ1939VarDlc" ENUM  "No","Yes";
BA_DEF_ BO_ "VFrameFormat" ENUM  "StandardCAN","ExtendedCAN","reserved","J1939PG";
BA_DEF_ SG_ "GenSigEVName" STRING;
BA_DEF_ SG_ "GenSigILSupport" ENUM  "No","Yes";
BA_DEF_ SG_ "GenSigSendType" ENUM  "Cyclic","OnWrite","OnWriteWithRepetition","OnChange","OnChangeWithRepetition","IfActive","IfActiveWithRepetition","NoSigSendType";
BA_DEF_ SG_ "GenSigStartValue" INT 0 10000;
BA_DEF_ SG_ "SPN" INT 0 524287;
BA_DEF_ SG_ "SigType" ENUM  "Default","Range","RangeSigned","ASCII","Discrete","Control","ReferencePGN","DTC","StringDelimiter","StringLength","StringLengthControl","MessageCounter","MessageChecksum";
BA_DEF_ SG_ "SystemSignalLongSymbol" STRING;
BA_DEF_DEF_ "GenMsgCycleTime" 0;
BA_DEF_DEF_ "GenMsgCycleTimeFast" 0;
BA_DEF_DEF_ "GenMsgDelayTime" 0;
BA_DEF_DEF_ "GenMsgILSupport" "Yes";
BA_DEF_DEF_ "GenMsgRequestable" 1;
BA_DEF_DEF_ "GenMsgSendType" "noMsgSendType";
BA_DEF_DEF_ "GenMsgStartDelayTime" 0;
BA_DEF_DEF_ "GenSigEVName" "Env@Nodename_@Signame";
BA_DEF_DEF_ "GenSigILSupport" "Yes";
BA_DEF_DEF_ "GenSigSendType" "NoSigSendType";
BA_DEF_DEF_ "GenSigStartValue" 0;
BA_DEF_DEF_ "J1939PGNameSecSrc0Dest3" "(null)";
BA_DEF_DEF_ "J1939PGPrio" 6;
BA_DEF_DEF_ "J1939PGPrioSrc0Dest3" 6;
BA_DEF_DEF_ "J1939PGRelationDest3Src0" 254;
BA_DEF_DEF_ "J1939PGRelationSrc0Dest3" 254;
BA_DEF_DEF_ "J1939PGRepCycleSrc0Dest3" -1;
BA_DEF_DEF_ "J1939PGRepTypeSrc0Dest3" 3;
BA_DEF_DEF_ "J1939PGRepetitionCycle" 100;
BA_DEF_DEF_ "J1939PGRepetitionType" "always";
BA_DEF_DEF_ "J1939PGtoECUSrc0Dest3" -1;
BA_DEF_DEF_ "J1939PGtoWSMSrc0Dest3" -1;
BA_DEF_DEF_ "SPN" 0;
BA_DEF_DEF_ "SigType" "Default";
BA_DEF_DEF_ "SystemSignalLongSymbol" "";
BA_DEF_DEF_ "TpJ1939VarDlc" "No";
BA_DEF_DEF_ "VFrameFormat" "J1939PG";
BA_ "GenMsgCycleTime" BO_ 2432656774 100;
BA_ "GenMsgSendType" BO_ 2432656774 0;
BA_ "GenMsgCycleTime" BO_ 2565799489 100;
BA_ "GenMsgSendType" BO_ 2565799489 0;
BA_ "GenMsgCycleTime" BO_ 2565799453 100;
BA_ "GenMsgSendType" BO_ 2565799453 0;
BA_ "GenMsgCycleTime" BO_ 2565799447 100;
BA_ "GenMsgSendType" BO_ 2565799447 0;
BA_ "GenMsgCycleTime" BO_ 2565799443 100;
BA_ "GenMsgSendType" BO_ 2565799443 0;
BA_ "GenMsgCycleTime" BO_ 2565799435 100;
BA_ "GenMsgSendType" BO_ 2565799435 0;
BA_ "GenMsgCycleTime" BO_ 2565799424 100;
BA_ "GenMsgSendType" BO_ 2565799424 0;
BA_ "GenMsgCycleTime" BO_ 2631794205 100;
BA_ "GenMsgSendType" BO_ 2631794205 0;
BA_ "GenMsgCycleTime" BO_ 2631794199 100;
BA_ "GenMsgSendType" BO_ 2631794199 0;
BA_ "GenMsgCycleTime" BO_ 2631728640 100;
BA_ "GenMsgSendType" BO_ 2631728640 0;
BA_ "GenMsgCycleTime" BO_ 2561212031 100;
BA_ "GenMsgSendType" BO_ 2561212031 0;
BA_ "GenMsgCycleTime" BO_ 2566844160 500;
BA_ "GenMsgCycleTime" BO_ 2432658432 100;
BA_ "GenMsgCycleTime" BO_ 2633984512 100;
BA_ "GenMsgSendType" BO_ 2633984512 0;
BA_ "GenMsgCycleTime" BO_ 2566847511 1000;
BA_ "GenMsgSendType" BO_ 2566847511 0;
BA_ "GenMsgCycleTime" BO_ 2566845719 1000;
BA_ "GenMsgSendType" BO_ 2566845719 0;
BA_ "GenMsgCycleTime" BO_ 2566847488 1000;
BA_ "GenMsgSendType" BO_ 2566847488 0;
BA_ "GenMsgCycleTime" BO_ 2565867008 500;
BA_ "GenMsgCycleTime" BO_ 2566841600 100;
BA_ "GenMsgCycleTime" BO_ 2566832407 1000;
BA_ "GenMsgSendType" BO_ 2566832407 0;
BA_ "GenMsgCycleTime" BO_ 2566834688 100;
BA_ "GenMsgCycleTime" BO_ 2564423168 100;
BA_ "GenMsgCycleTime" BO_ 2564356352 100;
BA_ "GenMsgCycleTime" BO_ 2633883392 500;
BA_ "GenMsgSendType" BO_ 2633883392 0;
BA_ "GenMsgCycleTime" BO_ 2432656640 100;
BA_ "GenMsgCycleTime" BO_ 2365548032 100;
BA_ "GenMsgSendType" BO_ 2365548032 0;
BA_ "GenMsgCycleTime" BO_ 2566902272 100;
BA_ "GenMsgCycleTime" BO_ 2566847578 1000;
BA_ "GenMsgSendType" BO_ 2566847578 0;
BA_ "GenMsgCycleTime" BO_ 2566878604 200;
BA_ "GenMsgCycleTimeFast" BO_ 2566878604 10;
BA_ "GenMsgSendType" BO_ 2566878604 4;
BA_ "GenMsgCycleTime" BO_ 2566878464 10;
BA_ "GenMsgSendType" BO_ 2566878464 0;
BA_ "GenMsgCycleTime" BO_ 2566876928 1000;
BA_ "GenMsgSendType" BO_ 2566876928 0;
BA_ "GenMsgCycleTime" BO_ 2566853886 100;
BA_ "GenMsgSendType" BO_ 2566853886 0;
BA_ "GenMsgCycleTime" BO_ 2566876416 100;
BA_ "GenMsgSendType" BO_ 2566876416 0;
BA_ "GenMsgCycleTime" BO_ 2566825472 500;
BA_ "GenMsgSendType" BO_ 2566825472 0;
BA_ "GenMsgCycleTime" BO_ 2297441780 10;
BA_ "GenMsgSendType" BO_ 2297441780 0;
BA_ "GenMsgCycleTime" BO_ 2566846452 1000;
BA_ "GenMsgSendType" BO_ 2566846452 0;
BA_ "GenMsgCycleTime" BO_ 2297441779 10;
BA_ "GenMsgSendType" BO_ 2297441779 0;
BA_ "J1939PGRepetitionCycle" BO_ 2297441779 10;
BA_ "GenMsgCycleTime" BO_ 2566846451 1000;
BA_ "GenMsgSendType" BO_ 2566846451 0;
BA_ "GenMsgCycleTime" BO_ 2365525748 10;
BA_ "GenMsgSendType" BO_ 2365525748 0;
BA_ "GenMsgCycleTime" BO_ 2365525747 10;
BA_ "GenMsgSendType" BO_ 2365525747 0;
BA_ "GenMsgCycleTime" BO_ 2298415350 100;
BA_ "GenMsgSendType" BO_ 2298415350 0;
BA_ "GenMsgCycleTime" BO_ 2298415606 100;
BA_ "GenMsgSendType" BO_ 2298415606 0;
BA_ "GenMsgCycleTime" BO_ 2298415351 100;
BA_ "GenMsgSendType" BO_ 2298415351 0;
BA_ "GenMsgCycleTime" BO_ 2298415607 100;
BA_ "GenMsgSendType" BO_ 2298415607 0;
BA_ "GenMsgCycleTime" BO_ 2365523456 5000;
BA_ "GenMsgCycleTimeFast" BO_ 2365523456 50;
BA_ "GenMsgSendType" BO_ 2365523456 4;
BA_ "GenMsgCycleTime" BO_ 2298415346 100;
BA_ "GenMsgSendType" BO_ 2298415346 0;
BA_ "GenMsgCycleTime" BO_ 2298415602 100;
BA_ "GenMsgSendType" BO_ 2298415602 0;
BA_ "GenMsgCycleTime" BO_ 2298415345 100;
BA_ "GenMsgSendType" BO_ 2298415345 0;
BA_ "GenMsgCycleTime" BO_ 2298415601 100;
BA_ "GenMsgSendType" BO_ 2298415601 0;
BA_ "GenMsgCycleTime" BO_ 2298415344 100;
BA_ "GenMsgSendType" BO_ 2298415344 0;
BA_ "GenMsgCycleTime" BO_ 2298415600 100;
BA_ "GenMsgSendType" BO_ 2298415600 0;
BA_ "GenMsgCycleTime" BO_ 2298415343 100;
BA_ "GenMsgSendType" BO_ 2298415343 0;
BA_ "GenMsgCycleTime" BO_ 2298415599 100;
BA_ "GenMsgSendType" BO_ 2298415599 0;
BA_ "GenMsgCycleTime" BO_ 2566845696 1000;
BA_ "GenMsgSendType" BO_ 2566845696 0;
BA_ "GenMsgCycleTime" BO_ 2566844672 100;
BA_ "GenMsgSendType" BO_ 2566844672 0;
BA_ "GenMsgCycleTime" BO_ 2364539904 100;
BA_ "GenMsgSendType" BO_ 2364539904 0;
BA_ "SPN" SG_ 2432656774 pOperatorButton29 524060;
BA_ "SPN" SG_ 2432656774 pOperatorButton1 524059;
BA_ "SigType" SG_ 2432656774 pOperatorButton1 1.7E-308;
BA_ "SPN" SG_ 2432656774 pOperatorButton2 524058;
BA_ "SigType" SG_ 2432656774 pOperatorButton2 1.7E-308;
BA_ "SPN" SG_ 2432656774 pOperatorButton3 524057;
BA_ "SigType" SG_ 2432656774 pOperatorButton3 1.7E-308;
BA_ "SPN" SG_ 2432656774 pOperatorButton4 524056;
BA_ "SigType" SG_ 2432656774 pOperatorButton4 1.7E-308;
BA_ "SPN" SG_ 2432656774 pOperatorButton5 524055;
BA_ "SigType" SG_ 2432656774 pOperatorButton5 1.7E-308;
BA_ "SPN" SG_ 2432656774 pOperatorButton6 524054;
BA_ "SigType" SG_ 2432656774 pOperatorButton6 1.7E-308;
BA_ "SPN" SG_ 2432656774 pOperatorButton7 524053;
BA_ "SigType" SG_ 2432656774 pOperatorButton7 1.7E-308;
BA_ "SPN" SG_ 2432656774 pOperatorButton8 524052;
BA_ "SigType" SG_ 2432656774 pOperatorButton8 1.7E-308;
BA_ "SPN" SG_ 2432656774 pOperatorButton9 524051;
BA_ "SigType" SG_ 2432656774 pOperatorButton9 1.7E-308;
BA_ "SPN" SG_ 2432656774 pOperatorButton10 524050;
BA_ "SigType" SG_ 2432656774 pOperatorButton10 1.7E-308;
BA_ "SPN" SG_ 2432656774 pOperatorButton11 524049;
BA_ "SigType" SG_ 2432656774 pOperatorButton11 1.7E-308;
BA_ "SPN" SG_ 2432656774 pOperatorButton12 524048;
BA_ "SigType" SG_ 2432656774 pOperatorButton12 1.7E-308;
BA_ "SPN" SG_ 2432656774 pOperatorButton13 524047;
BA_ "SigType" SG_ 2432656774 pOperatorButton13 1.7E-308;
BA_ "SPN" SG_ 2432656774 pOperatorButton14 524046;
BA_ "SigType" SG_ 2432656774 pOperatorButton14 1.7E-308;
BA_ "SPN" SG_ 2432656774 pOperatorButton15 524045;
BA_ "SigType" SG_ 2432656774 pOperatorButton15 1.7E-308;
BA_ "SPN" SG_ 2432656774 pOperatorButton16 524044;
BA_ "SigType" SG_ 2432656774 pOperatorButton16 1.7E-308;
BA_ "SPN" SG_ 2432656774 pOperatorButton17 524043;
BA_ "SigType" SG_ 2432656774 pOperatorButton17 1.7E-308;
BA_ "SPN" SG_ 2432656774 pOperatorButton18 524042;
BA_ "SigType" SG_ 2432656774 pOperatorButton18 1.7E-308;
BA_ "SPN" SG_ 2432656774 pOperatorButton19 524041;
BA_ "SigType" SG_ 2432656774 pOperatorButton19 1.7E-308;
BA_ "SPN" SG_ 2432656774 pOperatorButton20 524040;
BA_ "SigType" SG_ 2432656774 pOperatorButton20 1.7E-308;
BA_ "SPN" SG_ 2432656774 pOperatorButton21 524039;
BA_ "SigType" SG_ 2432656774 pOperatorButton21 1.7E-308;
BA_ "SPN" SG_ 2432656774 pOperatorButton22 524038;
BA_ "SigType" SG_ 2432656774 pOperatorButton22 1.7E-308;
BA_ "SPN" SG_ 2432656774 pOperatorButton23 524037;
BA_ "SigType" SG_ 2432656774 pOperatorButton23 1.7E-308;
BA_ "SPN" SG_ 2432656774 pOperatorButton24 524036;
BA_ "SigType" SG_ 2432656774 pOperatorButton24 1.7E-308;
BA_ "SPN" SG_ 2432656774 pOperatorButton25 524035;
BA_ "SigType" SG_ 2432656774 pOperatorButton25 1.7E-308;
BA_ "SPN" SG_ 2432656774 pOperatorButton26 524034;
BA_ "SigType" SG_ 2432656774 pOperatorButton26 1.7E-308;
BA_ "SPN" SG_ 2432656774 pOperatorButton27 520322;
BA_ "SigType" SG_ 2432656774 pOperatorButton27 1.7E-308;
BA_ "SPN" SG_ 2432656774 pOperatorButton28 524032;
BA_ "SigType" SG_ 2432656774 pOperatorButton28 1.7E-308;
BA_ "SPN" SG_ 2432656774 pSideStandStatus 524098;
BA_ "SigType" SG_ 2432656774 pSideStandStatus 1.7E-308;
BA_ "SPN" SG_ 2565799489 IdentityNumber 2837;
BA_ "SigType" SG_ 2565799489 IdentityNumber 1.7E-308;
BA_ "SPN" SG_ 2565799489 ManufacturerCode 2838;
BA_ "SigType" SG_ 2565799489 ManufacturerCode 1.7E-308;
BA_ "SPN" SG_ 2565799489 ECUInstance 2840;
BA_ "SigType" SG_ 2565799489 ECUInstance 1.7E-308;
BA_ "SPN" SG_ 2565799489 FunctionInstance 2839;
BA_ "SigType" SG_ 2565799489 FunctionInstance 1.7E-308;
BA_ "SPN" SG_ 2565799489 Function 2841;
BA_ "SigType" SG_ 2565799489 Function 1.7E-308;
BA_ "SPN" SG_ 2565799489 VehicleSystem 2842;
BA_ "SigType" SG_ 2565799489 VehicleSystem 1.7E-308;
BA_ "SPN" SG_ 2565799489 VehicleSystemInstance 2843;
BA_ "SigType" SG_ 2565799489 VehicleSystemInstance 1.7E-308;
BA_ "SPN" SG_ 2565799489 IndustryGroup 2846;
BA_ "SigType" SG_ 2565799489 IndustryGroup 1.7E-308;
BA_ "SPN" SG_ 2565799489 ArbitraryAddressCapable 2844;
BA_ "SigType" SG_ 2565799489 ArbitraryAddressCapable 1.7E-308;
BA_ "SPN" SG_ 2565799453 IdentityNumber 2837;
BA_ "SigType" SG_ 2565799453 IdentityNumber 1.7E-308;
BA_ "SPN" SG_ 2565799453 ManufacturerCode 2838;
BA_ "SigType" SG_ 2565799453 ManufacturerCode 1.7E-308;
BA_ "SPN" SG_ 2565799453 ECUInstance 2840;
BA_ "SigType" SG_ 2565799453 ECUInstance 1.7E-308;
BA_ "SPN" SG_ 2565799453 FunctionInstance 2839;
BA_ "SigType" SG_ 2565799453 FunctionInstance 1.7E-308;
BA_ "SPN" SG_ 2565799453 Function 2841;
BA_ "SigType" SG_ 2565799453 Function 1.7E-308;
BA_ "SPN" SG_ 2565799453 VehicleSystem 2842;
BA_ "SigType" SG_ 2565799453 VehicleSystem 1.7E-308;
BA_ "SPN" SG_ 2565799453 VehicleSystemInstance 2843;
BA_ "SigType" SG_ 2565799453 VehicleSystemInstance 1.7E-308;
BA_ "SPN" SG_ 2565799453 IndustryGroup 2846;
BA_ "SigType" SG_ 2565799453 IndustryGroup 1.7E-308;
BA_ "SPN" SG_ 2565799453 ArbitraryAddressCapable 2844;
BA_ "SigType" SG_ 2565799453 ArbitraryAddressCapable 1.7E-308;
BA_ "SPN" SG_ 2565799447 IdentityNumber 2837;
BA_ "SigType" SG_ 2565799447 IdentityNumber 1.7E-308;
BA_ "SPN" SG_ 2565799447 ManufacturerCode 2838;
BA_ "SigType" SG_ 2565799447 ManufacturerCode 1.7E-308;
BA_ "SPN" SG_ 2565799447 ECUInstance 2840;
BA_ "SigType" SG_ 2565799447 ECUInstance 1.7E-308;
BA_ "SPN" SG_ 2565799447 FunctionInstance 2839;
BA_ "SigType" SG_ 2565799447 FunctionInstance 1.7E-308;
BA_ "SPN" SG_ 2565799447 Function 2841;
BA_ "SigType" SG_ 2565799447 Function 1.7E-308;
BA_ "SPN" SG_ 2565799447 VehicleSystem 2842;
BA_ "SigType" SG_ 2565799447 VehicleSystem 1.7E-308;
BA_ "SPN" SG_ 2565799447 VehicleSystemInstance 2843;
BA_ "SigType" SG_ 2565799447 VehicleSystemInstance 1.7E-308;
BA_ "SPN" SG_ 2565799447 IndustryGroup 2846;
BA_ "SigType" SG_ 2565799447 IndustryGroup 1.7E-308;
BA_ "SPN" SG_ 2565799447 ArbitraryAddressCapable 2844;
BA_ "SigType" SG_ 2565799447 ArbitraryAddressCapable 1.7E-308;
BA_ "SPN" SG_ 2565799443 IdentityNumber 2837;
BA_ "SigType" SG_ 2565799443 IdentityNumber 1.7E-308;
BA_ "SPN" SG_ 2565799443 ManufacturerCode 2838;
BA_ "SigType" SG_ 2565799443 ManufacturerCode 1.7E-308;
BA_ "SPN" SG_ 2565799443 ECUInstance 2840;
BA_ "SigType" SG_ 2565799443 ECUInstance 1.7E-308;
BA_ "SPN" SG_ 2565799443 FunctionInstance 2839;
BA_ "SigType" SG_ 2565799443 FunctionInstance 1.7E-308;
BA_ "SPN" SG_ 2565799443 Function 2841;
BA_ "SigType" SG_ 2565799443 Function 1.7E-308;
BA_ "SPN" SG_ 2565799443 VehicleSystem 2842;
BA_ "SigType" SG_ 2565799443 VehicleSystem 1.7E-308;
BA_ "SPN" SG_ 2565799443 VehicleSystemInstance 2843;
BA_ "SigType" SG_ 2565799443 VehicleSystemInstance 1.7E-308;
BA_ "SPN" SG_ 2565799443 IndustryGroup 2846;
BA_ "SigType" SG_ 2565799443 IndustryGroup 1.7E-308;
BA_ "SPN" SG_ 2565799443 ArbitraryAddressCapable 2844;
BA_ "SigType" SG_ 2565799443 ArbitraryAddressCapable 1.7E-308;
BA_ "SPN" SG_ 2565799435 IdentityNumber 2837;
BA_ "SigType" SG_ 2565799435 IdentityNumber 1.7E-308;
BA_ "SPN" SG_ 2565799435 ManufacturerCode 2838;
BA_ "SigType" SG_ 2565799435 ManufacturerCode 1.7E-308;
BA_ "SPN" SG_ 2565799435 ECUInstance 2840;
BA_ "SigType" SG_ 2565799435 ECUInstance 1.7E-308;
BA_ "SPN" SG_ 2565799435 FunctionInstance 2839;
BA_ "SigType" SG_ 2565799435 FunctionInstance 1.7E-308;
BA_ "SPN" SG_ 2565799435 Function 2841;
BA_ "SigType" SG_ 2565799435 Function 1.7E-308;
BA_ "SPN" SG_ 2565799435 VehicleSystem 2842;
BA_ "SigType" SG_ 2565799435 VehicleSystem 1.7E-308;
BA_ "SPN" SG_ 2565799435 VehicleSystemInstance 2843;
BA_ "SigType" SG_ 2565799435 VehicleSystemInstance 1.7E-308;
BA_ "SPN" SG_ 2565799435 IndustryGroup 2846;
BA_ "SigType" SG_ 2565799435 IndustryGroup 1.7E-308;
BA_ "SPN" SG_ 2565799435 ArbitraryAddressCapable 2844;
BA_ "SigType" SG_ 2565799435 ArbitraryAddressCapable 1.7E-308;
BA_ "SPN" SG_ 2565799424 IdentityNumber 2837;
BA_ "SigType" SG_ 2565799424 IdentityNumber 1.7E-308;
BA_ "SPN" SG_ 2565799424 ManufacturerCode 2838;
BA_ "SigType" SG_ 2565799424 ManufacturerCode 1.7E-308;
BA_ "SPN" SG_ 2565799424 ECUInstance 2840;
BA_ "SigType" SG_ 2565799424 ECUInstance 1.7E-308;
BA_ "SPN" SG_ 2565799424 FunctionInstance 2839;
BA_ "SigType" SG_ 2565799424 FunctionInstance 1.7E-308;
BA_ "SPN" SG_ 2565799424 Function 2841;
BA_ "SigType" SG_ 2565799424 Function 1.7E-308;
BA_ "SPN" SG_ 2565799424 VehicleSystem 2842;
BA_ "SigType" SG_ 2565799424 VehicleSystem 1.7E-308;
BA_ "SPN" SG_ 2565799424 VehicleSystemInstance 2843;
BA_ "SigType" SG_ 2565799424 VehicleSystemInstance 1.7E-308;
BA_ "SPN" SG_ 2565799424 IndustryGroup 2846;
BA_ "SigType" SG_ 2565799424 IndustryGroup 1.7E-308;
BA_ "SPN" SG_ 2565799424 ArbitraryAddressCapable 2844;
BA_ "SigType" SG_ 2565799424 ArbitraryAddressCapable 1.7E-308;
BA_ "SPN" SG_ 2631794205 EncryptionIndicatorStates 1199;
BA_ "SigType" SG_ 2631794205 EncryptionIndicatorStates 1.7E-308;
BA_ "SPN" SG_ 2631794205 AntiTheftDesiredExitModeStates 1200;
BA_ "SigType" SG_ 2631794205 AntiTheftDesiredExitModeStates 1.7E-308;
BA_ "SPN" SG_ 2631794205 AntiTheftCommandStates 1201;
BA_ "SigType" SG_ 2631794205 AntiTheftCommandStates 1.7E-308;
BA_ "SPN" SG_ 2631794205 AntiTheftPasswordRepresentation 1202;
BA_ "SigType" SG_ 2631794205 AntiTheftPasswordRepresentation 1.7E-308;
BA_ "SPN" SG_ 2631794199 EncryptionIndicatorStates 1199;
BA_ "SigType" SG_ 2631794199 EncryptionIndicatorStates 1.7E-308;
BA_ "SPN" SG_ 2631794199 AntiTheftDesiredExitModeStates 1200;
BA_ "SigType" SG_ 2631794199 AntiTheftDesiredExitModeStates 1.7E-308;
BA_ "SPN" SG_ 2631794199 AntiTheftCommandStates 1201;
BA_ "SigType" SG_ 2631794199 AntiTheftCommandStates 1.7E-308;
BA_ "SPN" SG_ 2631794199 AntiTheftPasswordRepresentation 1202;
BA_ "SigType" SG_ 2631794199 AntiTheftPasswordRepresentation 1.7E-308;
BA_ "SPN" SG_ 2631728640 AntiTheftEncryptSeedPresentInd 1194;
BA_ "SigType" SG_ 2631728640 AntiTheftEncryptSeedPresentInd 1.7E-308;
BA_ "SPN" SG_ 2631728640 AntiTheftPasswordValidIndicator 1195;
BA_ "SigType" SG_ 2631728640 AntiTheftPasswordValidIndicator 1.7E-308;
BA_ "SPN" SG_ 2631728640 AntiTheftModifyPasswordStates 1197;
BA_ "SigType" SG_ 2631728640 AntiTheftModifyPasswordStates 1.7E-308;
BA_ "SPN" SG_ 2631728640 AntiTheftRandomNumber 1198;
BA_ "SigType" SG_ 2631728640 AntiTheftRandomNumber 1.7E-308;
BA_ "SPN" SG_ 2631728640 AntiTheftComponentStatusInd 1196;
BA_ "SigType" SG_ 2631728640 AntiTheftComponentStatusInd 1.7E-308;
BA_ "SPN" SG_ 2561212031 TextDisplayInstructions 3613;
BA_ "SigType" SG_ 2561212031 TextDisplayInstructions 1.7E-308;
BA_ "SPN" SG_ 2561212031 TextDisplayCharacter 3615;
BA_ "SigType" SG_ 2561212031 TextDisplayCharacter 1.7E-308;
BA_ "SPN" SG_ 2561212031 TextDisplayIndex 3614;
BA_ "SigType" SG_ 2561212031 TextDisplayIndex 1.7E-308;
BA_ "SPN" SG_ 2566844160 FuelDeliveryPressure 94;
BA_ "SigType" SG_ 2566844160 FuelDeliveryPressure 1.7E-308;
BA_ "SPN" SG_ 2566844160 EngineOilLevel 98;
BA_ "SigType" SG_ 2566844160 EngineOilLevel 1.7E-308;
BA_ "SPN" SG_ 2566844160 EngineOilPressure 100;
BA_ "SigType" SG_ 2566844160 EngineOilPressure 1.7E-308;
BA_ "SPN" SG_ 2566844160 EngineCrankcasePressure 101;
BA_ "SigType" SG_ 2566844160 EngineCrankcasePressure 1.7E-308;
BA_ "SPN" SG_ 2566844160 EngineCoolantPressure 109;
BA_ "SigType" SG_ 2566844160 EngineCoolantPressure 1.7E-308;
BA_ "SPN" SG_ 2566844160 EngineCoolantLevel 111;
BA_ "SigType" SG_ 2566844160 EngineCoolantLevel 1.7E-308;
BA_ "SPN" SG_ 2566844160 ExtCrankcaseBlowByPressure 22;
BA_ "SigType" SG_ 2566844160 ExtCrankcaseBlowByPressure 1.7E-308;
BA_ "SPN" SG_ 2432658432 pOperatorButton42 520468;
BA_ "SPN" SG_ 2432658432 pOperatorButton41 520467;
BA_ "SPN" SG_ 2432658432 pOperatorButton39 524071;
BA_ "SPN" SG_ 2432658432 pOperatorButton37 524069;
BA_ "SPN" SG_ 2432658432 pOperatorButton36 524068;
BA_ "SPN" SG_ 2432658432 pFOCCMessageCounter 524082;
BA_ "SPN" SG_ 2432658432 pFOCCChecksum 524081;
BA_ "SPN" SG_ 2432658432 pOperatorButton40 524072;
BA_ "SPN" SG_ 2432658432 pOperatorButton38 524070;
BA_ "SPN" SG_ 2432658432 pOperatorButton35 524066;
BA_ "SPN" SG_ 2432658432 pOperatorButton34 524065;
BA_ "SPN" SG_ 2432658432 pOperatorButton33 524064;
BA_ "SPN" SG_ 2432658432 pOperatorButton32 524063;
BA_ "SPN" SG_ 2432658432 pOperatorButton31 524062;
BA_ "SPN" SG_ 2432658432 pOperatorButton30 524061;
BA_ "SPN" SG_ 2432658432 pOperatorButton29 524060;
BA_ "SPN" SG_ 2633984512 pHeatedGripEnable 520366;
BA_ "SPN" SG_ 2633984512 pSideStandStatus 524098;
BA_ "SigType" SG_ 2633984512 pSideStandStatus 1.7E-308;
BA_ "SPN" SG_ 2633984512 pTetherSwitchStatus 520600;
BA_ "SPN" SG_ 2633984512 pLowFuelIndicatorStatus 524087;
BA_ "SPN" SG_ 2633984512 pOperatorNotInOperatingStation 2832;
BA_ "SPN" SG_ 2633984512 pParkBrakeIndicatorStatus 524271;
BA_ "SPN" SG_ 2633984512 pADCRequested 524139;
BA_ "SPN" SG_ 2633984512 pAWDModeRequested 524138;
BA_ "SPN" SG_ 2633984512 pRWDModeRequested 524137;
BA_ "SPN" SG_ 2633984512 pTurfModeRequested 524136;
BA_ "SPN" SG_ 2633984512 pADCStatus 524013;
BA_ "SigType" SG_ 2633984512 pADCStatus 1.7E-308;
BA_ "SPN" SG_ 2633984512 pTreadleNeutralStatus 524017;
BA_ "SigType" SG_ 2633984512 pTreadleNeutralStatus 1.7E-308;
BA_ "SPN" SG_ 2633984512 pTreadleReverseStatus 524018;
BA_ "SigType" SG_ 2633984512 pTreadleReverseStatus 1.7E-308;
BA_ "SPN" SG_ 2633984512 pSecurityLightStatus 524019;
BA_ "SigType" SG_ 2633984512 pSecurityLightStatus 1.7E-308;
BA_ "SPN" SG_ 2633984512 pHighBeamIndicatorStatus 524084;
BA_ "SigType" SG_ 2633984512 pHighBeamIndicatorStatus 1.7E-308;
BA_ "SPN" SG_ 2633984512 pHeatedGripsPercentage 524096;
BA_ "SigType" SG_ 2633984512 pHeatedGripsPercentage 1.7E-308;
BA_ "SPN" SG_ 2633984512 pCruiseControlSetStatus 524097;
BA_ "SigType" SG_ 2633984512 pCruiseControlSetStatus 1.7E-308;
BA_ "SPN" SG_ 2633984512 pSeatBeltIndicatorStatus 524092;
BA_ "SigType" SG_ 2633984512 pSeatBeltIndicatorStatus 1.7E-308;
BA_ "SPN" SG_ 2566847511 WasherFluidLevel 80;
BA_ "SigType" SG_ 2566847511 WasherFluidLevel 1.7E-308;
BA_ "SPN" SG_ 2566847511 FuelLevel 96;
BA_ "SigType" SG_ 2566847511 FuelLevel 1.7E-308;
BA_ "SPN" SG_ 2566847511 FuelFilterDiffPressure 95;
BA_ "SigType" SG_ 2566847511 FuelFilterDiffPressure 1.7E-308;
BA_ "SPN" SG_ 2566847511 EngineOilFilterDiffPressure 99;
BA_ "SigType" SG_ 2566847511 EngineOilFilterDiffPressure 1.7E-308;
BA_ "SPN" SG_ 2566847511 CargoAmbientTemperature 169;
BA_ "SigType" SG_ 2566847511 CargoAmbientTemperature 1.7E-308;
BA_ "SPN" SG_ 2566845719 DL_BarometricPressure 108;
BA_ "SigType" SG_ 2566845719 DL_BarometricPressure 1.7E-308;
BA_ "SPN" SG_ 2566845719 CabInteriorTemperature 170;
BA_ "SigType" SG_ 2566845719 CabInteriorTemperature 1.7E-308;
BA_ "SPN" SG_ 2566845719 AmbientAirTemperature 171;
BA_ "SigType" SG_ 2566845719 AmbientAirTemperature 1.7E-308;
BA_ "SPN" SG_ 2566845719 EngineAirInletTemperature 172;
BA_ "SigType" SG_ 2566845719 EngineAirInletTemperature 1.7E-308;
BA_ "SPN" SG_ 2566845719 RoadSurfaceTemperature 79;
BA_ "SigType" SG_ 2566845719 RoadSurfaceTemperature 1.7E-308;
BA_ "SPN" SG_ 2566847488 WasherFluidLevel 80;
BA_ "SigType" SG_ 2566847488 WasherFluidLevel 1.7E-308;
BA_ "SPN" SG_ 2566847488 FuelLevel 96;
BA_ "SigType" SG_ 2566847488 FuelLevel 1.7E-308;
BA_ "SPN" SG_ 2566847488 FuelFilterDiffPressure 95;
BA_ "SigType" SG_ 2566847488 FuelFilterDiffPressure 1.7E-308;
BA_ "SPN" SG_ 2566847488 EngineOilFilterDiffPressure 99;
BA_ "SigType" SG_ 2566847488 EngineOilFilterDiffPressure 1.7E-308;
BA_ "SPN" SG_ 2566847488 CargoAmbientTemperature 169;
BA_ "SigType" SG_ 2566847488 CargoAmbientTemperature 1.7E-308;
BA_ "SPN" SG_ 2565867008 Location 927;
BA_ "SigType" SG_ 2565867008 Location 1.7E-308;
BA_ "SPN" SG_ 2565867008 DifferentialLockFrontAxle1 567;
BA_ "SigType" SG_ 2565867008 DifferentialLockFrontAxle1 1.7E-308;
BA_ "SPN" SG_ 2565867008 DifferentialLockFrontAxle2 568;
BA_ "SigType" SG_ 2565867008 DifferentialLockFrontAxle2 1.7E-308;
BA_ "SPN" SG_ 2565867008 DifferentialLockRearAxle1 569;
BA_ "SigType" SG_ 2565867008 DifferentialLockRearAxle1 1.7E-308;
BA_ "SPN" SG_ 2565867008 DifferentialLockRearAxle2 570;
BA_ "SigType" SG_ 2565867008 DifferentialLockRearAxle2 1.7E-308;
BA_ "SPN" SG_ 2565867008 DifferentialCentral 564;
BA_ "SigType" SG_ 2565867008 DifferentialCentral 1.7E-308;
BA_ "SPN" SG_ 2565867008 DifferentialCentralFront 565;
BA_ "SigType" SG_ 2565867008 DifferentialCentralFront 1.7E-308;
BA_ "SPN" SG_ 2565867008 DifferentialCentralRear 566;
BA_ "SigType" SG_ 2565867008 DifferentialCentralRear 1.7E-308;
BA_ "SPN" SG_ 2566841600 EngTotalHoursOfOper 247;
BA_ "SigType" SG_ 2566841600 EngTotalHoursOfOper 1.7E-308;
BA_ "SPN" SG_ 2566841600 TotalEngineRevolutions 249;
BA_ "SigType" SG_ 2566841600 TotalEngineRevolutions 1.7E-308;
BA_ "SPN" SG_ 2566832407 HighResolTotalVehicleDistance 917;
BA_ "SigType" SG_ 2566832407 HighResolTotalVehicleDistance 1.7E-308;
BA_ "SPN" SG_ 2566832407 HighResolTripDistance 918;
BA_ "SigType" SG_ 2566832407 HighResolTripDistance 1.7E-308;
BA_ "SPN" SG_ 2566834688 DM_ProtectLampStatus 987;
BA_ "SigType" SG_ 2566834688 DM_ProtectLampStatus 1.7E-308;
BA_ "SPN" SG_ 2566834688 DM_RedStopLampState 623;
BA_ "SigType" SG_ 2566834688 DM_RedStopLampState 1.7E-308;
BA_ "SPN" SG_ 2566834688 DM_AmberWrningLmpStatus 624;
BA_ "SigType" SG_ 2566834688 DM_AmberWrningLmpStatus 1.7E-308;
BA_ "SPN" SG_ 2566834688 DM_MalfuncnIndicatorLampStatus 1213;
BA_ "SigType" SG_ 2566834688 DM_MalfuncnIndicatorLampStatus 1.7E-308;
BA_ "SPN" SG_ 2566834688 DM_FlashRedStopLamp 3039;
BA_ "SPN" SG_ 2566834688 DM_FlashMalfuncIndicatorLamp 3038;
BA_ "SigType" SG_ 2566834688 DTC5 7;
BA_ "SigType" SG_ 2566834688 DTC4 7;
BA_ "SigType" SG_ 2566834688 DTC3 7;
BA_ "SigType" SG_ 2566834688 DTC2 7;
BA_ "SigType" SG_ 2566834688 DTC1 7;
BA_ "SPN" SG_ 2566834688 DM_FlashProtectLamp 3041;
BA_ "SPN" SG_ 2566834688 DM_FlashAmberWarningLamp 3040;
BA_ "SPN" SG_ 2564423168 DM_NumberRequested 1640;
BA_ "SigType" SG_ 2564423168 DM_NumberRequested 1.7E-308;
BA_ "SPN" SG_ 2564423168 DM_PointerType 1641;
BA_ "SigType" SG_ 2564423168 DM_PointerType 1.7E-308;
BA_ "SPN" SG_ 2564423168 DM_Command 1642;
BA_ "SigType" SG_ 2564423168 DM_Command 1.7E-308;
BA_ "SPN" SG_ 2564423168 DM_Pointer 1644;
BA_ "SigType" SG_ 2564423168 DM_Pointer 1.7E-308;
BA_ "SPN" SG_ 2564423168 DM_PointerExtension 1643;
BA_ "SigType" SG_ 2564423168 DM_PointerExtension 1.7E-308;
BA_ "SPN" SG_ 2564423168 DM_UserLevel 1645;
BA_ "SigType" SG_ 2564423168 DM_UserLevel 1.7E-308;
BA_ "GenSigStartValue" SG_ 2564356352 DM15_SAE_Reserved2 1;
BA_ "GenSigStartValue" SG_ 2564356352 DM15_SAE_Reserved 1;
BA_ "SPN" SG_ 2633883392 FrtWheelDriveActuatorStatus 2612;
BA_ "SigType" SG_ 2633883392 FrtWheelDriveActuatorStatus 1.7E-308;
BA_ "SPN" SG_ 2432656640 pOperatorButton29 524060;
BA_ "SPN" SG_ 2432656640 pOperatorButton1 524059;
BA_ "SigType" SG_ 2432656640 pOperatorButton1 1.7E-308;
BA_ "SPN" SG_ 2432656640 pOperatorButton2 524058;
BA_ "SigType" SG_ 2432656640 pOperatorButton2 1.7E-308;
BA_ "SPN" SG_ 2432656640 pOperatorButton3 524057;
BA_ "SigType" SG_ 2432656640 pOperatorButton3 1.7E-308;
BA_ "SPN" SG_ 2432656640 pOperatorButton4 524056;
BA_ "SigType" SG_ 2432656640 pOperatorButton4 1.7E-308;
BA_ "SPN" SG_ 2432656640 pOperatorButton5 524055;
BA_ "SigType" SG_ 2432656640 pOperatorButton5 1.7E-308;
BA_ "SPN" SG_ 2432656640 pOperatorButton6 524054;
BA_ "SigType" SG_ 2432656640 pOperatorButton6 1.7E-308;
BA_ "SPN" SG_ 2432656640 pOperatorButton7 524053;
BA_ "SigType" SG_ 2432656640 pOperatorButton7 1.7E-308;
BA_ "SPN" SG_ 2432656640 pOperatorButton8 524052;
BA_ "SigType" SG_ 2432656640 pOperatorButton8 1.7E-308;
BA_ "SPN" SG_ 2432656640 pOperatorButton9 524051;
BA_ "SigType" SG_ 2432656640 pOperatorButton9 1.7E-308;
BA_ "SPN" SG_ 2432656640 pOperatorButton10 524050;
BA_ "SigType" SG_ 2432656640 pOperatorButton10 1.7E-308;
BA_ "SPN" SG_ 2432656640 pOperatorButton11 524049;
BA_ "SigType" SG_ 2432656640 pOperatorButton11 1.7E-308;
BA_ "SPN" SG_ 2432656640 pOperatorButton12 524048;
BA_ "SigType" SG_ 2432656640 pOperatorButton12 1.7E-308;
BA_ "SPN" SG_ 2432656640 pOperatorButton13 524047;
BA_ "SigType" SG_ 2432656640 pOperatorButton13 1.7E-308;
BA_ "SPN" SG_ 2432656640 pOperatorButton14 524046;
BA_ "SigType" SG_ 2432656640 pOperatorButton14 1.7E-308;
BA_ "SPN" SG_ 2432656640 pOperatorButton15 524045;
BA_ "SigType" SG_ 2432656640 pOperatorButton15 1.7E-308;
BA_ "SPN" SG_ 2432656640 pOperatorButton16 524044;
BA_ "SigType" SG_ 2432656640 pOperatorButton16 1.7E-308;
BA_ "SPN" SG_ 2432656640 pOperatorButton17 524043;
BA_ "SigType" SG_ 2432656640 pOperatorButton17 1.7E-308;
BA_ "SPN" SG_ 2432656640 pOperatorButton18 524042;
BA_ "SigType" SG_ 2432656640 pOperatorButton18 1.7E-308;
BA_ "SPN" SG_ 2432656640 pOperatorButton19 524041;
BA_ "SigType" SG_ 2432656640 pOperatorButton19 1.7E-308;
BA_ "SPN" SG_ 2432656640 pOperatorButton20 524040;
BA_ "SigType" SG_ 2432656640 pOperatorButton20 1.7E-308;
BA_ "SPN" SG_ 2432656640 pOperatorButton21 524039;
BA_ "SigType" SG_ 2432656640 pOperatorButton21 1.7E-308;
BA_ "SPN" SG_ 2432656640 pOperatorButton22 524038;
BA_ "SigType" SG_ 2432656640 pOperatorButton22 1.7E-308;
BA_ "SPN" SG_ 2432656640 pOperatorButton23 524037;
BA_ "SigType" SG_ 2432656640 pOperatorButton23 1.7E-308;
BA_ "SPN" SG_ 2432656640 pOperatorButton24 524036;
BA_ "SigType" SG_ 2432656640 pOperatorButton24 1.7E-308;
BA_ "SPN" SG_ 2432656640 pOperatorButton25 524035;
BA_ "SigType" SG_ 2432656640 pOperatorButton25 1.7E-308;
BA_ "SPN" SG_ 2432656640 pOperatorButton26 524034;
BA_ "SigType" SG_ 2432656640 pOperatorButton26 1.7E-308;
BA_ "SPN" SG_ 2432656640 pOperatorButton27 520322;
BA_ "SigType" SG_ 2432656640 pOperatorButton27 1.7E-308;
BA_ "SPN" SG_ 2432656640 pOperatorButton28 524032;
BA_ "SigType" SG_ 2432656640 pOperatorButton28 1.7E-308;
BA_ "SPN" SG_ 2432656640 pSideStandStatus 524098;
BA_ "SigType" SG_ 2432656640 pSideStandStatus 1.7E-308;
BA_ "SPN" SG_ 2365548032 pHighIdleState 524078;
BA_ "SPN" SG_ 2365548032 pEngineSpeed 524000;
BA_ "SigType" SG_ 2365548032 pEngineSpeed 1.7E-308;
BA_ "SPN" SG_ 2365548032 pStuckThrottle 524001;
BA_ "SigType" SG_ 2365548032 pStuckThrottle 1.7E-308;
BA_ "SPN" SG_ 2365548032 pFuelRange 524088;
BA_ "SigType" SG_ 2365548032 pFuelRange 1.7E-308;
BA_ "SigType" SG_ 2566913792 DL1_EngineThrottlePosition 1.7E-308;
BA_ "SigType" SG_ 2566913792 DL1_EngineSpeed 1.7E-308;
BA_ "SigType" SG_ 2566913792 DL1_EngineCoolantTemperature 1.7E-308;
BA_ "SigType" SG_ 2566913792 DL1_EngIntakeManifoldPressure 1.7E-308;
BA_ "SigType" SG_ 2566913792 DL1_EngineAirInletTemperature 1.7E-308;
BA_ "SigType" SG_ 2566913792 DL1_BatteryPotential 1.7E-308;
BA_ "SigType" SG_ 2566913536 DL2_EngineThrottlePosition 1.7E-308;
BA_ "SigType" SG_ 2566913536 DL2_EngineCoolantTemperature 1.7E-308;
BA_ "SigType" SG_ 2566913536 DL2_EngineAirInletTemperature 1.7E-308;
BA_ "SigType" SG_ 2566913536 DL2_EngIntakeManifoldPressure 1.7E-308;
BA_ "SigType" SG_ 2566913536 DL2_Boost 1.7E-308;
BA_ "SigType" SG_ 2566913536 DL2_BarometricPressure 1.7E-308;
BA_ "SigType" SG_ 2566913536 DL2_Wheel_BasedVehicleSpeed 1.7E-308;
BA_ "SigType" SG_ 2566913536 DL2_BarometricPressure_Volts 1.7E-308;
BA_ "SigType" SG_ 2566913280 DL3_IdleAirCntrlPosition 1.7E-308;
BA_ "SigType" SG_ 2566913280 DL3_DesiredIACPosition 1.7E-308;
BA_ "SigType" SG_ 2566913280 DL3_IdleAirSolenoidDC 1.7E-308;
BA_ "SigType" SG_ 2566913280 DL3_EnginePercentLoad 1.7E-308;
BA_ "SigType" SG_ 2566913280 DL3_IdleTargetRPM 1.7E-308;
BA_ "SigType" SG_ 2566913280 DL3_AbsThrottlePercent 1.7E-308;
BA_ "SigType" SG_ 2566913280 DL3_EngineThrottlePositionHR 1.7E-308;
BA_ "SigType" SG_ 2566911744 DL9_KnockRetardCyl1 1.7E-308;
BA_ "SigType" SG_ 2566911744 DL9_KnockRetardCyl2 1.7E-308;
BA_ "SigType" SG_ 2566911744 DL9_InjDETCorrMAG 1.7E-308;
BA_ "SigType" SG_ 2566911744 DL9_InjDETCorrPTO 1.7E-308;
BA_ "SigType" SG_ 2566911744 DL9_DetonationFreqCyl1 1.7E-308;
BA_ "SigType" SG_ 2566911744 DL9_DetonationFreqCyl2 1.7E-308;
BA_ "SigType" SG_ 2566911744 DL9_IgnitIonVarianceDeg 1.7E-308;
BA_ "SigType" SG_ 2566911744 DL9_FuelVariance 1.7E-308;
BA_ "SigType" SG_ 2566911488 DL10_PurgeValveSolenoidOut 1.7E-308;
BA_ "SigType" SG_ 2566909952 DL11_EngRunTime 1.7E-308;
BA_ "SigType" SG_ 2566909952 DL11_EngRunTimeKeyOn 1.7E-308;
BA_ "SigType" SG_ 2566909696 DL12_LambdaVoltBank2 1.7E-308;
BA_ "SigType" SG_ 2566909696 DL12_ActualLambdaBank2 1.7E-308;
BA_ "SigType" SG_ 2566909696 DL12_DesiredLambdaBank2 1.7E-308;
BA_ "SigType" SG_ 2566909696 DL12_MixAdaptationHiLoadBank2 1.7E-308;
BA_ "SigType" SG_ 2566909696 DL12_MixAdaptationLoLoadBank2 1.7E-308;
BA_ "SigType" SG_ 2566909696 DL12_ClosedLoopAdjFactor2 1.7E-308;
BA_ "SigType" SG_ 2566909696 DL12_LambaSensorHeaterOutBank2 1.7E-308;
BA_ "SigType" SG_ 2566909696 DL12_AirFuelMixStatusBank2 1.7E-308;
BA_ "SigType" SG_ 2566909696 DL12_ClosedLoopMixControlBank2 1.7E-308;
BA_ "SigType" SG_ 2566909440 DL13_PortInjector1Time 1.7E-308;
BA_ "SigType" SG_ 2566909440 DL13_CaseInjector1Time 1.7E-308;
BA_ "SigType" SG_ 2566909440 DL13_Cyl1IgnTiming 1.7E-308;
BA_ "SigType" SG_ 2566909440 DL13_Cyl1BaseIgnTiming 1.7E-308;
BA_ "SigType" SG_ 2566909440 DL13_Cyl1IgnCoilDwell 1.7E-308;
BA_ "SigType" SG_ 2566909184 DL14_PortInjector2Time 1.7E-308;
BA_ "SigType" SG_ 2566909184 DL14_CaseInjector2Time 1.7E-308;
BA_ "SigType" SG_ 2566909184 DL14_Cyl2IgnTiming 1.7E-308;
BA_ "SigType" SG_ 2566909184 DL14_Cyl2BaseIgnTiming 1.7E-308;
BA_ "SigType" SG_ 2566909184 DL14_Cyl2IgnCoilDwell 1.7E-308;
BA_ "SigType" SG_ 2566908928 DL15_ExhaustTemperature 1.7E-308;
BA_ "SigType" SG_ 2566908928 DL15_InjectorIgnitionSupplyVolt 1.7E-308;
BA_ "SigType" SG_ 2566908928 DL15_ElecStartOptBattVolt 1.7E-308;
BA_ "SigType" SG_ 2566908672 DL16_PedalPosSensor1 1.7E-308;
BA_ "SigType" SG_ 2566908672 DL16_PedalPosSensor2 1.7E-308;
BA_ "SigType" SG_ 2566913024 DL4_FuelInjector1PulseWidth 1.7E-308;
BA_ "SigType" SG_ 2566913024 DL4_IgnCoil1Dwell 1.7E-308;
BA_ "SigType" SG_ 2566913024 DL4_Cyl1IgnTiming 1.7E-308;
BA_ "SigType" SG_ 2566913024 DL4_Cyl1AirInjDuration 1.7E-308;
BA_ "SigType" SG_ 2566913024 DL4_FuelInjector2PulseWidth 1.7E-308;
BA_ "SigType" SG_ 2566913024 DL4_IgnCoil2Dwell 1.7E-308;
BA_ "SigType" SG_ 2566913024 DL4_Cyl2IgnTiming 1.7E-308;
BA_ "SigType" SG_ 2566913024 DL4_Cyl2AirInjDuration 1.7E-308;
BA_ "SigType" SG_ 2566912768 DL5_FuelInjector3PulseWidth 1.7E-308;
BA_ "SigType" SG_ 2566912768 DL5_IgnCoil3Dwell 1.7E-308;
BA_ "SigType" SG_ 2566912768 DL5_Cyl3IgnTiming 1.7E-308;
BA_ "SigType" SG_ 2566912768 DL5_Cyl3AirInjDuration 1.7E-308;
BA_ "SigType" SG_ 2566912768 DL5_FuelInjector4PulseWidth 1.7E-308;
BA_ "SigType" SG_ 2566912768 DL5_IgnCoil4Dwell 1.7E-308;
BA_ "SigType" SG_ 2566912768 DL5_Cyl4IgnTiming 1.7E-308;
BA_ "SigType" SG_ 2566912768 DL5_Cyl4AirInjDuration 1.7E-308;
BA_ "SigType" SG_ 2566912512 DL6_GearVolts 1.7E-308;
BA_ "SigType" SG_ 2566912512 DL6_RolloverVolts 1.7E-308;
BA_ "SigType" SG_ 2566912512 DL6_ThrottleReleaseInputVolts 1.7E-308;
BA_ "SigType" SG_ 2566912512 DL6_FuelTypeSensorVolts 1.7E-308;
BA_ "SigType" SG_ 2566912256 DL7_EngineThrottlePosition2 1.7E-308;
BA_ "SigType" SG_ 2566912256 DL7_SensorSupplyVoltage1 1.7E-308;
BA_ "SigType" SG_ 2566912256 DL7_SensorSupplyVoltage2 1.7E-308;
BA_ "SigType" SG_ 2566912256 DL7_SensorSupplyVoltage3 1.7E-308;
BA_ "SigType" SG_ 2566912256 DL7_ECUOutSupplyVoltage1 1.7E-308;
BA_ "SigType" SG_ 2566912256 DL7_ECUOutSupplyVoltage2 1.7E-308;
BA_ "SigType" SG_ 2566912000 DL8_LambdaVoltBank1 1.7E-308;
BA_ "SigType" SG_ 2566912000 DL8_ActualLambdaBank1 1.7E-308;
BA_ "SigType" SG_ 2566912000 DL8_DesiredLambdaBank1 1.7E-308;
BA_ "SigType" SG_ 2566912000 DL8_MixAdaptationHiLoadBank1 1.7E-308;
BA_ "SigType" SG_ 2566912000 DL8_MixAdaptationLoLoadBank1 1.7E-308;
BA_ "SigType" SG_ 2566912000 DL8_ClosedLoopAdjFactor1 1.7E-308;
BA_ "SigType" SG_ 2566912000 DL8_LambaSensorHeaterOutBank1 1.7E-308;
BA_ "SigType" SG_ 2566912000 DL8_AirFuelMixStatusBank1 1.7E-308;
BA_ "SigType" SG_ 2566912000 DL8_ClosedLoopMixControlBank1 1.7E-308;
BA_ "SigType" SG_ 2566911232 FI1_FuelPumpDriverCkt 1.7E-308;
BA_ "SigType" SG_ 2566911232 FI1_RolloverSwitch 1.7E-308;
BA_ "SigType" SG_ 2566911232 FI1_CrankSensorSignal 1.7E-308;
BA_ "SigType" SG_ 2566911232 FI1_CamSensorSignal 1.7E-308;
BA_ "SigType" SG_ 2566911232 FI1_RPMLimitActive 1.7E-308;
BA_ "SigType" SG_ 2566911232 FI1_IdleSwitch 1.7E-308;
BA_ "SigType" SG_ 2566911232 FI1_CycleSynchro 1.7E-308;
BA_ "SigType" SG_ 2566911232 FI1_IdleSpeedControlStatus 1.7E-308;
BA_ "SigType" SG_ 2566911232 FI1_IgnitionSwitchInput 1.7E-308;
BA_ "SigType" SG_ 2566911232 FI1_RunStopSwitchInput 1.7E-308;
BA_ "SigType" SG_ 2566911232 FI1_StartSwitchInput 1.7E-308;
BA_ "SigType" SG_ 2566911232 FI1_ThrottleSafetySwInput 1.7E-308;
BA_ "SigType" SG_ 2566911232 FI1_FanRelayOutput 1.7E-308;
BA_ "SigType" SG_ 2566911232 FI1_IntercoolerFanOutput 1.7E-308;
BA_ "SigType" SG_ 2566911232 FI1_ReverseAlarmOutput 1.7E-308;
BA_ "SigType" SG_ 2566911232 FI1_MainRelayOutput 1.7E-308;
BA_ "SigType" SG_ 2566911232 FI1_StartSolenoidOutput 1.7E-308;
BA_ "SigType" SG_ 2566911232 FI1_IgnitionRelayOutput 1.7E-308;
BA_ "SigType" SG_ 2566911232 FI1_ChassisRelayOutput 1.7E-308;
BA_ "SigType" SG_ 2566911232 FI1_StarterEnableOutput 1.7E-308;
BA_ "SigType" SG_ 2566911232 FI1_ExhaustValveOutput 1.7E-308;
BA_ "SigType" SG_ 2566911232 FI1_BatteryChargeRelayOutput 1.7E-308;
BA_ "SigType" SG_ 2566911232 FI1_HeaterAccRelay 1.7E-308;
BA_ "SigType" SG_ 2566911232 FI1_ClutchSwitchInput 1.7E-308;
BA_ "SigType" SG_ 2566911232 FI1_MILLampOutput 1.7E-308;
BA_ "SigType" SG_ 2566911232 FI1_OverTempLampOutput 1.7E-308;
BA_ "SigType" SG_ 2566911232 FI1_KnockDetLampOutput 1.7E-308;
BA_ "SigType" SG_ 2566911232 FI1_ElecOilPumpDrvrCirc 1.7E-308;
BA_ "SigType" SG_ 2566910976 FI2_ADCOutput 1.7E-308;
BA_ "SigType" SG_ 2566910976 FI2_RearDiffLockOutput 1.7E-308;
BA_ "SigType" SG_ 2566910976 FI2_AWDOutput 1.7E-308;
BA_ "SigType" SG_ 2566910976 FI2_BrakeSwitchInput 1.7E-308;
BA_ "SigType" SG_ 2566910976 FI2_ADCSwitchInput 1.7E-308;
BA_ "SigType" SG_ 2566910976 FI2_TurfModeInput 1.7E-308;
BA_ "SigType" SG_ 2566910976 FI2_AWDSwitchInput 1.7E-308;
BA_ "SigType" SG_ 2566910976 FI2_ReverseSwitchInput 1.7E-308;
BA_ "SigType" SG_ 2566910976 FI2_ReverseLimitSwitchInput 1.7E-308;
BA_ "SigType" SG_ 2566910976 FI2_ForwardLimitSwitchInput 1.7E-308;
BA_ "SigType" SG_ 2566910976 FI2_EngineDirection 1.7E-308;
BA_ "SigType" SG_ 2566910976 FI2_RevSpeedLimitOverrideInput 1.7E-308;
BA_ "SigType" SG_ 2566910976 FI2_ReverseOverspeedSignal 1.7E-308;
BA_ "SigType" SG_ 2566910976 FI2_RightTurnSignalInput 1.7E-308;
BA_ "SigType" SG_ 2566910976 FI2_LeftTurnSignalInput 1.7E-308;
BA_ "SigType" SG_ 2566910976 FI2_KickstandSwitchInput 1.7E-308;
BA_ "SigType" SG_ 2566910976 FI2_ReflashEnableInputSignal 1.7E-308;
BA_ "SigType" SG_ 2566910976 FI2_TPSLearnInputSignal 1.7E-308;
BA_ "SigType" SG_ 2566910976 FI2_LowRangeSwitchInput 1.7E-308;
BA_ "SigType" SG_ 2566910976 FI2_ReverseMotorDriveInput 1.7E-308;
BA_ "SigType" SG_ 2566910208 FI5_b10Sec 1.7E-308;
BA_ "SigType" SG_ 2566910208 FI5_bBatt 1.7E-308;
BA_ "SigType" SG_ 2566910208 FI5_bEnable 1.7E-308;
BA_ "SigType" SG_ 2566910208 FI5_bLazyCRC 1.7E-308;
BA_ "SigType" SG_ 2566910208 FI5_bManCyc 1.7E-308;
BA_ "SigType" SG_ 2566910208 FI5_bNotRun 1.7E-308;
BA_ "SigType" SG_ 2566910208 FI5_bOper 1.7E-308;
BA_ "SigType" SG_ 2566908160 DL18_DesiredTorqueChg 1.7E-308;
BA_ "SigType" SG_ 2566908160 DL18_ThrottleAngleCorrFactor 1.7E-308;
BA_ "SigType" SG_ 2566908160 DL18_DragTorqueAdapt 1.7E-308;
BA_ "SPN" SG_ 2633984768 pADCModeAvailability 524143;
BA_ "SPN" SG_ 2633984768 pAWDModeAvailability 524142;
BA_ "SPN" SG_ 2633984768 pTurfModeAvailability 524140;
BA_ "SPN" SG_ 2633984768 pDisplayedSpeedCorrectionFactor 524014;
BA_ "SigType" SG_ 2633984768 pDisplayedSpeedCorrectionFactor 1.7E-308;
BA_ "SPN" SG_ 2633984768 pInstrumentBacklightIntensity 524015;
BA_ "SigType" SG_ 2633984768 pInstrumentBacklightIntensity 1.7E-308;
BA_ "SPN" SG_ 2633984768 pWarningLampIntensity 524016;
BA_ "SigType" SG_ 2633984768 pWarningLampIntensity 1.7E-308;
BA_ "SPN" SG_ 2633984768 pFuelTankVolume 524089;
BA_ "SigType" SG_ 2633984768 pFuelTankVolume 1.7E-308;
BA_ "SPN" SG_ 2633984768 pLowFuelLightONPercentage 524090;
BA_ "SigType" SG_ 2633984768 pLowFuelLightONPercentage 1.7E-308;
BA_ "SPN" SG_ 2633984768 pFuelLevelDataSource 524091;
BA_ "SigType" SG_ 2633984768 pFuelLevelDataSource 1.7E-308;
BA_ "SPN" SG_ 2633984768 pVehicleUnitsConfig 524093;
BA_ "SigType" SG_ 2633984768 pVehicleUnitsConfig 1.7E-308;
BA_ "SPN" SG_ 2633984768 pFuelEconomyDataSource 524094;
BA_ "SigType" SG_ 2633984768 pFuelEconomyDataSource 1.7E-308;
BA_ "SPN" SG_ 2633984768 pSeatBeltInputSource 524095;
BA_ "SigType" SG_ 2633984768 pSeatBeltInputSource 1.7E-308;
BA_ "SigType" SG_ 2566902272 DL_InjectorBankAPulseWidth 1.7E-308;
BA_ "SigType" SG_ 2566902272 DL_InjectorBankBPulseWidth 1.7E-308;
BA_ "SigType" SG_ 2566902272 DL_FuelConsumptionRate 1.7E-308;
BA_ "SigType" SG_ 2566902272 DL_FuelSelectInput 1.7E-308;
BA_ "SigType" SG_ 2566910720 FI3_DriveMode1Input 1.7E-308;
BA_ "SigType" SG_ 2566910720 FI3_DriveMode2Input 1.7E-308;
BA_ "SigType" SG_ 2566910720 FI3_DriveMode3Input 1.7E-308;
BA_ "SigType" SG_ 2566910720 FI3_DriverMode4Input 1.7E-308;
BA_ "SigType" SG_ 2566910720 FI3_DriverMode1Output 1.7E-308;
BA_ "SigType" SG_ 2566910720 FI3_DriverMode2Output 1.7E-308;
BA_ "SigType" SG_ 2566910720 FI3_DriverMode3Output 1.7E-308;
BA_ "SigType" SG_ 2566910720 FI3_DriverMode4Ouput 1.7E-308;
BA_ "SigType" SG_ 2566910720 FI3_PTOModeInput 1.7E-308;
BA_ "SigType" SG_ 2566910720 FI3_PTOModeOutput 1.7E-308;
BA_ "SigType" SG_ 2566910720 FI3_DriversNetEngagement 1.7E-308;
BA_ "SigType" SG_ 2566910720 FI3_DriversSeatbeltEngagement 1.7E-308;
BA_ "SigType" SG_ 2566910720 FI3_TiltLockInput 1.7E-308;
BA_ "SigType" SG_ 2566910720 FI3_WorkGroupLockInput 1.7E-308;
BA_ "SigType" SG_ 2566910720 FI3_OperatorPresenceInput 1.7E-308;
BA_ "SigType" SG_ 2566910720 FI3_WorkGroupLockOutput 1.7E-308;
BA_ "SigType" SG_ 2566910720 FI3_OperatorPresenceOutput 1.7E-308;
BA_ "SigType" SG_ 2566910720 FI3_FootOnCruiseInput 1.7E-308;
BA_ "SigType" SG_ 2566910720 FI3_CruiseInput 1.7E-308;
BA_ "SigType" SG_ 2566910720 FI3_TredalInput 1.7E-308;
BA_ "SigType" SG_ 2566910720 FI3_CruiseSpeedInput 1.7E-308;
BA_ "SigType" SG_ 2566910720 FI3_FootOnCruiseOutput 1.7E-308;
BA_ "SigType" SG_ 2566910720 FI3_CruiseOutput 1.7E-308;
BA_ "SigType" SG_ 2566910720 FI3_CruiseControltoSetSpeed 1.7E-308;
BA_ "SigType" SG_ 2566910720 FI3_WorkModeInput 1.7E-308;
BA_ "SigType" SG_ 2566910720 FI3_TiltLockOutput 1.7E-308;
BA_ "SigType" SG_ 2566910464 FI4_BrakeLightOutput 1.7E-308;
BA_ "SigType" SG_ 2566910464 FI4_FogLightInput 1.7E-308;
BA_ "SigType" SG_ 2566910464 FI4_HazardLightOutput 1.7E-308;
BA_ "SigType" SG_ 2566910464 FI4_HazardSWInput 1.7E-308;
BA_ "SigType" SG_ 2566910464 FI4_HeatGripDecSW 1.7E-308;
BA_ "SigType" SG_ 2566910464 FI4_HeatGripIncSW 1.7E-308;
BA_ "SigType" SG_ 2566910464 FI4_HighBeamOutput 1.7E-308;
BA_ "SigType" SG_ 2566910464 FI4_HornInput 1.7E-308;
BA_ "SigType" SG_ 2566910464 FI4_HornOutput 1.7E-308;
BA_ "SigType" SG_ 2566910464 FI4_LeftFogLightOutput 1.7E-308;
BA_ "SigType" SG_ 2566910464 FI4_LFTurnSignalOutput 1.7E-308;
BA_ "SigType" SG_ 2566910464 FI4_LockInput 1.7E-308;
BA_ "SigType" SG_ 2566910464 FI4_LowBeamOutput 1.7E-308;
BA_ "SigType" SG_ 2566910464 FI4_LowHighBeamInput 1.7E-308;
BA_ "SigType" SG_ 2566910464 FI4_LRTurnSignalOutput 1.7E-308;
BA_ "SigType" SG_ 2566910464 FI4_pOperatorButton1 1.7E-308;
BA_ "SigType" SG_ 2566910464 FI4_RFTurnSignalOutput 1.7E-308;
BA_ "SigType" SG_ 2566910464 FI4_RightFogLightOutput 1.7E-308;
BA_ "SigType" SG_ 2566910464 FI4_RRTurnSignalOutput 1.7E-308;
BA_ "SigType" SG_ 2566910464 FI4_SecondaryAirValveCmd 1.7E-308;
BA_ "SigType" SG_ 2566910464 FI4_SecondaryAirValveOut 1.7E-308;
BA_ "SigType" SG_ 2566910464 FI4_TailLightOutput 1.7E-308;
BA_ "SigType" SG_ 2566910464 FI4_UnlockInput 1.7E-308;
BA_ "SigType" SG_ 2566910464 FI4_WindshieldSWDownInput 1.7E-308;
BA_ "SigType" SG_ 2566910464 FI4_WindshieldSWUpInput 1.7E-308;
BA_ "SigType" SG_ 2566910464 FI4_pOperatorButton2 1.7E-308;
BA_ "SigType" SG_ 2566907904 DL19_TirePressure_Rear_Left_Only 1.7E-308;
BA_ "SigType" SG_ 2566907904 DL19_TirePressureFront_Left_Only 1.7E-308;
BA_ "SigType" SG_ 2566907904 DL19_TirePressureFrontRight 1.7E-308;
BA_ "SigType" SG_ 2566907904 DL19_TirePressureRearRight 1.7E-308;
BA_ "SigType" SG_ 2566907648 DL20_KeyFobBatteryVoltage 1.7E-308;
BA_ "SigType" SG_ 2566907648 DL20_LeanAngle 1.7E-308;
BA_ "SPN" SG_ 2566847578 WasherFluidLevel 80;
BA_ "SigType" SG_ 2566847578 WasherFluidLevel 1.7E-308;
BA_ "SPN" SG_ 2566847578 FuelLevel 96;
BA_ "SigType" SG_ 2566847578 FuelLevel 1.7E-308;
BA_ "SPN" SG_ 2566847578 FuelFilterDiffPressure 95;
BA_ "SigType" SG_ 2566847578 FuelFilterDiffPressure 1.7E-308;
BA_ "SPN" SG_ 2566847578 EngineOilFilterDiffPressure 99;
BA_ "SigType" SG_ 2566847578 EngineOilFilterDiffPressure 1.7E-308;
BA_ "SPN" SG_ 2566847578 CargoAmbientTemperature 169;
BA_ "SigType" SG_ 2566847578 CargoAmbientTemperature 1.7E-308;
BA_ "SPN" SG_ 2566878604 pChecksum_524123 524123;
BA_ "SPN" SG_ 2566878604 pMessageCounter_524122 524122;
BA_ "SPN" SG_ 2566878604 pOperationMode 524120;
BA_ "SPN" SG_ 2566878604 pStartStopCmd 520497;
BA_ "SPN" SG_ 2566878604 pNorm_Acc_Pos_520354 520354;
BA_ "SPN" SG_ 2566878464 pStartStopCmd 520497;
BA_ "SPN" SG_ 2566878464 pPedalPositionCommand 524121;
BA_ "SPN" SG_ 2566878464 pOperationMode 524120;
BA_ "SPN" SG_ 2566876928 pSecondaryAirValveControl 524083;
BA_ "SPN" SG_ 2566853886 pRangeToEmptyEV 520529;
BA_ "SPN" SG_ 2566853886 pEfficiencyEV 520528;
BA_ "SPN" SG_ 2566876416 pDriveModeCommanded 524077;
BA_ "SPN" SG_ 2566876416 pFootOnCruiseControlEnabled 524073;
BA_ "SPN" SG_ 2566876416 pDriveModeRequested 524067;
BA_ "SPN" SG_ 2566825472 EngineTurbo1BoostPressure 1127;
BA_ "SPN" SG_ 2566804212 NetBattCurrentHiRange 2579;
BA_ "SPN" SG_ 2566804211 NetBattCurrentHiRange 2579;
BA_ "SPN" SG_ 2297441780 Vertical_Accel_Ext_Range 5349;
BA_ "SPN" SG_ 2297441780 Vertical_Accel_Ext_Merit 5352;
BA_ "SPN" SG_ 2297441780 Longitudinal_Accel_Ext_Range 5348;
BA_ "SPN" SG_ 2297441780 Longitudinal_Accel_Ext_Merit 5351;
BA_ "SPN" SG_ 2297441780 Lateral_Accel_Ext_Range 5347;
BA_ "SPN" SG_ 2297441780 Lateral_Accel_Ext_Merit 5350;
BA_ "SPN" SG_ 2297441780 Accel_Sensor_Support_Var 5353;
BA_ "SPN" SG_ 2566846452 Net_Battery_Current 114;
BA_ "SPN" SG_ 2566846452 BatteryPotential 168;
BA_ "SigType" SG_ 2566846452 BatteryPotential 1.7E-308;
BA_ "SPN" SG_ 2297441779 Vertical_Accel_Ext_Range 5349;
BA_ "SPN" SG_ 2297441779 Vertical_Accel_Ext_Merit 5352;
BA_ "SPN" SG_ 2297441779 Longitudinal_Accel_Ext_Range 5348;
BA_ "SPN" SG_ 2297441779 Longitudinal_Accel_Ext_Merit 5351;
BA_ "SPN" SG_ 2297441779 Lateral_Accel_Ext_Range 5347;
BA_ "SPN" SG_ 2297441779 Lateral_Accel_Ext_Merit 5350;
BA_ "SPN" SG_ 2297441779 Accel_Sensor_Support_Var 5353;
BA_ "SPN" SG_ 2566846451 Net_Battery_Current 114;
BA_ "SPN" SG_ 2566846451 BatteryPotential 168;
BA_ "SigType" SG_ 2566846451 BatteryPotential 1.7E-308;
BA_ "SPN" SG_ 2365525748 WATT_pPack_Voltage 524217;
BA_ "SPN" SG_ 2365525748 WATT_pPack_Current 524216;
BA_ "SPN" SG_ 2365525748 WATT_pDischarge_Limit 524218;
BA_ "SPN" SG_ 2365525748 WATT_pCharge_Limit 524219;
BA_ "SPN" SG_ 2365525748 WATT_pBMC_Pwr_Msg_Check_Seq 524252;
BA_ "SPN" SG_ 2365525747 WATT_pPack_Voltage 524217;
BA_ "SPN" SG_ 2365525747 WATT_pPack_Current 524216;
BA_ "SPN" SG_ 2365525747 WATT_pDischarge_Limit 524218;
BA_ "SPN" SG_ 2365525747 WATT_pCharge_Limit 524219;
BA_ "SPN" SG_ 2365525747 WATT_pBMC_Pwr_Msg_Check_Seq 524252;
BA_ "SPN" SG_ 2298415350 WATT_pSpeed_Lim_Cutback_Status 524258;
BA_ "SPN" SG_ 2298415350 WATT_pMotor_Therm_Cutback 524260;
BA_ "SPN" SG_ 2298415350 WATT_pMotor_Power_Cutback_Status 524240;
BA_ "SPN" SG_ 2298415350 WATT_pI_DC_Cutback_Status 524257;
BA_ "SPN" SG_ 2298415350 WATT_pController_Therm_Cutback 524259;
BA_ "SPN" SG_ 2298415350 WATT_pPower_Msg_Check_Seq 524250;
BA_ "SPN" SG_ 2298415350 WATT_pInput_Current 524195;
BA_ "SPN" SG_ 2298415350 WATT_pCapacitor_Voltage 524196;
BA_ "SPN" SG_ 2298415606 WATT_pTemperature_Msg_Check_Seq 524251;
BA_ "SPN" SG_ 2298415606 WATT_pMotor_Temp_Margin 524198;
BA_ "SPN" SG_ 2298415606 WATT_pMotor_Temp 524201;
BA_ "SPN" SG_ 2298415606 WATT_pJunction_Temp 524203;
BA_ "SPN" SG_ 2298415606 WATT_pController_Temp_Margin 524197;
BA_ "SPN" SG_ 2298415606 WATT_pCapacitor_Temp 524202;
BA_ "SPN" SG_ 2298415606 WATT_pBoard_Temp 524200;
BA_ "SPN" SG_ 2298415606 WATT_pBaseplate_Temp 524199;
BA_ "SPN" SG_ 2298415351 WATT_pSpeed_Lim_Cutback_Status 524258;
BA_ "SPN" SG_ 2298415351 WATT_pMotor_Therm_Cutback 524260;
BA_ "SPN" SG_ 2298415351 WATT_pMotor_Power_Cutback_Status 524240;
BA_ "SPN" SG_ 2298415351 WATT_pI_DC_Cutback_Status 524257;
BA_ "SPN" SG_ 2298415351 WATT_pController_Therm_Cutback 524259;
BA_ "SPN" SG_ 2298415351 WATT_pPower_Msg_Check_Seq 524250;
BA_ "SPN" SG_ 2298415351 WATT_pInput_Current 524195;
BA_ "SPN" SG_ 2298415351 WATT_pCapacitor_Voltage 524196;
BA_ "SPN" SG_ 2298415607 WATT_pTemperature_Msg_Check_Seq 524251;
BA_ "SPN" SG_ 2298415607 WATT_pMotor_Temp_Margin 524198;
BA_ "SPN" SG_ 2298415607 WATT_pMotor_Temp 524201;
BA_ "SPN" SG_ 2298415607 WATT_pJunction_Temp 524203;
BA_ "SPN" SG_ 2298415607 WATT_pController_Temp_Margin 524197;
BA_ "SPN" SG_ 2298415607 WATT_pCapacitor_Temp 524202;
BA_ "SPN" SG_ 2298415607 WATT_pBoard_Temp 524200;
BA_ "SPN" SG_ 2298415607 WATT_pBaseplate_Temp 524199;
BA_ "SPN" SG_ 2365523456 pModCtlMsg_Checksum 516097;
BA_ "SPN" SG_ 2365523456 pModCtlAppliedState 516096;
BA_ "SPN" SG_ 2365523456 pModCtlCmdDestAdd 524185;
BA_ "SPN" SG_ 2365523456 pModCtlCmdState 524248;
BA_ "SPN" SG_ 2298415346 WATT_pSpeed_Lim_Cutback_Status 524258;
BA_ "SPN" SG_ 2298415346 WATT_pMotor_Therm_Cutback 524260;
BA_ "SPN" SG_ 2298415346 WATT_pMotor_Power_Cutback_Status 524240;
BA_ "SPN" SG_ 2298415346 WATT_pI_DC_Cutback_Status 524257;
BA_ "SPN" SG_ 2298415346 WATT_pController_Therm_Cutback 524259;
BA_ "SPN" SG_ 2298415346 WATT_pPower_Msg_Check_Seq 524250;
BA_ "SPN" SG_ 2298415346 WATT_pInput_Current 524195;
BA_ "SPN" SG_ 2298415346 WATT_pCapacitor_Voltage 524196;
BA_ "SPN" SG_ 2298415602 WATT_pTemperature_Msg_Check_Seq 524251;
BA_ "SPN" SG_ 2298415602 WATT_pMotor_Temp_Margin 524198;
BA_ "SPN" SG_ 2298415602 WATT_pMotor_Temp 524201;
BA_ "SPN" SG_ 2298415602 WATT_pJunction_Temp 524203;
BA_ "SPN" SG_ 2298415602 WATT_pController_Temp_Margin 524197;
BA_ "SPN" SG_ 2298415602 WATT_pCapacitor_Temp 524202;
BA_ "SPN" SG_ 2298415602 WATT_pBoard_Temp 524200;
BA_ "SPN" SG_ 2298415602 WATT_pBaseplate_Temp 524199;
BA_ "SPN" SG_ 2298415345 WATT_pSpeed_Lim_Cutback_Status 524258;
BA_ "SPN" SG_ 2298415345 WATT_pMotor_Therm_Cutback 524260;
BA_ "SPN" SG_ 2298415345 WATT_pMotor_Power_Cutback_Status 524240;
BA_ "SPN" SG_ 2298415345 WATT_pI_DC_Cutback_Status 524257;
BA_ "SPN" SG_ 2298415345 WATT_pController_Therm_Cutback 524259;
BA_ "SPN" SG_ 2298415345 WATT_pPower_Msg_Check_Seq 524250;
BA_ "SPN" SG_ 2298415345 WATT_pInput_Current 524195;
BA_ "SPN" SG_ 2298415345 WATT_pCapacitor_Voltage 524196;
BA_ "SPN" SG_ 2298415601 WATT_pTemperature_Msg_Check_Seq 524251;
BA_ "SPN" SG_ 2298415601 WATT_pMotor_Temp_Margin 524198;
BA_ "SPN" SG_ 2298415601 WATT_pMotor_Temp 524201;
BA_ "SPN" SG_ 2298415601 WATT_pJunction_Temp 524203;
BA_ "SPN" SG_ 2298415601 WATT_pController_Temp_Margin 524197;
BA_ "SPN" SG_ 2298415601 WATT_pCapacitor_Temp 524202;
BA_ "SPN" SG_ 2298415601 WATT_pBoard_Temp 524200;
BA_ "SPN" SG_ 2298415601 WATT_pBaseplate_Temp 524199;
BA_ "SPN" SG_ 2298415344 WATT_pSpeed_Lim_Cutback_Status 524258;
BA_ "SPN" SG_ 2298415344 WATT_pMotor_Therm_Cutback 524260;
BA_ "SPN" SG_ 2298415344 WATT_pMotor_Power_Cutback_Status 524240;
BA_ "SPN" SG_ 2298415344 WATT_pI_DC_Cutback_Status 524257;
BA_ "SPN" SG_ 2298415344 WATT_pController_Therm_Cutback 524259;
BA_ "SPN" SG_ 2298415344 WATT_pPower_Msg_Check_Seq 524250;
BA_ "SPN" SG_ 2298415344 WATT_pInput_Current 524195;
BA_ "SPN" SG_ 2298415344 WATT_pCapacitor_Voltage 524196;
BA_ "SPN" SG_ 2298415600 WATT_pTemperature_Msg_Check_Seq 524251;
BA_ "SPN" SG_ 2298415600 WATT_pMotor_Temp_Margin 524198;
BA_ "SPN" SG_ 2298415600 WATT_pMotor_Temp 524201;
BA_ "SPN" SG_ 2298415600 WATT_pJunction_Temp 524203;
BA_ "SPN" SG_ 2298415600 WATT_pController_Temp_Margin 524197;
BA_ "SPN" SG_ 2298415600 WATT_pCapacitor_Temp 524202;
BA_ "SPN" SG_ 2298415600 WATT_pBoard_Temp 524200;
BA_ "SPN" SG_ 2298415600 WATT_pBaseplate_Temp 524199;
BA_ "SPN" SG_ 2298415343 WATT_pController_Therm_Cutback 524259;
BA_ "SPN" SG_ 2298415343 WATT_pSpeed_Lim_Cutback_Status 524258;
BA_ "SPN" SG_ 2298415343 WATT_pMotor_Therm_Cutback 524260;
BA_ "SPN" SG_ 2298415343 WATT_pMotor_Power_Cutback_Status 524240;
BA_ "SPN" SG_ 2298415343 WATT_pI_DC_Cutback_Status 524257;
BA_ "SPN" SG_ 2298415343 WATT_pPower_Msg_Check_Seq 524250;
BA_ "SPN" SG_ 2298415343 WATT_pInput_Current 524195;
BA_ "SPN" SG_ 2298415343 WATT_pCapacitor_Voltage 524196;
BA_ "SPN" SG_ 2298415599 WATT_pTemperature_Msg_Check_Seq 524251;
BA_ "SPN" SG_ 2298415599 WATT_pMotor_Temp_Margin 524198;
BA_ "SPN" SG_ 2298415599 WATT_pMotor_Temp 524201;
BA_ "SPN" SG_ 2298415599 WATT_pJunction_Temp 524203;
BA_ "SPN" SG_ 2298415599 WATT_pController_Temp_Margin 524197;
BA_ "SPN" SG_ 2298415599 WATT_pCapacitor_Temp 524202;
BA_ "SPN" SG_ 2298415599 WATT_pBoard_Temp 524200;
BA_ "SPN" SG_ 2298415599 WATT_pBaseplate_Temp 524199;
BA_ "SPN" SG_ 2566845696 DL_BarometricPressure 108;
BA_ "SigType" SG_ 2566845696 DL_BarometricPressure 1.7E-308;
BA_ "SPN" SG_ 2566845696 CabInteriorTemperature 170;
BA_ "SigType" SG_ 2566845696 CabInteriorTemperature 1.7E-308;
BA_ "SPN" SG_ 2566845696 AmbientAirTemperature 171;
BA_ "SigType" SG_ 2566845696 AmbientAirTemperature 1.7E-308;
BA_ "SPN" SG_ 2566845696 EngineAirInletTemperature 172;
BA_ "SigType" SG_ 2566845696 EngineAirInletTemperature 1.7E-308;
BA_ "SPN" SG_ 2566845696 RoadSurfaceTemperature 79;
BA_ "SigType" SG_ 2566845696 RoadSurfaceTemperature 1.7E-308;
BA_ "SPN" SG_ 2566844672 TwoSpeedAxleSwitch 69;
BA_ "SigType" SG_ 2566844672 TwoSpeedAxleSwitch 1.7E-308;
BA_ "SPN" SG_ 2566844672 ParkingBrakeSwitch 70;
BA_ "SigType" SG_ 2566844672 ParkingBrakeSwitch 1.7E-308;
BA_ "SPN" SG_ 2566844672 Wheel_BasedVehicleSpeed 84;
BA_ "SigType" SG_ 2566844672 Wheel_BasedVehicleSpeed 1.7E-308;
BA_ "SPN" SG_ 2566844672 CruiseCtrlActive 595;
BA_ "SigType" SG_ 2566844672 CruiseCtrlActive 1.7E-308;
BA_ "SPN" SG_ 2566844672 CruiseCtrlEnableSwitch 596;
BA_ "SigType" SG_ 2566844672 CruiseCtrlEnableSwitch 1.7E-308;
BA_ "SPN" SG_ 2566844672 BrakeSwitch 597;
BA_ "SigType" SG_ 2566844672 BrakeSwitch 1.7E-308;
BA_ "SPN" SG_ 2566844672 ClutchSwitch 598;
BA_ "SigType" SG_ 2566844672 ClutchSwitch 1.7E-308;
BA_ "SPN" SG_ 2566844672 CruiseCtrlSetSwitch 599;
BA_ "SigType" SG_ 2566844672 CruiseCtrlSetSwitch 1.7E-308;
BA_ "SPN" SG_ 2566844672 CruiseCtrlCoastSwitch 600;
BA_ "SigType" SG_ 2566844672 CruiseCtrlCoastSwitch 1.7E-308;
BA_ "SPN" SG_ 2566844672 CruiseCtrlResumeSwitch 601;
BA_ "SigType" SG_ 2566844672 CruiseCtrlResumeSwitch 1.7E-308;
BA_ "SPN" SG_ 2566844672 CruiseCtrlAccelerateSwitch 602;
BA_ "SigType" SG_ 2566844672 CruiseCtrlAccelerateSwitch 1.7E-308;
BA_ "SPN" SG_ 2566844672 CruiseCtrlSetSpeed 86;
BA_ "SigType" SG_ 2566844672 CruiseCtrlSetSpeed 1.7E-308;
BA_ "SPN" SG_ 2566844672 pOdometerDriveBit 523994;
BA_ "SigType" SG_ 2566844672 pOdometerDriveBit 1.7E-308;
BA_ "SPN" SG_ 2566844672 CruiseCtrlPauseSw 1633;
BA_ "SigType" SG_ 2566844672 CruiseCtrlPauseSw 1.7E-308;
BA_ "SPN" SG_ 2566844672 pCCMessageCounter 524080;
BA_ "SigType" SG_ 2566844672 pCCMessageCounter 1.7E-308;
BA_ "SPN" SG_ 2566844672 pCCChecksum 524079;
BA_ "SigType" SG_ 2566844672 pCCChecksum 1.7E-308;
BA_ "SPN" SG_ 2566844672 pCruiseEnableStatus 524108;
BA_ "SigType" SG_ 2566844672 pCruiseEnableStatus 1.7E-308;
BA_ "SigType" SG_ 2364539904 EngineTorqueMode 1.7E-308;
BA_ "SPN" SG_ 2364539904 DriversDemandEngine_PercTorque 512;
BA_ "SigType" SG_ 2364539904 DriversDemandEngine_PercTorque 1.7E-308;
BA_ "SPN" SG_ 2364539904 ActualEngine_PercTorque 513;
BA_ "SigType" SG_ 2364539904 ActualEngine_PercTorque 1.7E-308;
BA_ "SigType" SG_ 2364539904 EngineSpeed 1.7E-308;
BA_ "SPN" SG_ 2364539904 SourceAddress 1481;
BA_ "SigType" SG_ 2364539904 SourceAddress 1.7E-308;
BA_ "SPN" SG_ 2364539904 EngineStarterMode 1675;
BA_ "SigType" SG_ 2364539904 EngineStarterMode 1.7E-308;
BA_ "SPN" SG_ 2364539904 EngineDemand_PercentTorque 2432;
BA_ "SigType" SG_ 2364539904 EngineDemand_PercentTorque 1.7E-308;
VAL_ 2432656774 pOperatorButton29 0 "Button Not Pressed" 1 "Button Pressed" 2 "Error" 3 "Not Available";
VAL_ 2432656774 pOperatorButton1 0 "Not Pressed" 1 "Pressed" 2 "Error" 3 "Not Available";
VAL_ 2432656774 pOperatorButton2 0 "Active" 1 "Inactive" 2 "Error" 3 "Not Available";
VAL_ 2432656774 pOperatorButton3 0 "Not Pressed" 1 "Pressed" 2 "Error" 3 "Not Available";
VAL_ 2432656774 pOperatorButton4 0 "Not Pressed" 1 "Pressed" 2 "Error" 3 "Not Available";
VAL_ 2432656774 pOperatorButton5 0 "Not Pressed" 1 "Pressed" 2 "Error" 3 "Not Available";
VAL_ 2432656774 pOperatorButton6 0 "Not Pressed" 1 "Pressed" 2 "Error" 3 "Not Available";
VAL_ 2432656774 pOperatorButton7 0 "Not Pressed" 1 "Pressed" 2 "Error" 3 "Not Available";
VAL_ 2432656774 pOperatorButton8 0 "Not Pressed" 1 "Pressed" 2 "Error" 3 "Not Available";
VAL_ 2432656774 pOperatorButton9 0 "Not Pressed" 1 "Pressed" 2 "Error" 3 "Not Available";
VAL_ 2432656774 pOperatorButton10 0 "Not Pressed" 1 "Pressed" 2 "Error" 3 "Not Available";
VAL_ 2432656774 pOperatorButton11 0 "Not Pressed" 1 "Pressed" 2 "Error" 3 "Not Available";
VAL_ 2432656774 pOperatorButton12 0 "Not Pressed" 1 "Pressed" 2 "Error" 3 "Not Available";
VAL_ 2432656774 pOperatorButton13 0 "Not Pressed" 1 "Pressed" 2 "Error" 3 "Not Available";
VAL_ 2432656774 pOperatorButton14 0 "Not Pressed" 1 "Pressed" 2 "Error" 3 "Not Available";
VAL_ 2432656774 pOperatorButton15 0 "Not Pressed" 1 "Pressed" 2 "Error" 3 "Not Available";
VAL_ 2432656774 pOperatorButton16 0 "Not Pressed" 1 "Pressed" 2 "Error" 3 "Not Available";
VAL_ 2432656774 pOperatorButton17 0 "Not Pressed" 1 "Pressed" 2 "Error" 3 "Not Available";
VAL_ 2432656774 pOperatorButton18 0 "Not Pressed" 1 "Pressed" 2 "Error" 3 "Not Available";
VAL_ 2432656774 pOperatorButton19 0 "Not Pressed" 1 "Pressed" 2 "Error" 3 "Not Available";
VAL_ 2432656774 pOperatorButton20 0 "Not Pressed" 1 "Pressed" 2 "Error" 3 "Not Available";
VAL_ 2432656774 pOperatorButton21 0 "Not Pressed" 1 "Pressed" 2 "Error" 3 "Not Available";
VAL_ 2432656774 pOperatorButton22 0 "Not Pressed" 1 "Pressed" 2 "Error" 3 "Not Available";
VAL_ 2432656774 pOperatorButton23 0 "Not Pressed" 1 "Pressed" 2 "Error" 3 "Not Available";
VAL_ 2432656774 pOperatorButton24 0 "Not Pressed" 1 "Pressed" 2 "Error" 3 "Not Available";
VAL_ 2432656774 pOperatorButton25 0 "Not Pressed" 1 "Pressed" 2 "Error" 3 "Not Available";
VAL_ 2432656774 pOperatorButton26 0 "Not Pressed" 1 "Pressed" 2 "Error" 3 "Not Available";
VAL_ 2432656774 pOperatorButton27 0 "Not Pressed" 1 "Pressed" 2 "Error" 3 "Not Available";
VAL_ 2432656774 pOperatorButton28 0 "Not Pressed" 1 "Pressed" 2 "Error" 3 "Not Available";
VAL_ 2432656774 pSideStandStatus 0 "Side Stand Down" 1 "Side Stand Up" 2 "Error Indicator" 3 "Not Available";
VAL_ 2565799489 ArbitraryAddressCapable 0 "No" 1 "Yes";
VAL_ 2565799453 ArbitraryAddressCapable 0 "No" 1 "Yes";
VAL_ 2565799447 ArbitraryAddressCapable 0 "No" 1 "Yes";
VAL_ 2565799443 ArbitraryAddressCapable 0 "No" 1 "Yes";
VAL_ 2565799435 ArbitraryAddressCapable 0 "No" 1 "Yes";
VAL_ 2565799424 ArbitraryAddressCapable 0 "No" 1 "Yes";
VAL_ 2631794205 EncryptionIndicatorStates 0 "Encryption seed request" 1 "Encryption code present" 2 "Not defined" 3 "Not available";
VAL_ 2631794205 AntiTheftDesiredExitModeStates 0 "Locked upon operator request" 1 "Lock when key off" 2 "Not defined" 3 "Not available";
VAL_ 2631794205 AntiTheftCommandStates 0 "Add password" 1 "Delete password" 2 "Change password" 3 "Lock or Unlock" 4 "Check status" 5 "Login";
VAL_ 2631794199 EncryptionIndicatorStates 0 "Encryption seed request" 1 "Encryption code present" 2 "Not defined" 3 "Not available";
VAL_ 2631794199 AntiTheftDesiredExitModeStates 0 "Locked upon operator request" 1 "Lock when key off" 2 "Not defined" 3 "Not available";
VAL_ 2631794199 AntiTheftCommandStates 0 "Add password" 1 "Delete password" 2 "Change password" 3 "Lock or Unlock" 4 "Check status" 5 "Login";
VAL_ 2631728640 AntiTheftEncryptSeedPresentInd 0 "Random number is not present" 1 "Random number is present" 2 "Reserved" 3 "Don't care";
VAL_ 2631728640 AntiTheftPasswordValidIndicator 0 "Password is not a validated pass" 1 "Password is a validated password" 2 "Reserved" 3 "Don't care";
VAL_ 2631728640 AntiTheftModifyPasswordStates 0 "Ok" 1 "Full of passwords" 2 "Empty of passwords" 3 "Not valid";
VAL_ 2631728640 AntiTheftComponentStatusInd 0 "Unlocked" 1 "Locked" 2 "Blocked" 3 "Not defined";
VAL_ 2561212031 TextDisplayInstructions 0 "Clear Display" 1 "Hold Display" 2 "Append at end of display" 3 "Overwrite display" 4 "Overwrite substring" 5 "Highlight substring" 6 "Blink substring" 7 "Reserved" 15 "Not applicable";
VAL_ 2566904832 DL22_pMisfireDetectedMultplSrcs 0 "Inactive" 1 "Active" 2 "Error" 3 "Not Available";
VAL_ 2566904832 DL22_pCatDamageMisfireRateExceed 0 "Inactive" 1 "Active" 2 "Error" 3 "Not Available";
VAL_ 2432658432 pOperatorButton42 0 "Button not pressed" 1 "Button pressed" 2 "Error" 3 "Not Available";
VAL_ 2432658432 pOperatorButton41 0 "Button not pressed" 1 "Button pressed" 2 "Error" 3 "Not Available";
VAL_ 2432658432 pOperatorButton39 0 "Button Not Pressed" 1 "Button Pressed" 2 "Error" 3 "Not Available";
VAL_ 2432658432 pOperatorButton37 0 "Button Not Pressed" 1 "Button Pressed" 2 "Error" 3 "Not Available";
VAL_ 2432658432 pOperatorButton36 0 "Button Not Pressed" 1 "Button Pressed" 2 "Error" 3 "Not Available";
VAL_ 2432658432 pOperatorButton40 0 "Disabled" 1 "Enabled" 2 "Error" 3 "Not Available";
VAL_ 2432658432 pOperatorButton38 0 "Button Not Pressed" 1 "Button Pressed" 2 "Error" 3 "Not Available";
VAL_ 2432658432 pOperatorButton35 0 "Button Not Pressed" 1 "Button Pressed" 2 "Error" 3 "Not Available";
VAL_ 2432658432 pOperatorButton34 0 "Button Not Pressed" 1 "Button Pressed" 2 "Error" 3 "Not Available";
VAL_ 2432658432 pOperatorButton33 0 "Button Not Pressed" 1 "Button Pressed" 2 "Error" 3 "Not Available";
VAL_ 2432658432 pOperatorButton32 0 "Button Not Pressed" 1 "Button Pressed" 2 "Error" 3 "Not Available";
VAL_ 2432658432 pOperatorButton31 0 "Button Not Pressed" 1 "Button Pressed" 2 "Error" 3 "Not Available";
VAL_ 2432658432 pOperatorButton30 0 "Button Not Pressed" 1 "Button Pressed" 2 "Error" 3 "Not Available";
VAL_ 2432658432 pOperatorButton29 0 "Button Not Pressed" 1 "Button Pressed" 2 "Error" 3 "Not Available";
VAL_ 2633984512 pHeatedGripEnable 0 "Disabled (Not installed)" 1 "Enabled (Installed)" 2 "Error Indicator" 3 "Description for the value '3'";
VAL_ 2633984512 pSideStandStatus 0 "Side Stand Down" 1 "Side Stand Up" 2 "Error Indicator" 3 "Not Available";
VAL_ 2633984512 pTetherSwitchStatus 0 "Tether SW Closed (connected)" 1 "Tether SW Open (disconnected)" 2 "Error" 3 "Not Available";
VAL_ 2633984512 pLowFuelIndicatorStatus 0 "Low Fuel Indicator Off" 1 "Low Fuel Indicator On" 2 "Error" 3 "Not Available";
VAL_ 2633984512 pOperatorNotInOperatingStation 0 "Operator In OperatorStation" 1 "Operator Not In OperatorStation" 2 "Error" 3 "Description for the value '3'";
VAL_ 2633984512 pParkBrakeIndicatorStatus 0 "Park Brake Indicator Off" 1 "Park Brake Indicator On (Solid)" 2 "Park Brake Indicator 1 Hz flash" 3 "Park Brake Indicator 2 Hz flash" 4 "Available for future use" 5 "Available for future use" 6 "Error Indicator" 7 "Not Available";
VAL_ 2633984512 pADCRequested 0 "ADC Mode not Requested" 1 "ADC Mode Requested" 2 "Error" 3 "Not Available";
VAL_ 2633984512 pAWDModeRequested 0 "AWD Mode not Requested" 1 "AWD Mode Requested" 2 "Error" 3 "Not Available";
VAL_ 2633984512 pRWDModeRequested 0 "RWD Mode not Requested" 1 "RWD Mode Requested" 2 "Error" 3 "Not Available";
VAL_ 2633984512 pTurfModeRequested 0 "Turf Mode not Requested" 1 "Turf Mode Requested" 2 "Error" 3 "Not Available";
VAL_ 2633984512 pADCStatus 0 "ADC Actuator Not Engaged" 1 "ADC Actuator Engaged" 2 "Error" 3 "Not available";
VAL_ 2633984512 pTreadleNeutralStatus 0 "Treadle Neutral Not Engaged" 1 "Treadle Neutral Engaged" 2 "Error" 3 "Not Available";
VAL_ 2633984512 pTreadleReverseStatus 0 "Treadle Reverse Not Engaged" 1 "Treadle Reverse Engaged" 2 "Error" 3 "Not Available";
VAL_ 2633984512 pSecurityLightStatus 0 "Off" 1 "On (Solid)" 2 "Error (Flashing)" 3 "Not Available";
VAL_ 2633984512 pHighBeamIndicatorStatus 0 "Indicator Off" 1 "Indicator On" 2 "Error (Indicator Flashing)" 3 "Not Available";
VAL_ 2633984512 pCruiseControlSetStatus 0 "Cruise Not Set" 1 "Cruise Set" 2 "Error (Lamp Flashing)" 3 "Not Available";
VAL_ 2633984512 pSeatBeltIndicatorStatus 0 "Seat_Belt_Indicator_Off" 1 "Seat_Belt_Indicator_On_Solid" 2 "Seat_Belt_Indicator_1Hz" 3 "Seat_Belt_Indicator_2Hz" 4 "Future1" 5 "Future2" 6 "Error" 7 "Not_Available";
VAL_ 2565867008 Location 255 "NotAvailable";
VAL_ 2565867008 DifferentialLockFrontAxle1 0 "Disengage" 1 "Engage" 2 "Reserved" 3 "NoAction";
VAL_ 2565867008 DifferentialLockFrontAxle2 0 "Disengage" 1 "Engage" 2 "Reserved" 3 "NoAction";
VAL_ 2565867008 DifferentialLockRearAxle1 0 "Disengage" 1 "Engage" 2 "Reserved" 3 "NoAction";
VAL_ 2565867008 DifferentialLockRearAxle2 0 "Disengage" 1 "Engage" 2 "Reserved" 3 "NoAction";
VAL_ 2565867008 DifferentialCentral 0 "Disengage" 1 "Engage" 2 "Reserved" 3 "NoAction";
VAL_ 2565867008 DifferentialCentralFront 0 "Disengage" 1 "Engage" 2 "Reserved" 3 "NoAction";
VAL_ 2565867008 DifferentialCentralRear 0 "Disengage" 1 "Engage" 2 "Reserved" 3 "NoAction";
VAL_ 2566834688 DM_ProtectLampStatus 0 "Lamp off" 1 "Lamp on" 2 "Reserved" 3 "Not available";
VAL_ 2566834688 DM_RedStopLampState 0 "Lamp off" 1 "Lamp on" 2 "Reserved" 3 "Not available";
VAL_ 2566834688 DM_AmberWrningLmpStatus 0 "Lamp off" 1 "Lamp on" 2 "Reserved" 3 "Not available";
VAL_ 2566834688 DM_MalfuncnIndicatorLampStatus 0 "Lamp off" 1 "Lamp on" 2 "Reserved" 3 "Not available";
VAL_ 2566834688 DM_FlashRedStopLamp 0 "Slow Flash (1 Hz, 50% DC)" 1 "Fast Flash (2 Hz, 50% DC)" 2 "Reserved" 3 "Unavailable / Do Not Flash";
VAL_ 2566834688 DM_FlashMalfuncIndicatorLamp 0 "Slow Flash (1 Hz, 50% DC)" 1 "Fast Flash (2 Hz, 50% DC)" 2 "Reserved" 3 "Unavailable / Do Not Flash";
VAL_ 2566834688 DM_FlashProtectLamp 0 "Slow Flash (1 Hz, 50% DC)" 1 "Fast Flash (2 Hz, 50% DC)" 2 "Reserved" 3 "Unavailable / Do Not Flash";
VAL_ 2566834688 DM_FlashAmberWarningLamp 0 "Slow Flash (1 Hz, 50% DC)" 1 "Fast Flash (2 Hz, 50% DC)" 2 "Reserved" 3 "Unavailable / Do Not Flash";
VAL_ 2564356352 DM15_Seed 0 "Seed Complete - send key" 1 "Use Long Seed or Key" 65535 "No Further Key required of Tool";
VAL_ 2564356352 DM15_Error_Ind_EDC_Parameter 0 "No Error" 1 "Error NOT identified" 2 "Currently processing for another" 16 "Currently processing Erase Req" 17 "Currently processing Read Req" 18 "Currently processing Write Req" 19 "Currently processing Status Req" 22 "Currently processing Boot Req" 23 "Currently processing Gen Req" 31 "Currently processing request" 32 "EDC parm not correct for data" 33 "RAM did not verify on Write" 34 "FLASH did not verify on Write" 35 "PROM did not verify on Write" 36 "Internal failure preventing req" 256 "Addressing or DATA General Error" 257 "Addressing Error bounds invalid" 258 "Addressing Error Length invalid" 259 "Addressing Error exceeded memory" 260 "Addressing Error requires erase" 261 "Addressing Error requires erase" 262 "Addressing Error requires trans" 263 "Addressing Error wrong memory" 264 "Addressing Error invalid bounds" 265 "DATA Error invalid value ranges" 266 "DATA Error NAME unexpected value" 4096 "Security Error General" 4097 "Security Error Invalid Password" 4098 "Security Error Invalid User Lvl" 4099 "Security Error Invalid Key" 4100 "Security Error NOT in Diag mode" 4101 "Security Error NOT in Dev mode" 4102 "Security Error - Engine running" 4103 "Security Error - NOT in Park" 65536 "Abort from external" 65537 "Too Many Retries" 65538 "NO response in the time allowed" 65539 "Transport NOT initiated in time" 65540 "Transport NOT completed in time" 16777215 "No Error Indicator Available";
VAL_ 2564356352 DM15_EDCP_Extension 0 "Completed" 2 "More, Higher order EDC Parameter" 3 "More, Lower order EDC Parameter" 6 "Data in Error Indicator" 7 "Data in Error Indicator" 255 "No Error/EDC Parameter Available";
VAL_ 2564356352 DM15_Status 0 "Proceed" 1 "Busy" 2 "Reserved" 3 "Reserved" 4 "Operation Completed" 5 "Operation Failed" 6 "Reserved" 7 "Reserved";
VAL_ 2633883392 FrtWheelDriveActuatorStatus 0 "Front Wheel Drive Actuator not e" 1 "Front Wheel Drive Actuator engag" 2 "Error" 3 "Not available";
VAL_ 2432656640 pOperatorButton29 0 "Button Not Pressed" 1 "Button Pressed" 2 "Error" 3 "Not Available";
VAL_ 2432656640 pOperatorButton1 0 "Not Pressed" 1 "Pressed" 2 "Error" 3 "Not Available";
VAL_ 2432656640 pOperatorButton2 0 "Active" 1 "Inactive" 2 "Error" 3 "Not Available";
VAL_ 2432656640 pOperatorButton3 0 "Not Pressed" 1 "Pressed" 2 "Error" 3 "Not Available";
VAL_ 2432656640 pOperatorButton4 0 "Not Pressed" 1 "Pressed" 2 "Error" 3 "Not Available";
VAL_ 2432656640 pOperatorButton5 0 "Not Pressed" 1 "Pressed" 2 "Error" 3 "Not Available";
VAL_ 2432656640 pOperatorButton6 0 "Not Pressed" 1 "Pressed" 2 "Error" 3 "Not Available";
VAL_ 2432656640 pOperatorButton7 0 "Not Pressed" 1 "Pressed" 2 "Error" 3 "Not Available";
VAL_ 2432656640 pOperatorButton8 0 "Not Pressed" 1 "Pressed" 2 "Error" 3 "Not Available";
VAL_ 2432656640 pOperatorButton9 0 "Not Pressed" 1 "Pressed" 2 "Error" 3 "Not Available";
VAL_ 2432656640 pOperatorButton10 0 "Not Pressed" 1 "Pressed" 2 "Error" 3 "Not Available";
VAL_ 2432656640 pOperatorButton11 0 "Not Pressed" 1 "Pressed" 2 "Error" 3 "Not Available";
VAL_ 2432656640 pOperatorButton12 0 "Not Pressed" 1 "Pressed" 2 "Error" 3 "Not Available";
VAL_ 2432656640 pOperatorButton13 0 "Not Pressed" 1 "Pressed" 2 "Error" 3 "Not Available";
VAL_ 2432656640 pOperatorButton14 0 "Not Pressed" 1 "Pressed" 2 "Error" 3 "Not Available";
VAL_ 2432656640 pOperatorButton15 0 "Not Pressed" 1 "Pressed" 2 "Error" 3 "Not Available";
VAL_ 2432656640 pOperatorButton16 0 "Not Pressed" 1 "Pressed" 2 "Error" 3 "Not Available";
VAL_ 2432656640 pOperatorButton17 0 "Not Pressed" 1 "Pressed" 2 "Error" 3 "Not Available";
VAL_ 2432656640 pOperatorButton18 0 "Not Pressed" 1 "Pressed" 2 "Error" 3 "Not Available";
VAL_ 2432656640 pOperatorButton19 0 "Not Pressed" 1 "Pressed" 2 "Error" 3 "Not Available";
VAL_ 2432656640 pOperatorButton20 0 "Not Pressed" 1 "Pressed" 2 "Error" 3 "Not Available";
VAL_ 2432656640 pOperatorButton21 0 "Not Pressed" 1 "Pressed" 2 "Error" 3 "Not Available";
VAL_ 2432656640 pOperatorButton22 0 "Not Pressed" 1 "Pressed" 2 "Error" 3 "Not Available";
VAL_ 2432656640 pOperatorButton23 0 "Not Pressed" 1 "Pressed" 2 "Error" 3 "Not Available";
VAL_ 2432656640 pOperatorButton24 0 "Not Pressed" 1 "Pressed" 2 "Error" 3 "Not Available";
VAL_ 2432656640 pOperatorButton25 0 "Not Pressed" 1 "Pressed" 2 "Error" 3 "Not Available";
VAL_ 2432656640 pOperatorButton26 0 "Not Pressed" 1 "Pressed" 2 "Error" 3 "Not Available";
VAL_ 2432656640 pOperatorButton27 0 "Not Pressed" 1 "Pressed" 2 "Error" 3 "Not Available";
VAL_ 2432656640 pOperatorButton28 0 "Not Pressed" 1 "Pressed" 2 "Error" 3 "Not Available";
VAL_ 2432656640 pSideStandStatus 0 "Side Stand Down" 1 "Side Stand Up" 2 "Error Indicator" 3 "Not Available";
VAL_ 2365548032 pHighIdleState 0 "Inactive" 1 "Active" 2 "Error" 3 "Not Available";
VAL_ 2365548032 pStuckThrottle 0 "Throttle not Stuck" 1 "Throttle Stuck" 2 "Error" 3 "Not Available";
VAL_ 2566909696 DL12_LambaSensorHeaterOutBank2 0 "Active" 1 "Inactive" 2 "Error" 3 "NotAvailable";
VAL_ 2566909696 DL12_AirFuelMixStatusBank2 0 "Rich" 1 "Lean" 2 "Error" 3 "NotAvailable";
VAL_ 2566909696 DL12_ClosedLoopMixControlBank2 0 "Active" 1 "Inactive" 2 "Error" 3 "NotAvailable";
VAL_ 2566912256 DL7_FuelTypSelected 0 "Fuel Type 1 (E0)" 1 "Fuel Type 1 (E5)" 2 "Fuel Type 1 (E7)" 3 "Fuel Type 1 (E10)" 4 "Fuel Type 1 (E15)" 5 "Fuel Type 1 (E20)" 6 "Fuel Type 1 (E85)" 7 "Fuel Type 1 (E95)" 8 "Fuel Type 1 (E100)" 14 "Fuel Type Error" 15 "Not Available";
VAL_ 2566912256 DL7_EngRunngMode 0 "Steady" 1 "Transient";
VAL_ 2566912000 DL8_LambaSensorHeaterOutBank1 0 "Active" 1 "Inactive" 2 "Error" 3 "NotAvailable";
VAL_ 2566912000 DL8_AirFuelMixStatusBank1 0 "Rich" 1 "Lean" 2 "Error" 3 "NotAvailable";
VAL_ 2566912000 DL8_ClosedLoopMixControlBank1 0 "Active" 1 "Inactive" 2 "Error" 3 "NotAvailable";
VAL_ 2566911232 FI1_FuelPullSolenoidStatus 0 "Active" 1 "Inactive" 2 "Error" 3 "Not Available";
VAL_ 2566911232 FI1_ClutchSwitchInput2 0 "Active" 1 "Inactive" 2 "Error" 3 "Not Available";
VAL_ 2566911232 FI1_FuelPumpDriverCkt 0 "Active" 1 "Inactive" 2 "Error" 3 "Not Available";
VAL_ 2566911232 FI1_RolloverSwitch 0 "Active" 1 "Inactive" 2 "Error" 3 "Not Available";
VAL_ 2566911232 FI1_CrankSensorSignal 0 "Present" 1 "Absent" 2 "Error" 3 "Not Available";
VAL_ 2566911232 FI1_CamSensorSignal 0 "Present" 1 "Absent" 2 "Error" 3 "Not Available";
VAL_ 2566911232 FI1_RPMLimitActive 0 "Active" 1 "Inactive" 2 "Error" 3 "Not Available";
VAL_ 2566911232 FI1_IdleSwitch 0 "Active" 1 "Inactive" 2 "Error" 3 "Not Available";
VAL_ 2566911232 FI1_CycleSynchro 0 "Sync" 1 "No-Sync" 2 "Error" 3 "Not Available";
VAL_ 2566911232 FI1_IdleSpeedControlStatus 0 "Active" 1 "Inactive" 2 "Error" 3 "Not Available";
VAL_ 2566911232 FI1_IgnitionSwitchInput 0 "Input High" 1 "Input Low" 2 "Error" 3 "Not Available";
VAL_ 2566911232 FI1_RunStopSwitchInput 0 "Input High" 1 "Input Low" 2 "Error" 3 "Not Available";
VAL_ 2566911232 FI1_StartSwitchInput 0 "Input High" 1 "Input Low" 2 "Error" 3 "Not Available";
VAL_ 2566911232 FI1_ThrottleSafetySwInput 0 "Input High" 1 "Input Low" 2 "Error" 3 "Not Available";
VAL_ 2566911232 FI1_FanRelayOutput 0 "Active" 1 "Inactive" 2 "Error" 3 "Not Available";
VAL_ 2566911232 FI1_IntercoolerFanOutput 0 "Active" 1 "Inactive" 2 "Error" 3 "Not Available";
VAL_ 2566911232 FI1_ReverseAlarmOutput 0 "Active" 1 "Inactive" 2 "Error" 3 "Not Available";
VAL_ 2566911232 FI1_MainRelayOutput 0 "Active" 1 "Inactive" 2 "Error" 3 "Not Available";
VAL_ 2566911232 FI1_StartSolenoidOutput 0 "Active" 1 "Inactive" 2 "Error" 3 "Not Available";
VAL_ 2566911232 FI1_IgnitionRelayOutput 0 "Active" 1 "Inactive" 2 "Error" 3 "Not Available";
VAL_ 2566911232 FI1_ChassisRelayOutput 0 "Active" 1 "Inactive" 2 "Error" 3 "Not Available";
VAL_ 2566911232 FI1_StarterEnableOutput 0 "Active" 1 "Inactive" 2 "Error" 3 "Not Available";
VAL_ 2566911232 FI1_ExhaustValveOutput 0 "Active" 1 "Inactive" 2 "Error" 3 "Not Available";
VAL_ 2566911232 FI1_BatteryChargeRelayOutput 0 "Active" 1 "Inactive" 2 "Error" 3 "Not Available";
VAL_ 2566911232 FI1_HeaterAccRelay 0 "Active" 1 "Inactive" 2 "Error" 3 "Not Available";
VAL_ 2566911232 FI1_ClutchSwitchInput 0 "Input High" 1 "Input Low" 2 "Error" 3 "Not Available";
VAL_ 2566911232 FI1_MILLampOutput 0 "Active" 1 "Inactive" 2 "Error" 3 "Not Available";
VAL_ 2566911232 FI1_OverTempLampOutput 0 "Active" 1 "Inactive" 2 "Error" 3 "Not Available";
VAL_ 2566911232 FI1_KnockDetLampOutput 0 "Active" 1 "Inactive" 2 "Error" 3 "Not Available";
VAL_ 2566911232 FI1_ElecOilPumpDrvrCirc 0 "Active" 1 "Inactive" 2 "Error" 3 "Not Available";
VAL_ 2566910976 FI2_ThrttlBdyInitLrnValSave 0 "False" 1 "True" 2 "Error" 3 "Not Available";
VAL_ 2566910976 FI2_ThrttlBdyInitLearnSuccess 0 "False" 1 "True" 2 "Error" 3 "Not Available";
VAL_ 2566910976 FI2_ThrottleLimpHomeOpCondition 0 "Active" 1 "Inactive" 2 "Error" 3 "Not Available";
VAL_ 2566910976 FI2_SystemOnInput 0 "Input High" 1 "Input Low" 2 "Error" 3 "Not Available";
VAL_ 2566910976 FI2_SftyFuelCutoffCndn 0 "Active" 1 "Inactive" 2 "Error" 3 "Not Available";
VAL_ 2566910976 FI2_RvrsblInjCutoffCndn 0 "Active" 1 "Inactive" 2 "Error" 3 "Not Available";
VAL_ 2566910976 FI2_PTOEngagementStatus 0 "Active" 1 "Inactive" 2 "Error" 3 "Not Available";
VAL_ 2566910976 FI2_ParkBrakeSwitchIn 0 "Input High" 1 "Input Low" 2 "Error" 3 "Not Available";
VAL_ 2566910976 FI2_NeutralSwitchIn 0 "Input High" 1 "Input Low" 2 "Error" 3 "Not Available";
VAL_ 2566910976 FI2_IrrvrsblInjCutoffCndn 0 "Active" 1 "Inactive" 2 "Error" 3 "Not Available";
VAL_ 2566910976 FI2_ETCFncnMonitor 0 "Active" 1 "Inactive" 2 "Error" 3 "Not Available";
VAL_ 2566910976 FI2_ADCOutput 0 "Active" 1 "Inactive" 2 "Error" 3 "Not Available";
VAL_ 2566910976 FI2_RearDiffLockOutput 0 "Active" 1 "Inactive" 2 "Error" 3 "Not Available";
VAL_ 2566910976 FI2_AWDOutput 0 "Active" 1 "Inactive" 2 "Error" 3 "Not Available";
VAL_ 2566910976 FI2_BrakeSwitchInput 0 "Input High" 1 "Input Low" 2 "Error" 3 "Not Available";
VAL_ 2566910976 FI2_ADCSwitchInput 0 "Input High" 1 "Input Low" 2 "Error" 3 "Not Available";
VAL_ 2566910976 FI2_TurfModeInput 0 "Input High" 1 "Input Low" 2 "Error" 3 "Not Available";
VAL_ 2566910976 FI2_AWDSwitchInput 0 "Input High" 1 "Input Low" 2 "Error" 3 "Not Available";
VAL_ 2566910976 FI2_ReverseSwitchInput 0 "Input High" 1 "Input Low" 2 "Error" 3 "Not Available";
VAL_ 2566910976 FI2_ReverseLimitSwitchInput 0 "Input High" 1 "Input Low" 2 "Error" 3 "Not Available";
VAL_ 2566910976 FI2_ForwardLimitSwitchInput 0 "Input High" 1 "Input Low" 2 "Error" 3 "Not Available";
VAL_ 2566910976 FI2_EngineDirection 0 "Input High" 1 "Input Low" 2 "Error" 3 "Not Available";
VAL_ 2566910976 FI2_RevSpeedLimitOverrideInput 0 "Input High" 1 "Input Low" 2 "Error" 3 "Not Available";
VAL_ 2566910976 FI2_ReverseOverspeedSignal 0 "Input High" 1 "Input Low" 2 "Error" 3 "Not Available";
VAL_ 2566910976 FI2_RightTurnSignalInput 0 "Input High" 1 "Input Low" 2 "Error" 3 "Not Available";
VAL_ 2566910976 FI2_LeftTurnSignalInput 0 "Input High" 1 "Input Low" 2 "Error" 3 "Not Available";
VAL_ 2566910976 FI2_KickstandSwitchInput 0 "Input High" 1 "Input Low" 2 "Error" 3 "Not Available";
VAL_ 2566910976 FI2_ReflashEnableInputSignal 0 "Input High" 1 "Input Low" 2 "Error" 3 "Not Available";
VAL_ 2566910976 FI2_TPSLearnInputSignal 0 "Input High" 1 "Input Low" 2 "Error" 3 "Not Available";
VAL_ 2566910976 FI2_LowRangeSwitchInput 0 "Active" 1 "Inactive" 2 "Error" 3 "Not Available";
VAL_ 2566910976 FI2_ReverseMotorDriveInput 0 "Input High" 1 "Input Low" 2 "Error" 3 "Not Available";
VAL_ 2633984768 pADCModeAvailability 0 "ADC Not Available" 1 "ADC Mode Available" 2 "Error" 3 "Not Available";
VAL_ 2633984768 pAWDModeAvailability 0 "AWD Not Available" 1 "AWD Mode Available" 2 "Error" 3 "Not Available";
VAL_ 2633984768 pTurfModeAvailability 0 "Turf Mode Not Available" 1 "Turf Mode Available" 2 "Error" 3 "Not Available";
VAL_ 2633984768 pFuelLevelDataSource 0 "Analog (Direct to Device)" 1 "CAN" 2 "Error Indicator" 3 "Not Available";
VAL_ 2633984768 pVehicleUnitsConfig 0 "US12" 1 "US24" 2 "INT12" 3 "INT24" 4 "UK12" 5 "UK24" 6 "Available for future use" 14 "Error Indicator" 15 "Not Available";
VAL_ 2633984768 pFuelEconomyDataSource 0 "ECM to Calculate" 1 "Gauge to Calculate" 2 "Error Indicator" 3 "Description for the value '3'";
VAL_ 2633984768 pSeatBeltInputSource 0 "ECM to read switch input" 1 "Gauge to read switch input" 2 "Error" 3 "Not Available";
VAL_ 2566910720 FI3_OilPressSwIn 0 "Input High" 1 "Input Low" 2 "Error" 3 "Not Available";
VAL_ 2566910720 FI3_BrkSw2In 0 "Input High" 1 "Input Low" 2 "Error" 3 "Not Available";
VAL_ 2566910720 FI3_CruiseCtrlResumeOut 0 "Active" 1 "Inactive" 2 "Error" 3 "Not Available";
VAL_ 2566910720 FI3_CruiseCtrlResumeIn 0 "Active" 1 "Inactive" 2 "Error" 3 "Not Available";
VAL_ 2566910720 FI3_CruiseCtrlCancelIn 0 "Active" 1 "Inactive" 2 "Error" 3 "Not Available";
VAL_ 2566910720 FI3_TetherSwStatus 0 "Active" 1 "Inactive" 2 "Error" 3 "Not Available";
VAL_ 2566910720 FI3_DriveMode1Input 0 "Active" 1 "Inactive" 2 "Error" 3 "Not Available";
VAL_ 2566910720 FI3_DriveMode2Input 0 "Active" 1 "Inactive" 2 "Error" 3 "Not Available";
VAL_ 2566910720 FI3_DriveMode3Input 0 "Active" 1 "Inactive" 2 "Error" 3 "Not Available";
VAL_ 2566910720 FI3_DriverMode4Input 0 "Active" 1 "Inactive" 2 "Error" 3 "Not Available";
VAL_ 2566910720 FI3_DriverMode1Output 0 "Active" 1 "Inactive" 2 "Error" 3 "Not Available";
VAL_ 2566910720 FI3_DriverMode2Output 0 "Active" 1 "Inactive" 2 "Error" 3 "Not Available";
VAL_ 2566910720 FI3_DriverMode3Output 0 "Active" 1 "Inactive" 2 "Error" 3 "Not Available";
VAL_ 2566910720 FI3_DriverMode4Ouput 0 "Active" 1 "Inactive" 2 "Error" 3 "Not Available";
VAL_ 2566910720 FI3_PTOModeInput 0 "Active" 1 "Inactive" 2 "Error" 3 "Not Available";
VAL_ 2566910720 FI3_PTOModeOutput 0 "Active" 1 "Inactive" 2 "Error" 3 "Not Available";
VAL_ 2566910720 FI3_DriversNetEngagement 0 "Engage" 1 "Disengage" 2 "Error" 3 "Unavailable";
VAL_ 2566910720 FI3_DriversSeatbeltEngagement 0 "Engage" 1 "Disengage" 2 "Error" 3 "Unavailable";
VAL_ 2566910720 FI3_TiltLockInput 0 "Active" 1 "Inactive" 2 "Error" 3 "Not Available";
VAL_ 2566910720 FI3_WorkGroupLockInput 0 "Active" 1 "Inactive" 2 "Error" 3 "Not Available";
VAL_ 2566910720 FI3_OperatorPresenceInput 0 "Active" 1 "Inactive" 2 "Error" 3 "Not Available";
VAL_ 2566910720 FI3_WorkGroupLockOutput 0 "Active" 1 "Inactive" 2 "Error" 3 "Not Available";
VAL_ 2566910720 FI3_OperatorPresenceOutput 0 "Active" 1 "Inactive" 2 "Error" 3 "Not Available";
VAL_ 2566910720 FI3_FootOnCruiseInput 0 "Active" 1 "Inactive" 2 "Error" 3 "Not Available";
VAL_ 2566910720 FI3_CruiseInput 0 "Active" 1 "Inactive" 2 "Error" 3 "Not Available";
VAL_ 2566910720 FI3_TredalInput 0 "Active" 1 "Inactive" 2 "Error" 3 "Not Available";
VAL_ 2566910720 FI3_CruiseSpeedInput 0 "Active" 1 "Inactive" 2 "Error" 3 "Not Available";
VAL_ 2566910720 FI3_FootOnCruiseOutput 0 "Active" 1 "Inactive" 2 "Error" 3 "Not Available";
VAL_ 2566910720 FI3_CruiseOutput 0 "Active" 1 "Inactive" 2 "Error" 3 "Not Available";
VAL_ 2566910720 FI3_CruiseControltoSetSpeed 0 "Active" 1 "Inactive" 2 "Error" 3 "Not Available";
VAL_ 2566910720 FI3_WorkModeInput 0 "Active" 1 "Inactive" 2 "Error" 3 "Not Available";
VAL_ 2566910720 FI3_TiltLockOutput 0 "Active" 1 "Inactive" 2 "Error" 3 "Not Available";
VAL_ 2566910464 FI4_SeatbeltSw 0 "False" 1 "True" 2 "Error" 3 "Not Available";
VAL_ 2566910464 FI4_pSideStandSw 0 "Active" 1 "Inactive" 2 "Error" 3 "Not Available";
VAL_ 2566910464 FI4_DrvlnMomentaryRight 0 "False" 1 "True" 2 "Error" 3 "Not Available";
VAL_ 2566910464 FI4_DrvlnMomentaryLeft 0 "False" 1 "True" 2 "Error" 3 "Not Available";
VAL_ 2566910464 FI4_BrakeLightOutput 0 "Output Active" 1 "Output Inactive" 2 "Error" 3 "Not Available";
VAL_ 2566910464 FI4_FogLightInput 0 "Input HIGH" 1 "Input LOW" 2 "Error" 3 "Not Available";
VAL_ 2566910464 FI4_HazardLightOutput 0 "Output Active" 1 "Output Inactive" 2 "Error" 3 "Not Available";
VAL_ 2566910464 FI4_HazardSWInput 0 "Input HIGH" 1 "Input LOW" 2 "Error" 3 "Not Available";
VAL_ 2566910464 FI4_HeatGripDecSW 0 "Active" 1 "Inactive" 2 "Error" 3 "Not Available";
VAL_ 2566910464 FI4_HeatGripIncSW 0 "Active" 1 "Inactive" 2 "Error" 3 "Not Available";
VAL_ 2566910464 FI4_HighBeamOutput 0 "Output Active" 1 "Output Inactive" 2 "Error" 3 "Not Available";
VAL_ 2566910464 FI4_HornInput 0 "Input HIGH" 1 "Input LOW" 2 "Error" 3 "Not Available";
VAL_ 2566910464 FI4_HornOutput 0 "Output Active" 1 "Output Inactive" 2 "Error" 3 "Not Available";
VAL_ 2566910464 FI4_LeftFogLightOutput 0 "Output Active" 1 "Output Inactive" 2 "Error" 3 "Not Available";
VAL_ 2566910464 FI4_LFTurnSignalOutput 0 "Output Active" 1 "Output Inactive" 2 "Error" 3 "Not Available";
VAL_ 2566910464 FI4_LockInput 0 "Input HIGH" 1 "Input LOW" 2 "Error" 3 "Not Available";
VAL_ 2566910464 FI4_LowBeamOutput 0 "Output Active" 1 "Output Inactive" 2 "Error" 3 "Not Available";
VAL_ 2566910464 FI4_LowHighBeamInput 0 "Input HIGH" 1 "Input LOW" 2 "Error" 3 "Not Available";
VAL_ 2566910464 FI4_LRTurnSignalOutput 0 "Output Active" 1 "Output Inactive" 2 "Error" 3 "Not Available";
VAL_ 2566910464 FI4_pOperatorButton1 0 "Active" 1 "Inactive" 2 "Error" 3 "Not Available";
VAL_ 2566910464 FI4_RFTurnSignalOutput 0 "Output Active" 1 "Output Inactive" 2 "Error" 3 "Not Available";
VAL_ 2566910464 FI4_RightFogLightOutput 0 "Output Active" 1 "Output Inactive" 2 "Error" 3 "Not Available";
VAL_ 2566910464 FI4_RRTurnSignalOutput 0 "Output Active" 1 "Output Inactive" 2 "Error" 3 "Not Available";
VAL_ 2566910464 FI4_SecondaryAirValveCmd 0 "Output Active" 1 "Output Inactive" 2 "Error" 3 "Not Available";
VAL_ 2566910464 FI4_SecondaryAirValveOut 0 "Output Active" 1 "Output Inactive" 2 "Error" 3 "Not Available";
VAL_ 2566910464 FI4_TailLightOutput 0 "Output Active" 1 "Output Inactive" 2 "Error" 3 "Not Available";
VAL_ 2566910464 FI4_UnlockInput 0 "Input HIGH" 1 "Input LOW" 2 "Error" 3 "Not Available";
VAL_ 2566910464 FI4_WindshieldSWDownInput 0 "Input HIGH" 1 "Input LOW" 2 "Error" 3 "Not Available";
VAL_ 2566910464 FI4_WindshieldSWUpInput 0 "Input HIGH" 1 "Input LOW" 2 "Error" 3 "Not Available";
VAL_ 2566910464 FI4_pOperatorButton2 0 "Active" 1 "Inactive" 2 "Error" 3 "Not Available";
VAL_ 2566878604 pOperationMode 0 "Manned" 1 "Remote" 2 "Error" 3 "Not Available";
VAL_ 2566878604 pStartStopCmd 0 "Button Not Pressed" 1 "Button Pressed" 2 "Error" 3 "Not Available";
VAL_ 2566878464 pStartStopCmd 0 "Button Not Pressed" 1 "Button Pressed" 2 "Error" 3 "Not Available";
VAL_ 2566878464 pOperationMode 0 "Manned" 1 "Remote" 2 "Error" 3 "Not Available";
VAL_ 2566876928 pSecondaryAirValveControl 0 "Valve Request to be Disabled" 1 "Valve Request to be Enabled" 2 "Error" 3 "Not Available";
VAL_ 2566876416 pFootOnCruiseControlEnabled 0 "Foot on cruise control disabled" 1 "Foot on cruise control enabled" 2 "Error" 3 "Not Available";
VAL_ 2297441780 Vertical_Accel_Ext_Merit 0 "Accel fully functional" 1 "Accel degraded" 2 "error" 3 "Not Available";
VAL_ 2297441780 Longitudinal_Accel_Ext_Merit 0 "Accel fully functional" 1 "Accel degraded" 2 "error" 3 "Not Available";
VAL_ 2297441780 Lateral_Accel_Ext_Merit 0 "Accel fully functional" 1 "Accel degraded" 2 "error" 3 "Not Available";
VAL_ 2297441780 Accel_Sensor_Support_Var 0 "Reserved for SAE Assignment" 1 "Reserved for SAE Assignment" 2 "20ms rate supported" 3 "Supports 10ms Tx Rate Only";
VAL_ 2297441779 Vertical_Accel_Ext_Merit 0 "Accel fully functional" 1 "Accel degraded" 2 "error" 3 "Not Available";
VAL_ 2297441779 Longitudinal_Accel_Ext_Merit 0 "Accel fully functional" 1 "Accel degraded" 2 "error" 3 "Not Available";
VAL_ 2297441779 Lateral_Accel_Ext_Merit 0 "Accel fully functional" 1 "Accel degraded" 2 "error" 3 "Not Available";
VAL_ 2297441779 Accel_Sensor_Support_Var 0 "Reserved for SAE Assignment" 1 "Reserved for SAE Assignment" 2 "20ms rate supported" 3 "Supports 10ms Tx Rate Only";
VAL_ 2298415350 WATT_pSpeed_Lim_Cutback_Status 0 "Inactive" 1 "Active";
VAL_ 2298415350 WATT_pMotor_Therm_Cutback 0 "Inactive" 1 "Active";
VAL_ 2298415350 WATT_pMotor_Power_Cutback_Status 0 "Inactive" 1 "Active";
VAL_ 2298415350 WATT_pI_DC_Cutback_Status 0 "Inactive" 1 "Active";
VAL_ 2298415350 WATT_pController_Therm_Cutback 0 "Inactive" 1 "Active";
VAL_ 2298415351 WATT_pSpeed_Lim_Cutback_Status 0 "Inactive" 1 "Active";
VAL_ 2298415351 WATT_pMotor_Therm_Cutback 0 "Inactive" 1 "Active";
VAL_ 2298415351 WATT_pMotor_Power_Cutback_Status 0 "Inactive" 1 "Active";
VAL_ 2298415351 WATT_pI_DC_Cutback_Status 0 "Inactive" 1 "Active";
VAL_ 2298415351 WATT_pController_Therm_Cutback 0 "Inactive" 1 "Active";
VAL_ 2365523456 pModCtlAppliedState 0 "No Change Applied" 1 "Partial Wakeup Applied" 2 "Full Wakeup Applied" 3 "Power Down Applied" 4 "Stay Awake Applied" 5 "Future Use" 6 "Future Use" 7 "Future Use" 8 "Future Use" 9 "Future Use" 10 "Future Use" 11 "Future Use" 12 "Future Use" 13 "No Change - Checksum Error" 14 "Error State" 15 "Not Availble";
VAL_ 2365523456 pModCtlCmdState 0 "No Change Requested" 1 "Partial Wakeup Requested" 2 "Full Wakeup Requested" 3 "Power Down Requested" 4 "Stay Awak Requested" 5 "Future Use" 6 "Future Use" 7 "Future Use" 8 "Future Use" 9 "Future Use" 10 "Future Use" 11 "Future Use" 12 "Future Use" 13 "Future Use" 14 "Error State" 15 "Not Available";
VAL_ 2298415346 WATT_pSpeed_Lim_Cutback_Status 0 "Inactive" 1 "Active";
VAL_ 2298415346 WATT_pMotor_Therm_Cutback 0 "Inactive" 1 "Active";
VAL_ 2298415346 WATT_pMotor_Power_Cutback_Status 0 "Inactive" 1 "Active";
VAL_ 2298415346 WATT_pI_DC_Cutback_Status 0 "Inactive" 1 "Active";
VAL_ 2298415346 WATT_pController_Therm_Cutback 0 "Inactive" 1 "Active";
VAL_ 2298415345 WATT_pSpeed_Lim_Cutback_Status 0 "Inactive" 1 "Active";
VAL_ 2298415345 WATT_pMotor_Therm_Cutback 0 "Inactive" 1 "Active";
VAL_ 2298415345 WATT_pMotor_Power_Cutback_Status 0 "Inactive" 1 "Active";
VAL_ 2298415345 WATT_pI_DC_Cutback_Status 0 "Inactive" 1 "Active";
VAL_ 2298415345 WATT_pController_Therm_Cutback 0 "Inactive" 1 "Active";
VAL_ 2298415344 WATT_pSpeed_Lim_Cutback_Status 0 "Inactive" 1 "Active";
VAL_ 2298415344 WATT_pMotor_Therm_Cutback 0 "Inactive" 1 "Active";
VAL_ 2298415344 WATT_pMotor_Power_Cutback_Status 0 "Inactive" 1 "Active";
VAL_ 2298415344 WATT_pI_DC_Cutback_Status 0 "Inactive" 1 "Active";
VAL_ 2298415344 WATT_pController_Therm_Cutback 0 "Inactive" 1 "Active";
VAL_ 2298415343 WATT_pController_Therm_Cutback 0 "Inactive" 1 "Active";
VAL_ 2298415343 WATT_pSpeed_Lim_Cutback_Status 0 "Inactive" 1 "Active";
VAL_ 2298415343 WATT_pMotor_Therm_Cutback 0 "Inactive" 1 "Active";
VAL_ 2298415343 WATT_pMotor_Power_Cutback_Status 0 "Inactive" 1 "Active";
VAL_ 2298415343 WATT_pI_DC_Cutback_Status 0 "Inactive" 1 "Active";
VAL_ 2566844672 TwoSpeedAxleSwitch 0 "LowSpeedRange" 1 "HighSpeedRange" 2 "Error" 3 "NotAvailable";
VAL_ 2566844672 ParkingBrakeSwitch 0 "NotSet" 1 "Set" 2 "Error" 3 "NotAvailable";
VAL_ 2566844672 CruiseCtrlActive 0 "SwitchedOff" 1 "SwitchedOn" 2 "Error" 3 "NotAvailable";
VAL_ 2566844672 CruiseCtrlEnableSwitch 0 "Disabled" 1 "Enabled" 2 "Error" 3 "NotAvailable";
VAL_ 2566844672 BrakeSwitch 0 "PedalReleased" 1 "PedalDepressed" 2 "Error" 3 "NotAvailable";
VAL_ 2566844672 ClutchSwitch 0 "PedalReleased" 1 "PedalDepressed" 2 "Error" 3 "NotAvailable";
VAL_ 2566844672 CruiseCtrlSetSwitch 0 "NotSet" 1 "Set" 2 "Error" 3 "NotAvailable";
VAL_ 2566844672 CruiseCtrlCoastSwitch 0 "NotCoast" 1 "Coast" 2 "Error" 3 "NotAvailable";
VAL_ 2566844672 CruiseCtrlResumeSwitch 0 "NotResume" 1 "Resume" 2 "Error" 3 "NotAvailable";
VAL_ 2566844672 CruiseCtrlAccelerateSwitch 0 "NotAccelerate" 1 "Accelerate" 2 "Error" 3 "NotAvailable";
VAL_ 2566844672 pOdometerDriveBit 0 "State A" 1 "State B" 2 "Error" 3 "Not Available/Initialize";
VAL_ 2566844672 CruiseCtrlPauseSw 0 "Off" 1 "On" 2 "Error" 3 "Take No Action";
VAL_ 2566844672 pCruiseEnableStatus 0 "Not enabled." 1 "Enabled but not activated." 2 "Reserved" 14 "Error Indicator" 15 "Not Available";
VAL_ 2364539904 EngineTorqueMode 0 "NoRequest" 1 "Accelerator Pedal" 2 "Cruise Control" 3 "PTOGovernor" 4 "Road Speed Governor" 5 "ASR Control" 6 "Transmission" 7 "ABS Control" 8 "Torque Limiting" 9 "High Speed Governor" 10 "Braking System" 11 "Remote Accelerator" 12 "Service Procedure" 13 "Not Defined" 14 "Other" 15 "Not Available";
VAL_ 2364539904 EngineStarterMode 0 "Start not requested" 1 "Starter active, gear not engaged" 2 "Starter active, gear engaged" 3 "Start finished; starter not acti" 4 "Starter inhibited due to engine " 6 "Starter inhibited due to driveli" 7 "Starter inhibited due to active " 8 "Starter inhibited due to starter" 9 "Reserved" 14 "Error" 15 "Not available";
